VERSION ""

NS_ :

BS_:

BU_: VMCU TECU OBDScanT2 IC3 EMS ECUspare2 ECUspare1 DACU CIOM BBM

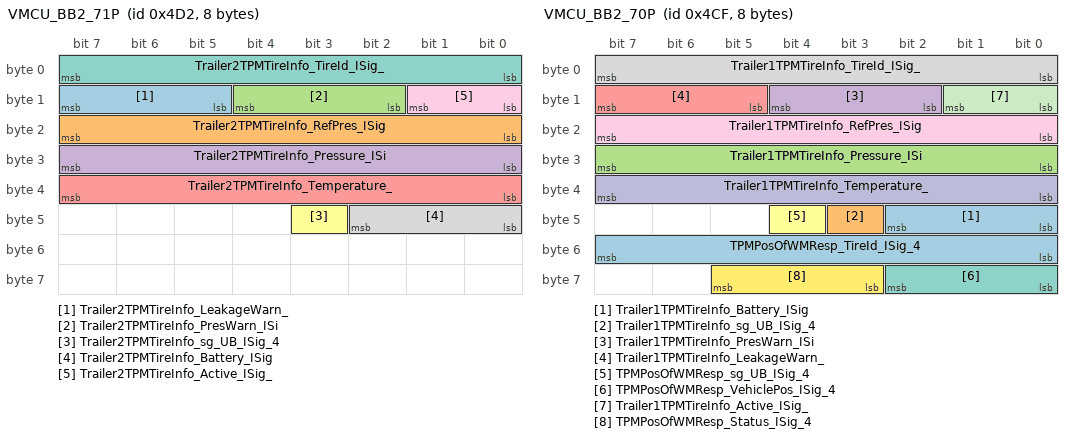
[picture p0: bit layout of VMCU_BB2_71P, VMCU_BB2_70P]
BO_ 1234 VMCU_BB2_71P: 8 VMCU
 SG_ Trailer2TPMTireInfo_LeakageWarn_ : 13|3@1+ (1,0) [0|0] ""  IC3
 SG_ Trailer2TPMTireInfo_RefPres_ISig : 16|8@1+ (10,0) [0|2550] "kPa"  IC3
 SG_ Trailer2TPMTireInfo_PresWarn_ISi : 10|3@1+ (1,0) [0|0] ""  IC3
 SG_ Trailer2TPMTireInfo_Pressure_ISi : 24|8@1+ (10,0) [0|2550] "kPa"  IC3
 SG_ Trailer2TPMTireInfo_Temperature_ : 32|8@1+ (1,-50) [-50|205] "DegreeC"  IC3
 SG_ Trailer2TPMTireInfo_sg_UB_ISig_4 : 43|1@1+ (1,0) [0|0] ""  IC3
 SG_ Trailer2TPMTireInfo_TireId_ISig_ : 0|8@1+ (1,0) [0|255] "NotApplicable"  IC3
 SG_ Trailer2TPMTireInfo_Battery_ISig : 40|3@1+ (1,0) [0|0] ""  IC3
 SG_ Trailer2TPMTireInfo_Active_ISig_ : 8|2@1+ (1,0) [0|0] ""  IC3

BO_ 1231 VMCU_BB2_70P: 8 VMCU
 SG_ Trailer1TPMTireInfo_Battery_ISig : 40|3@1+ (1,0) [0|0] ""  IC3
 SG_ Trailer1TPMTireInfo_sg_UB_ISig_4 : 43|1@1+ (1,0) [0|0] ""  IC3
 SG_ Trailer1TPMTireInfo_Pressure_ISi : 24|8@1+ (10,0) [0|2550] "kPa"  IC3
 SG_ Trailer1TPMTireInfo_PresWarn_ISi : 10|3@1+ (1,0) [0|0] ""  IC3
 SG_ Trailer1TPMTireInfo_LeakageWarn_ : 13|3@1+ (1,0) [0|0] ""  IC3
 SG_ TPMPosOfWMResp_sg_UB_ISig_4 : 44|1@1+ (1,0) [0|0] ""  IC3
 SG_ TPMPosOfWMResp_VehiclePos_ISig_4 : 56|3@1+ (1,0) [0|0] ""  IC3
 SG_ Trailer1TPMTireInfo_TireId_ISig_ : 0|8@1+ (1,0) [0|255] "NotApplicable"  IC3
 SG_ Trailer1TPMTireInfo_RefPres_ISig : 16|8@1+ (10,0) [0|2550] "kPa"  IC3
 SG_ Trailer1TPMTireInfo_Temperature_ : 32|8@1+ (1,-50) [-50|205] "DegreeC"  IC3
 SG_ Trailer1TPMTireInfo_Active_ISig_ : 8|2@1+ (1,0) [0|0] ""  IC3
 SG_ TPMPosOfWMResp_Status_ISig_4 : 59|3@1+ (1,0) [0|0] ""  IC3
 SG_ TPMPosOfWMResp_TireId_ISig_4 : 48|8@1+ (1,0) [0|255] "NotApplicable"  IC3

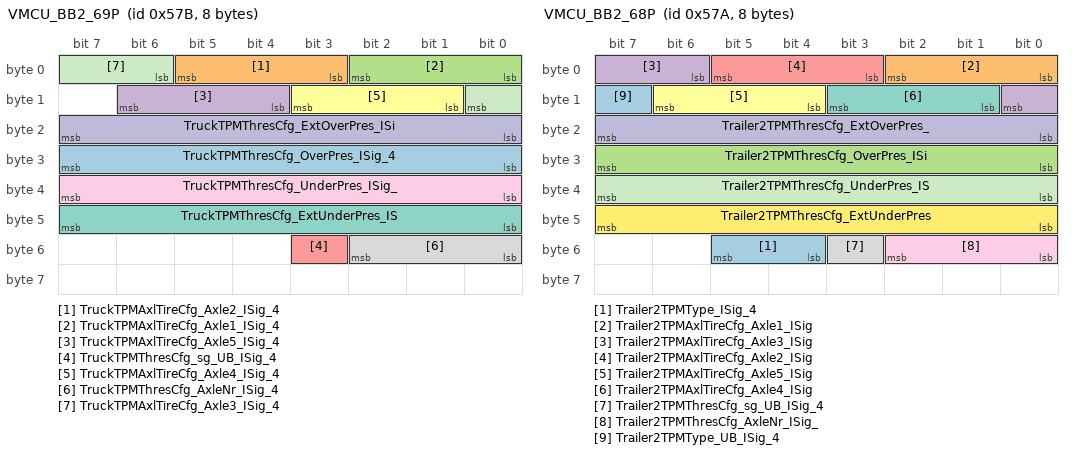
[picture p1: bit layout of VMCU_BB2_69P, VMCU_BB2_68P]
BO_ 1403 VMCU_BB2_69P: 8 VMCU
 SG_ TruckTPMThresCfg_OverPres_ISig_4 : 24|8@1+ (1,-125) [-125|130] "Percent"  IC3
 SG_ TruckTPMAxlTireCfg_Axle2_ISig_4 : 3|3@1+ (1,0) [0|0] ""  IC3
 SG_ TruckTPMAxlTireCfg_Axle1_ISig_4 : 0|3@1+ (1,0) [0|0] ""  IC3
 SG_ TruckTPMAxlTireCfg_Axle5_ISig_4 : 12|3@1+ (1,0) [0|0] ""  IC3
 SG_ TruckTPMThresCfg_sg_UB_ISig_4 : 51|1@1+ (1,0) [0|0] ""  IC3
 SG_ TruckTPMAxlTireCfg_Axle4_ISig_4 : 9|3@1+ (1,0) [0|0] ""  IC3
 SG_ TruckTPMThresCfg_ExtUnderPres_IS : 40|8@1+ (1,-125) [-125|130] "Percent"  IC3
 SG_ TruckTPMThresCfg_AxleNr_ISig_4 : 48|3@1+ (1,0) [0|0] ""  IC3
 SG_ TruckTPMThresCfg_UnderPres_ISig_ : 32|8@1+ (1,-125) [-125|130] "Percent"  IC3
 SG_ TruckTPMThresCfg_ExtOverPres_ISi : 16|8@1+ (1,-125) [-125|130] "Percent"  IC3
 SG_ TruckTPMAxlTireCfg_Axle3_ISig_4 : 6|3@1+ (1,0) [0|0] ""  IC3

BO_ 1402 VMCU_BB2_68P: 8 VMCU
 SG_ Trailer2TPMType_ISig_4 : 52|2@1+ (1,0) [0|0] ""  IC3
 SG_ Trailer2TPMAxlTireCfg_Axle1_ISig : 0|3@1+ (1,0) [0|0] ""  IC3
 SG_ Trailer2TPMThresCfg_OverPres_ISi : 24|8@1+ (1,-125) [-125|130] "Percent"  IC3
 SG_ Trailer2TPMAxlTireCfg_Axle3_ISig : 6|3@1+ (1,0) [0|0] ""  IC3
 SG_ Trailer2TPMAxlTireCfg_Axle2_ISig : 3|3@1+ (1,0) [0|0] ""  IC3
 SG_ Trailer2TPMAxlTireCfg_Axle5_ISig : 12|3@1+ (1,0) [0|0] ""  IC3
 SG_ Trailer2TPMAxlTireCfg_Axle4_ISig : 9|3@1+ (1,0) [0|0] ""  IC3
 SG_ Trailer2TPMThresCfg_sg_UB_ISig_4 : 51|1@1+ (1,0) [0|0] ""  IC3
 SG_ Trailer2TPMThresCfg_AxleNr_ISig_ : 48|3@1+ (1,0) [0|0] ""  IC3
 SG_ Trailer2TPMThresCfg_ExtOverPres_ : 16|8@1+ (1,-125) [-125|130] "Percent"  IC3
 SG_ Trailer2TPMThresCfg_UnderPres_IS : 32|8@1+ (1,-125) [-125|130] "Percent"  IC3
 SG_ Trailer2TPMThresCfg_ExtUnderPres : 40|8@1+ (1,-125) [-125|130] "Percent"  IC3
 SG_ Trailer2TPMType_UB_ISig_4 : 15|1@1+ (1,0) [0|0] ""  IC3

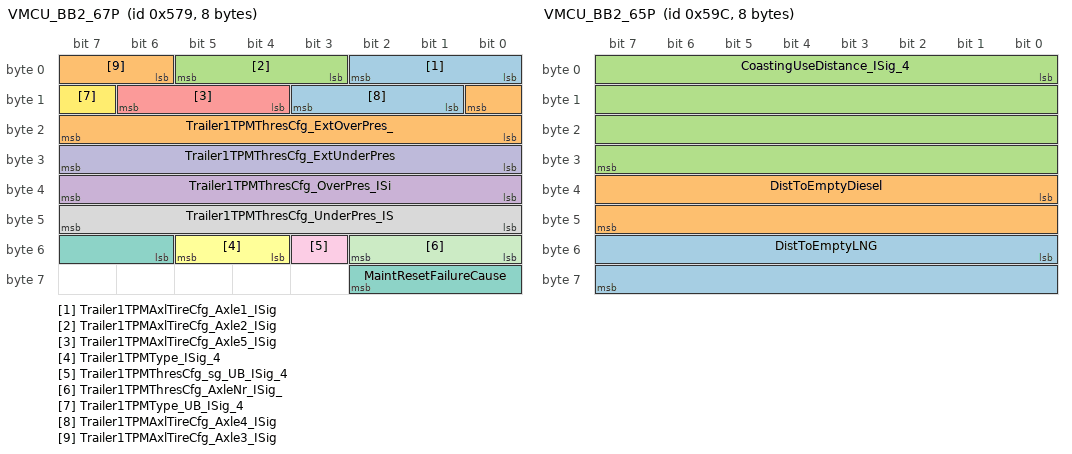
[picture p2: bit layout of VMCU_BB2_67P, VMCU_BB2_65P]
BO_ 1401 VMCU_BB2_67P: 8 VMCU
 SG_ Trailer1TPMAxlTireCfg_Axle1_ISig : 0|3@1+ (1,0) [0|0] ""  IC3
 SG_ Trailer1TPMThresCfg_ExtOverPres_ : 16|8@1+ (1,-125) [-125|130] "Percent"  IC3
 SG_ Trailer1TPMAxlTireCfg_Axle2_ISig : 3|3@1+ (1,0) [0|0] ""  IC3
 SG_ Trailer1TPMThresCfg_OverPres_ISi : 32|8@1+ (1,-125) [-125|130] "Percent"  IC3
 SG_ Trailer1TPMAxlTireCfg_Axle5_ISig : 12|3@1+ (1,0) [0|0] ""  IC3
 SG_ Trailer1TPMType_ISig_4 : 52|2@1+ (1,0) [0|0] ""  IC3
 SG_ MaintResetFailureCause : 54|5@1+ (1,0) [0|0] ""  IC3
 SG_ Trailer1TPMThresCfg_UnderPres_IS : 40|8@1+ (1,-125) [-125|130] "Percent"  IC3
 SG_ Trailer1TPMThresCfg_sg_UB_ISig_4 : 51|1@1+ (1,0) [0|0] ""  IC3
 SG_ Trailer1TPMThresCfg_ExtUnderPres : 24|8@1+ (1,-125) [-125|130] "Percent"  IC3
 SG_ Trailer1TPMThresCfg_AxleNr_ISig_ : 48|3@1+ (1,0) [0|0] ""  IC3
 SG_ Trailer1TPMType_UB_ISig_4 : 15|1@1+ (1,0) [0|0] ""  IC3
 SG_ Trailer1TPMAxlTireCfg_Axle4_ISig : 9|3@1+ (1,0) [0|0] ""  IC3
 SG_ Trailer1TPMAxlTireCfg_Axle3_ISig : 6|3@1+ (1,0) [0|0] ""  IC3

BO_ 1436 VMCU_BB2_65P: 8 VMCU
 SG_ DistToEmptyLNG : 48|16@1+ (1,0) [0|65535] "km"  IC3
 SG_ DistToEmptyDiesel : 32|16@1+ (1,0) [0|65535] "km"  IC3
 SG_ CoastingUseDistance_ISig_4 : 0|32@1+ (10,0) [0|42949672950] "m"  IC3

BO_ 1435 VMCU_BB2_64P: 8 VMCU
 SG_ EngSpeedOverThresholdTime_ISig_4 : 32|32@1+ (1,0) [0|4294967295] "s"  IC3
 SG_ EngLoadOverThresholdDistance_ISi : 0|32@1+ (10,0) [0|42949672950] "m"  IC3

BO_ 1434 VMCU_BB2_63P: 8 VMCU
 SG_ EngineGreenAreaFuel_ISig_4 : 32|32@1+ (0.01,0) [0|42949672.95] "l"  IC3
 SG_ LCCDistance_ISig_4 : 0|32@1+ (10,0) [0|42949672950] "m"  IC3

BO_ 1433 VMCU_BB2_62P: 8 VMCU
 SG_ StopCounter_ISig_4 : 0|32@1+ (1,0) [0|4294967295] ""  IC3
 SG_ OverspeedDistance_ISig_4 : 32|32@1+ (10,0) [0|42949672950] "m"  IC3

BO_ 1432 VMCU_BB2_61P: 8 VMCU
 SG_ RobotizedGboxPowerModeTime_ISig_ : 0|32@1+ (1,0) [0|4294967295] "s"  IC3
 SG_ TotalServiceBrakeCounter_ISig_4 : 32|32@1+ (1,0) [0|4294967295] ""  IC3

BO_ 1431 VMCU_BB2_60P: 8 VMCU
 SG_ RobotizedGboxManualModeTime_ISig : 32|32@1+ (1,0) [0|4294967295] "s"  IC3
 SG_ RobotizedGboxAutoModeTime_ISig_4 : 0|32@1+ (1,0) [0|4294967295] "s"  IC3

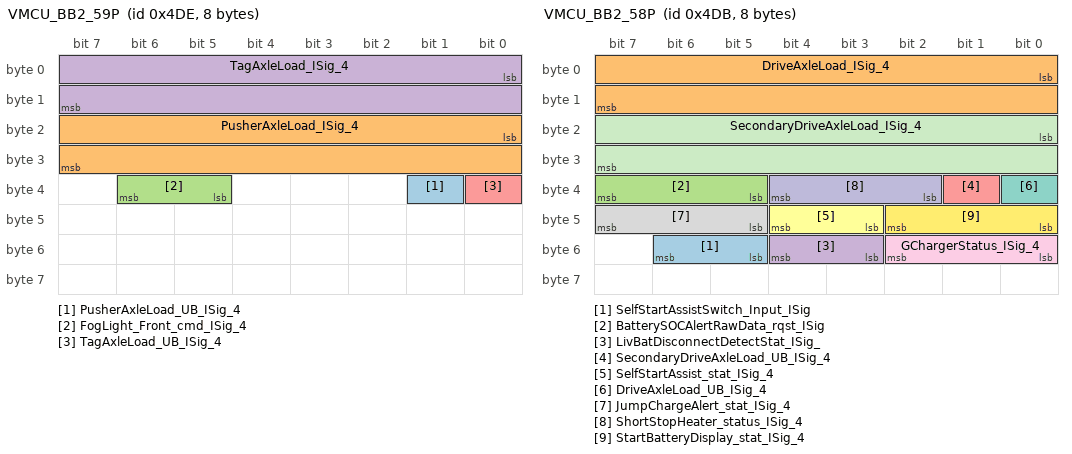
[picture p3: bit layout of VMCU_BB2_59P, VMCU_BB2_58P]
BO_ 1246 VMCU_BB2_59P: 8 VMCU
 SG_ PusherAxleLoad_UB_ISig_4 : 33|1@1+ (1,0) [0|0] ""  TECU,BBM,DACU,IC3
 SG_ PusherAxleLoad_ISig_4 : 16|16@1+ (0.5,0) [0|32767.5] "kg"  TECU,BBM,DACU
 SG_ FogLight_Front_cmd_ISig_4 : 37|2@1+ (1,0) [0|0] ""  BBM
 SG_ TagAxleLoad_ISig_4 : 0|16@1+ (0.5,0) [0|32767.5] "kg"  TECU,DACU,BBM
 SG_ TagAxleLoad_UB_ISig_4 : 32|1@1+ (1,0) [0|0] ""  BBM,IC3,DACU,TECU

BO_ 1243 VMCU_BB2_58P: 8 VMCU
 SG_ SelfStartAssistSwitch_Input_ISig : 53|2@1+ (1,0) [0|0] ""  IC3
 SG_ DriveAxleLoad_ISig_4 : 0|16@1+ (0.5,0) [0|32767.5] "kg"  BBM,DACU,TECU
 SG_ BatterySOCAlertRawData_rqst_ISig : 37|3@1+ (1,0) [0|0] ""  BBM,CIOM
 SG_ LivBatDisconnectDetectStat_ISig_ : 51|2@1+ (1,0) [0|0] ""  IC3
 SG_ SecondaryDriveAxleLoad_UB_ISig_4 : 33|1@1+ (1,0) [0|0] ""  IC3,TECU,BBM,DACU
 SG_ SelfStartAssist_stat_ISig_4 : 43|2@1+ (1,0) [0|0] ""  EMS,IC3
 SG_ DriveAxleLoad_UB_ISig_4 : 32|1@1+ (1,0) [0|0] ""  BBM,IC3,TECU,DACU
 SG_ JumpChargeAlert_stat_ISig_4 : 45|3@1+ (1,0) [0|0] ""  IC3
 SG_ GChargerStatus_ISig_4 : 48|3@1+ (1,0) [0|0] ""  IC3
 SG_ ShortStopHeater_status_ISig_4 : 34|3@1+ (1,0) [0|0] ""  CIOM
 SG_ SecondaryDriveAxleLoad_ISig_4 : 16|16@1+ (0.5,0) [0|32767.5] "kg"  DACU,BBM,TECU
 SG_ StartBatteryDisplay_stat_ISig_4 : 40|3@1+ (1,0) [0|0] ""  IC3

BO_ 1409 VMCU_BB2_57P_HMIIOM_FCM: 8 IC3
 SG_ VMCU_BB2_57P_FCS_581 : 0|64@1+ (1,0) [0|0] ""  VMCU

BO_ 1408 VMCU_BB2_57P_HMIIOM: 15 VMCU
 SG_ MaintService_ServiceCalendarTime : 32|32@1+ (1,-2147483600) [-2147483600|2147483695] "s"  IC3
 SG_ MaintService_EngTimeID_ISig_4_58 : 112|8@1+ (1,0) [0|255] "ID"  IC3
 SG_ MaintService_DistID_ISig_4_580 : 96|8@1+ (1,0) [0|255] "ID"  IC3
 SG_ MaintService_ServiceDistance_ISi : 0|32@1+ (10,-21474836000) [-21474836000|21474836950] "m"  IC3
 SG_ MaintService_ServiceEngineTime_I : 64|32@1+ (1,-2147483600) [-2147483600|2147483695] "s"  IC3
 SG_ MaintService_CalDateID_ISig_4_58 : 104|8@1+ (1,0) [0|255] "ID"  IC3

BO_ 1399 VMCU_BB2_57P_FCM: 8 CIOM
 SG_ VMCU_BB2_57P_FCS_577 : 0|64@1+ (1,0) [0|0] ""  VMCU

BO_ 1398 VMCU_BB2_57P: 15 VMCU
 SG_ MaintService_ServiceEngineT_0000 : 64|32@1+ (1,-2147483600) [-2147483600|2147483695] "s"  CIOM
 SG_ MaintService_EngTimeID_ISig_4_57 : 112|8@1+ (1,0) [0|255] "ID"  CIOM
 SG_ MaintService_DistID_ISig_4_576 : 96|8@1+ (1,0) [0|255] "ID"  CIOM
 SG_ MaintService_ServiceDistanc_0000 : 0|32@1+ (10,-21474836000) [-21474836000|21474836950] "m"  CIOM
 SG_ MaintService_CalDateID_ISig_4_57 : 104|8@1+ (1,0) [0|255] "ID"  CIOM
 SG_ MaintService_ServiceCalenda_0000 : 32|32@1+ (1,-2147483600) [-2147483600|2147483695] "s"  CIOM

BO_ 1428 VMCU_BB2_56P: 8 VMCU
 SG_ EngTrueIdleSpeedTime_ISig_4 : 0|32@1+ (1,0) [0|4294967295] "s"  IC3
 SG_ EngineGreenAreaOutTime_ISig_4 : 32|32@1+ (1,0) [0|4294967295] "s"  IC3

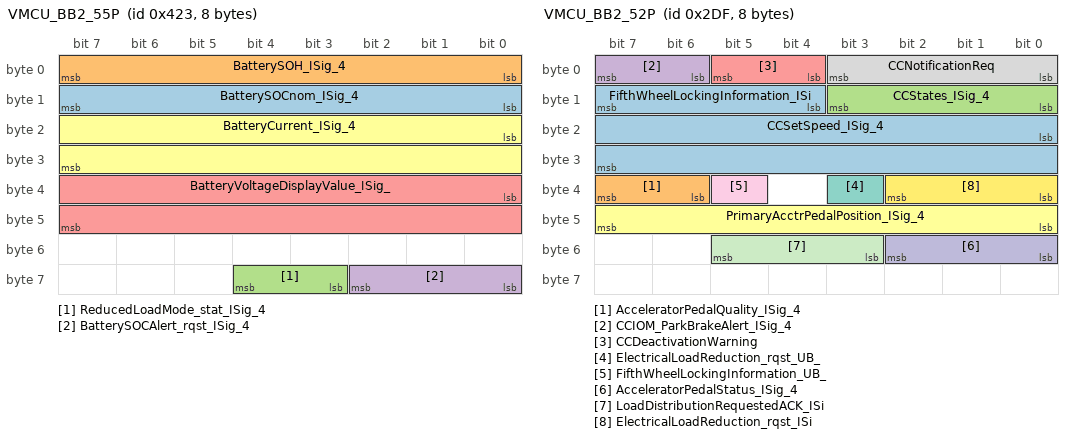
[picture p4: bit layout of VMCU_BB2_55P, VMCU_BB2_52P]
BO_ 1059 VMCU_BB2_55P: 8 VMCU
 SG_ BatterySOCnom_ISig_4 : 8|8@1+ (0.5,0) [0|127.5] "Percent"  IC3
 SG_ BatterySOH_ISig_4 : 0|8@1+ (0.5,0) [0|127.5] "Percent"  IC3
 SG_ ReducedLoadMode_stat_ISig_4 : 59|2@1+ (1,0) [0|0] ""  CIOM
 SG_ BatterySOCAlert_rqst_ISig_4 : 56|3@1+ (1,0) [0|0] ""  IC3,BBM,CIOM
 SG_ BatteryVoltageDisplayValue_ISig_ : 32|16@1+ (0.05,0) [0|3276.75] "V"  IC3,BBM
 SG_ BatteryCurrent_ISig_4 : 16|16@1+ (0.05,-1600) [-1600|1676.75] "A"  EMS,IC3

BO_ 925 VMCU_BB2_54P: 8 VMCU
 SG_ MaintOilQuality : 35|3@1+ (1,0) [0|0] ""  EMS
 SG_ ECSLimpHomeNotification_ISig_4 : 16|3@1+ (1,0) [0|0] ""  IC3
 SG_ MaintenanceResetStatus : 19|3@1+ (1,0) [0|0] ""  IC3
 SG_ FirstAxleLowerPrioSelected_ISig_ : 24|3@1+ (1,0) [0|0] ""  IC3
 SG_ MaintOilReset : 38|2@1+ (1,0) [0|0] ""  EMS
 SG_ RssInhibStartEngine_rqst : 6|2@1+ (1,0) [0|0] ""  IC3
 SG_ PositionLightRequest_status : 2|2@1+ (1,0) [0|0] ""  BBM,IC3
 SG_ ExtraBBTailLiftStatus_ISig_4 : 4|2@1+ (1,0) [0|0] ""  CIOM
 SG_ MaintenanceNotification_ISig_4 : 32|3@1+ (1,0) [0|0] ""  IC3
 SG_ ExtraBBSlidable5thWheelStatus : 0|2@1+ (1,0) [0|0] ""  BBM,CIOM
 SG_ ParkBrakeReleasePossible_stat : 10|2@1+ (1,0) [0|0] ""  TECU,IC3
 SG_ LoadDistributionALDChangeACK_ISi : 48|3@1+ (1,0) [0|0] ""  CIOM,IC3
 SG_ PoorAirPressureInfo_UB : 55|1@1+ (1,0) [0|0] ""  BBM,IC3
 SG_ ParkBrakeWorkshopMode_ISig_4 : 14|2@1+ (1,0) [0|0] ""  IC3
 SG_ ExtraBBContainerUnlockStatus : 46|2@1+ (1,0) [0|0] ""  BBM,CIOM
 SG_ MainBeamRequest_status_ISig_4 : 56|2@1+ (1,0) [0|0] ""  BBM,DACU
 SG_ ExtraBBCraneStatus_ISig_4 : 27|3@1+ (1,0) [0|0] ""  CIOM,BBM
 SG_ AirCompressorStatus : 58|2@1+ (1,0) [0|0] ""  EMS,BBM
 SG_ TrailerABSStatus_ISig_4 : 12|2@1+ (1,0) [0|0] ""  TECU,IC3,EMS,DACU
 SG_ RegenInhibitVehicleHeight_ISig_4 : 22|2@1+ (1,0) [0|0] ""  EMS
 SG_ PoorAirPressureInfo : 51|2@1+ (1,0) [0|0] ""  BBM,IC3
 SG_ FogLightRearRequest_stat : 8|2@1+ (1,0) [0|0] ""  BBM
 SG_ MainBeam_cmd_ISig_4 : 60|3@1+ (1,0) [0|0] ""  BBM
 SG_ FrontParkBrakeOverrideInd_ISig_4 : 53|2@1+ (1,0) [0|0] ""  IC3

BO_ 849 VMCU_BB2_53P: 8 VMCU
 SG_ AuxSwitchBbLoad4_cmd : 14|2@1+ (1,0) [0|0] ""  BBM
 SG_ AuxSwitchBbLoad1_Status_ISig_4 : 0|2@1+ (1,0) [0|0] ""  CIOM,BBM
 SG_ BrakeLightConvoy_rqst_UB_ISig_4 : 45|1@1+ (1,0) [0|0] ""  BBM
 SG_ AuxSwitchBbLoad3_cmd : 12|2@1+ (1,0) [0|0] ""  BBM
 SG_ MainBeam_rqst : 40|3@1+ (1,0) [0|0] ""  IC3
 SG_ BatterySOCTrustLevel_ISig_4 : 56|8@1+ (0.5,0) [0|127.5] "Percent"  IC3
 SG_ AuxSwitchBbLoad4_Status_ISig_4 : 6|2@1+ (1,0) [0|0] ""  CIOM,BBM
 SG_ BrakeLightConvoy_rqst_ISig_4 : 30|2@1+ (1,0) [0|0] ""  BBM
 SG_ DoorWarningLight_cmd_ISig_4 : 38|2@1+ (1,0) [0|0] ""  CIOM
 SG_ BlackOutandConvoyMode_rqst_ISig_ : 35|3@1+ (1,0) [0|0] ""  IC3,DACU,BBM
 SG_ DirIndicatorRqstLights_stat : 32|3@1+ (1,0) [0|0] ""  BBM
 SG_ DippedBeamRequest_status : 24|2@1+ (1,0) [0|0] ""  BBM
 SG_ AuxSwitchBbLoad3_Status_ISig_4 : 4|2@1+ (1,0) [0|0] ""  CIOM,BBM
 SG_ DoorInstepLight_cmd_ISig_4 : 43|2@1+ (1,0) [0|0] ""  CIOM
 SG_ DRLRequest_status : 26|2@1+ (1,0) [0|0] ""  BBM
 SG_ AuxSwitchBbLoad6_Status_ISig_4 : 10|2@1+ (1,0) [0|0] ""  BBM,CIOM
 SG_ AuxSwitchBbLoad2_Status_ISig_4 : 2|2@1+ (1,0) [0|0] ""  CIOM,BBM
 SG_ AuxSwitchBbLoad5_cmd : 16|2@1+ (1,0) [0|0] ""  BBM
 SG_ PBReleaseInhibit_EPBState_ISig_4 : 48|3@1+ (1,0) [0|0] ""  BBM
 SG_ ExtStaticTrailerBrake_Stat_ISig_ : 46|2@1+ (1,0) [0|0] ""  IC3,BBM
 SG_ AuxSwitchBbLoad5_Status_ISig_4 : 8|2@1+ (1,0) [0|0] ""  CIOM,BBM
 SG_ DoubleFrontAxleSteeringWarning_I : 20|2@1+ (1,0) [0|0] ""  IC3
 SG_ AuxSwitchBbLoad6_cmd : 18|2@1+ (1,0) [0|0] ""  BBM
 SG_ AcceleratorPedalTestStatus : 51|3@1+ (1,0) [0|0] ""  IC3

BO_ 735 VMCU_BB2_52P: 8 VMCU
 SG_ CCSetSpeed_ISig_4 : 16|16@1+ (0.00390625,0) [0|255.99609375] "Km_per_h"  TECU,BBM,DACU,IC3
 SG_ AcceleratorPedalQuality_ISig_4 : 38|2@1+ (1,0) [0|0] ""  BBM,IC3
 SG_ CCStates_ISig_4 : 8|4@1+ (1,0) [0|0] ""  CIOM,DACU,IC3,BBM
 SG_ CCIOM_ParkBrakeAlert_ISig_4 : 6|2@1+ (1,0) [0|0] ""  IC3
 SG_ CCDeactivationWarning : 4|2@1+ (1,0) [0|0] ""  DACU
 SG_ PrimaryAcctrPedalPosition_ISig_4 : 40|8@1+ (0.4,0) [0|102] "Percent"  BBM
 SG_ ElectricalLoadReduction_rqst_UB_ : 35|1@1+ (1,0) [0|0] ""  CIOM
 SG_ CCNotificationReq : 0|4@1+ (1,0) [0|0] ""  IC3
 SG_ FifthWheelLockingInformation_UB_ : 37|1@1+ (1,0) [0|0] ""  BBM,IC3
 SG_ AcceleratorPedalStatus_ISig_4 : 48|3@1+ (1,0) [0|0] ""  CIOM,BBM
 SG_ LoadDistributionRequestedACK_ISi : 51|3@1+ (1,0) [0|0] ""  CIOM
 SG_ ElectricalLoadReduction_rqst_ISi : 32|3@1+ (1,0) [0|0] ""  CIOM
 SG_ FifthWheelLockingInformation_ISi : 12|4@1+ (1,0) [0|0] ""  BBM,IC3

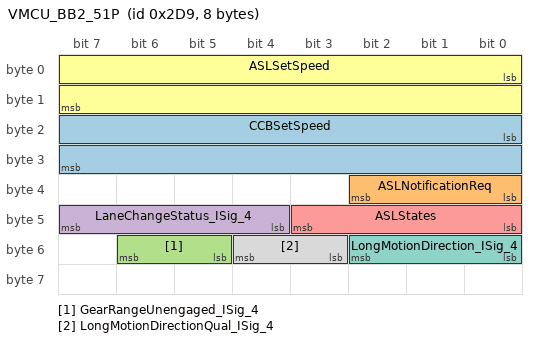
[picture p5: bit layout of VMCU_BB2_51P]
BO_ 729 VMCU_BB2_51P: 8 VMCU
 SG_ CCBSetSpeed : 16|16@1+ (0.00390625,0) [0|255.99609375] "Km_per_h"  DACU,TECU
 SG_ ASLNotificationReq : 32|3@1+ (1,0) [0|0] ""  IC3
 SG_ GearRangeUnengaged_ISig_4 : 53|2@1+ (1,0) [0|0] ""  IC3
 SG_ LaneChangeStatus_ISig_4 : 44|4@1+ (1,0) [0|0] ""  DACU,IC3
 SG_ ASLStates : 40|4@1+ (1,0) [0|0] ""  CIOM,IC3
 SG_ ASLSetSpeed : 0|16@1+ (0.00390625,0) [0|255.99609375] "Km_per_h"  IC3
 SG_ LongMotionDirection_ISig_4 : 48|3@1+ (1,0) [0|0] ""  BBM,CIOM
 SG_ LongMotionDirectionQual_ISig_4 : 51|2@1+ (1,0) [0|0] ""  CIOM

BO_ 976 VMCU_BB2_34S_FCM: 8 CIOM
 SG_ VMCU_BB2_34S_FCS : 0|64@1+ (1,0) [0|0] ""  VMCU

BO_ 973 VMCU_BB2_34S: 16 VMCU
 SG_ KeyID_KeyAuthEncrypted : 0|128@1+ (1,0) [0|0] ""  CIOM

BO_ 1418 VMCU_BB2_33S_FCM: 8 IC3
 SG_ VMCU_BB2_33S_FCS : 0|64@1+ (1,0) [0|0] ""  VMCU

CM_ SG_ 1246 PusherAxleLoad_ISig_4 "65024 - 65279 Error ; 65280 - 65535 Not available";
CM_ SG_ 1246 TagAxleLoad_ISig_4 "65024 - 65279 Error ; 65280 - 65535 Not available";
CM_ SG_ 1243 DriveAxleLoad_ISig_4 "65024 - 65279 Error ; 65280 - 65535 Not available";
CM_ SG_ 1243 SecondaryDriveAxleLoad_ISig_4 "65024 - 65279 Error ; 65280 - 65535 Not available";
CM_ SG_ 1428 EngTrueIdleSpeedTime_ISig_4 "4294967295 Not available";
CM_ SG_ 1428 EngineGreenAreaOutTime_ISig_4 "4294967295 Not available";
CM_ SG_ 1059 BatterySOCnom_ISig_4 "254 Error ; 255 Not available";
CM_ SG_ 1059 BatterySOH_ISig_4 "254 Error ; 255 Not available";
CM_ SG_ 1059 BatteryVoltageDisplayValue_ISig_ "65024 - 65279 Error ; 65280 - 65535 Not available";
CM_ SG_ 1059 BatteryCurrent_ISig_4 "65024 - 65279 Error ; 65280 - 65535 Not available";
CM_ SG_ 735 CCSetSpeed_ISig_4 "65024 - 65279 Error ; 65280 - 65535 Not available";
CM_ SG_ 729 CCBSetSpeed "65024 - 65279 Error ; 65280 - 65535 Not available";
CM_ SG_ 729 ASLSetSpeed "65024 - 65279 Error ; 65280 - 65535 Not available";
BA_DEF_ BO_  "GenMsgStartDelayTime" INT 0 0;
BA_DEF_ BO_  "GenMsgDelayTime" INT 0 0;
BA_DEF_ BO_  "GenMsgCycleTime" INT 0 0;
BA_DEF_ BO_  "GenMsgSendType" ENUM  "Cyclic","NotUsed","NotUsed","NotUsed","NotUsed","NotUsed","NotUsed","IfActive","NoMsgSendType","NotUsed";
BA_DEF_ SG_  "GenSigStartValue" INT 0 0;
BA_DEF_ SG_  "GenSigCycleTimeActive" INT 0 0;
BA_DEF_ SG_  "GenSigCycleTime" INT 0 0;
BA_DEF_ SG_  "GenSigSendType" ENUM  "Cyclic","OnWrite","OnWriteWithRepetition","OnChange","OnChangeWithRepetition","IfActive","IfActiveWithRepetition","NoSigSendType","NotUsed","NotUsed","NotUsed","NotUsed","NotUsed";
BA_DEF_ BO_  "VFrameFormat" ENUM  "StandardCAN","ExtendedCAN","reserved","J1939PG";
BA_DEF_ SG_  "SigType" ENUM  "Default","Range","RangeSigned","ASCII","Discrete","Control","ReferencePGN","DTC","StringDelimiter","StringLength","StringLengthControl";
BA_DEF_ SG_  "SeToolVersion_SIGNAL" STRING ;
BA_DEF_ SG_  "SeToolUniqueID_SIGNAL" STRING ;
BA_DEF_ SG_  "SeToolOwnerSigGroup_SIGNAL" STRING ;
BA_DEF_ SG_  "SeToolOwnerSigGroupID_SIGNAL" STRING ;
BA_DEF_ SG_  "SeToolName_SIGNAL" STRING ;
BA_DEF_ SG_  "SeToolItemID_SIGNAL" STRING ;
BA_DEF_ SG_  "SeToolAncestorID_SIGNAL" STRING ;
BA_DEF_ SG_  "Platform_VMCU1_Sig" ENUM  "No","Yes";
BA_DEF_ BO_  "NmAsrMessage" ENUM  "No","Yes";
BA_DEF_ SG_  "NeedsUpdateBit" ENUM  "No","Yes";
BA_DEF_ SG_  "MmAnSignal" ENUM  "No","Yes";
BA_DEF_ SG_  "GenSigMaxLatency" INT 0 65535;
BA_DEF_ SG_  "GenSigILSupport" ENUM  "Yes","No";
BA_DEF_ BO_  "GenMsgRequestable" INT 0 1;
BA_DEF_ BO_  "GenMsgILSupport" ENUM  "No","Yes";
BA_DEF_ BO_  "DiagUUDTResponse" ENUM  "No","Yes";
BA_DEF_ BO_  "DiagState" ENUM  "No","Yes";
BA_DEF_ BO_  "DiagResponse" ENUM  "No","Yes";
BA_DEF_ BO_  "DiagRequest" ENUM  "No","Yes";
BA_DEF_ BO_  "DiagConnection" HEX 0 65535;
BA_DEF_ BO_  "CanTpSTmin" INT 0 255;
BA_DEF_ BO_  "CanTpFcFrameId" HEX 0 2147483647;
BA_DEF_ BO_  "CanTpBs" INT 0 255;
BA_DEF_ SG_  "SystemSignalLongSymbol" STRING ;
BA_DEF_REL_ BU_SG_REL_  "GenSigTimeoutTime" INT 0 65535;
BA_DEF_REL_ BU_SG_REL_  "GenSigFirstTimeoutTime" INT 0 65535;
BA_DEF_DEF_  "GenMsgStartDelayTime" 0;
BA_DEF_DEF_  "GenMsgDelayTime" 0;
BA_DEF_DEF_  "GenMsgCycleTime" 0;
BA_DEF_DEF_  "GenMsgSendType" "Cyclic";
BA_DEF_DEF_  "GenSigStartValue" 0;
BA_DEF_DEF_  "GenSigCycleTimeActive" 0;
BA_DEF_DEF_  "GenSigCycleTime" 0;
BA_DEF_DEF_  "GenSigSendType" "Cyclic";
BA_DEF_DEF_  "VFrameFormat" "ExtendedCAN";
BA_DEF_DEF_  "SigType" "Default";
BA_DEF_DEF_  "SeToolVersion_SIGNAL" "";
BA_DEF_DEF_  "SeToolUniqueID_SIGNAL" "";
BA_DEF_DEF_  "SeToolOwnerSigGroup_SIGNAL" "";
BA_DEF_DEF_  "SeToolOwnerSigGroupID_SIGNAL" "";
BA_DEF_DEF_  "SeToolName_SIGNAL" "";
BA_DEF_DEF_  "SeToolItemID_SIGNAL" "";
BA_DEF_DEF_  "SeToolAncestorID_SIGNAL" "";
BA_DEF_DEF_  "Platform_VMCU1_Sig" "No";
BA_DEF_DEF_  "NmAsrMessage" "No";
BA_DEF_DEF_  "NeedsUpdateBit" "No";
BA_DEF_DEF_  "MmAnSignal" "No";
BA_DEF_DEF_  "GenSigMaxLatency" 0;
BA_DEF_DEF_  "GenSigILSupport" "Yes";
BA_DEF_DEF_  "GenMsgRequestable" 1;
BA_DEF_DEF_  "GenMsgILSupport" "Yes";
BA_DEF_DEF_  "DiagUUDTResponse" "No";
BA_DEF_DEF_  "DiagState" "No";
BA_DEF_DEF_  "DiagResponse" "No";
BA_DEF_DEF_  "DiagRequest" "No";
BA_DEF_DEF_  "DiagConnection" 0;
BA_DEF_DEF_  "CanTpSTmin" 0;
BA_DEF_DEF_  "CanTpFcFrameId" 2147483647;
BA_DEF_DEF_  "CanTpBs" 255;
BA_DEF_DEF_REL_ "GenSigTimeoutTime" 0;
BA_DEF_DEF_REL_ "GenSigFirstTimeoutTime" 0;
BA_DEF_DEF_  "SystemSignalLongSymbol" "";
BA_ "VFrameFormat" BO_ 1234 0;
BA_ "GenMsgCycleTime" BO_ 1234 200;
BA_ "GenMsgStartDelayTime" BO_ 1234 120;
BA_ "VFrameFormat" BO_ 1231 0;
BA_ "GenMsgCycleTime" BO_ 1231 200;
BA_ "GenMsgStartDelayTime" BO_ 1231 140;
BA_ "VFrameFormat" BO_ 1403 0;
BA_ "GenMsgCycleTime" BO_ 1403 1000;
BA_ "GenMsgStartDelayTime" BO_ 1403 280;
BA_ "VFrameFormat" BO_ 1402 0;
BA_ "GenMsgCycleTime" BO_ 1402 1000;
BA_ "GenMsgStartDelayTime" BO_ 1402 320;
BA_ "VFrameFormat" BO_ 1401 0;
BA_ "GenMsgCycleTime" BO_ 1401 1000;
BA_ "GenMsgStartDelayTime" BO_ 1401 350;
BA_ "VFrameFormat" BO_ 1436 0;
BA_ "GenMsgCycleTime" BO_ 1436 1000;
BA_ "GenMsgStartDelayTime" BO_ 1436 345;
BA_ "VFrameFormat" BO_ 1435 0;
BA_ "GenMsgCycleTime" BO_ 1435 1000;
BA_ "GenMsgStartDelayTime" BO_ 1435 230;
BA_ "VFrameFormat" BO_ 1434 0;
BA_ "GenMsgCycleTime" BO_ 1434 1000;
BA_ "GenMsgStartDelayTime" BO_ 1434 155;
BA_ "VFrameFormat" BO_ 1433 0;
BA_ "GenMsgCycleTime" BO_ 1433 1000;
BA_ "GenMsgStartDelayTime" BO_ 1433 110;
BA_ "VFrameFormat" BO_ 1432 0;
BA_ "GenMsgCycleTime" BO_ 1432 1000;
BA_ "GenMsgStartDelayTime" BO_ 1432 720;
BA_ "VFrameFormat" BO_ 1431 0;
BA_ "GenMsgCycleTime" BO_ 1431 1000;
BA_ "GenMsgStartDelayTime" BO_ 1431 680;
BA_ "VFrameFormat" BO_ 1246 0;
BA_ "GenMsgCycleTime" BO_ 1246 250;
BA_ "GenMsgStartDelayTime" BO_ 1246 105;
BA_ "VFrameFormat" BO_ 1243 0;
BA_ "GenMsgCycleTime" BO_ 1243 250;
BA_ "GenMsgStartDelayTime" BO_ 1243 75;
BA_ "GenMsgILSupport" BO_ 1409 0;
BA_ "VFrameFormat" BO_ 1409 0;
BA_ "GenMsgSendType" BO_ 1409 8;
BA_ "CanTpFcFrameId" BO_ 1408 1409;
BA_ "VFrameFormat" BO_ 1408 0;
BA_ "GenMsgCycleTime" BO_ 1408 1000;
BA_ "GenMsgStartDelayTime" BO_ 1408 200;
BA_ "GenMsgILSupport" BO_ 1399 0;
BA_ "VFrameFormat" BO_ 1399 0;
BA_ "GenMsgSendType" BO_ 1399 8;
BA_ "CanTpFcFrameId" BO_ 1398 1399;
BA_ "VFrameFormat" BO_ 1398 0;
BA_ "GenMsgCycleTime" BO_ 1398 1000;
BA_ "GenMsgStartDelayTime" BO_ 1398 175;
BA_ "VFrameFormat" BO_ 1428 0;
BA_ "GenMsgCycleTime" BO_ 1428 1000;
BA_ "GenMsgStartDelayTime" BO_ 1428 170;
BA_ "VFrameFormat" BO_ 1059 0;
BA_ "GenMsgCycleTime" BO_ 1059 150;
BA_ "GenMsgStartDelayTime" BO_ 1059 65;
BA_ "VFrameFormat" BO_ 925 0;
BA_ "GenMsgCycleTime" BO_ 925 75;
BA_ "GenMsgStartDelayTime" BO_ 925 20;
BA_ "VFrameFormat" BO_ 849 0;
BA_ "GenMsgCycleTime" BO_ 849 50;
BA_ "GenMsgStartDelayTime" BO_ 849 15;
BA_ "VFrameFormat" BO_ 735 0;
BA_ "GenMsgCycleTime" BO_ 735 35;
BA_ "VFrameFormat" BO_ 729 0;
BA_ "GenMsgCycleTime" BO_ 729 30;
BA_ "GenMsgStartDelayTime" BO_ 729 15;
BA_ "GenMsgILSupport" BO_ 976 0;
BA_ "VFrameFormat" BO_ 976 0;
BA_ "GenMsgSendType" BO_ 976 8;
BA_ "CanTpFcFrameId" BO_ 973 976;
BA_ "VFrameFormat" BO_ 973 0;
BA_ "GenMsgSendType" BO_ 973 8;
BA_ "GenMsgDelayTime" BO_ 973 80;
BA_ "CanTpSTmin" BO_ 1418 5;
BA_ "GenMsgILSupport" BO_ 1418 0;
BA_ "VFrameFormat" BO_ 1418 0;
BA_ "GenMsgSendType" BO_ 1418 8;
BA_ "GenSigCycleTime" SG_ 1234 Trailer2TPMTireInfo_LeakageWarn_ 100;
BA_ "GenSigCycleTimeActive" SG_ 1234 Trailer2TPMTireInfo_LeakageWarn_ 100;
BA_ "GenSigStartValue" SG_ 1234 Trailer2TPMTireInfo_LeakageWarn_ 7;
BA_ "NeedsUpdateBit" SG_ 1234 Trailer2TPMTireInfo_LeakageWarn_ 1;
BA_ "Platform_VMCU1_Sig" SG_ 1234 Trailer2TPMTireInfo_LeakageWarn_ 1;
BA_ "SystemSignalLongSymbol" SG_ 1234 Trailer2TPMTireInfo_LeakageWarn_ "Trailer2TPMTireInfo_LeakageWarn_ISig_4";
BA_ "GenSigCycleTime" SG_ 1234 Trailer2TPMTireInfo_RefPres_ISig 100;
BA_ "GenSigCycleTimeActive" SG_ 1234 Trailer2TPMTireInfo_RefPres_ISig 100;
BA_ "GenSigStartValue" SG_ 1234 Trailer2TPMTireInfo_RefPres_ISig 255;
BA_ "NeedsUpdateBit" SG_ 1234 Trailer2TPMTireInfo_RefPres_ISig 1;
BA_ "Platform_VMCU1_Sig" SG_ 1234 Trailer2TPMTireInfo_RefPres_ISig 1;
BA_ "SystemSignalLongSymbol" SG_ 1234 Trailer2TPMTireInfo_RefPres_ISig "Trailer2TPMTireInfo_RefPres_ISig_4";
BA_ "GenSigCycleTime" SG_ 1234 Trailer2TPMTireInfo_PresWarn_ISi 100;
BA_ "GenSigCycleTimeActive" SG_ 1234 Trailer2TPMTireInfo_PresWarn_ISi 100;
BA_ "GenSigStartValue" SG_ 1234 Trailer2TPMTireInfo_PresWarn_ISi 7;
BA_ "NeedsUpdateBit" SG_ 1234 Trailer2TPMTireInfo_PresWarn_ISi 1;
BA_ "Platform_VMCU1_Sig" SG_ 1234 Trailer2TPMTireInfo_PresWarn_ISi 1;
BA_ "SystemSignalLongSymbol" SG_ 1234 Trailer2TPMTireInfo_PresWarn_ISi "Trailer2TPMTireInfo_PresWarn_ISig_4";
BA_ "GenSigCycleTime" SG_ 1234 Trailer2TPMTireInfo_Pressure_ISi 100;
BA_ "GenSigCycleTimeActive" SG_ 1234 Trailer2TPMTireInfo_Pressure_ISi 100;
BA_ "GenSigStartValue" SG_ 1234 Trailer2TPMTireInfo_Pressure_ISi 255;
BA_ "NeedsUpdateBit" SG_ 1234 Trailer2TPMTireInfo_Pressure_ISi 1;
BA_ "Platform_VMCU1_Sig" SG_ 1234 Trailer2TPMTireInfo_Pressure_ISi 1;
BA_ "SystemSignalLongSymbol" SG_ 1234 Trailer2TPMTireInfo_Pressure_ISi "Trailer2TPMTireInfo_Pressure_ISig_4";
BA_ "GenSigCycleTime" SG_ 1234 Trailer2TPMTireInfo_Temperature_ 100;
BA_ "GenSigCycleTimeActive" SG_ 1234 Trailer2TPMTireInfo_Temperature_ 100;
BA_ "GenSigStartValue" SG_ 1234 Trailer2TPMTireInfo_Temperature_ 255;
BA_ "NeedsUpdateBit" SG_ 1234 Trailer2TPMTireInfo_Temperature_ 1;
BA_ "Platform_VMCU1_Sig" SG_ 1234 Trailer2TPMTireInfo_Temperature_ 1;
BA_ "SystemSignalLongSymbol" SG_ 1234 Trailer2TPMTireInfo_Temperature_ "Trailer2TPMTireInfo_Temperature_ISig_4";
BA_ "GenSigSendType" SG_ 1234 Trailer2TPMTireInfo_sg_UB_ISig_4 7;
BA_ "GenSigCycleTime" SG_ 1234 Trailer2TPMTireInfo_sg_UB_ISig_4 100;
BA_ "GenSigCycleTimeActive" SG_ 1234 Trailer2TPMTireInfo_sg_UB_ISig_4 100;
BA_ "Platform_VMCU1_Sig" SG_ 1234 Trailer2TPMTireInfo_sg_UB_ISig_4 1;
BA_ "GenSigCycleTime" SG_ 1234 Trailer2TPMTireInfo_TireId_ISig_ 100;
BA_ "GenSigCycleTimeActive" SG_ 1234 Trailer2TPMTireInfo_TireId_ISig_ 100;
BA_ "NeedsUpdateBit" SG_ 1234 Trailer2TPMTireInfo_TireId_ISig_ 1;
BA_ "Platform_VMCU1_Sig" SG_ 1234 Trailer2TPMTireInfo_TireId_ISig_ 1;
BA_ "SystemSignalLongSymbol" SG_ 1234 Trailer2TPMTireInfo_TireId_ISig_ "Trailer2TPMTireInfo_TireId_ISig_4";
BA_ "GenSigCycleTime" SG_ 1234 Trailer2TPMTireInfo_Battery_ISig 100;
BA_ "GenSigCycleTimeActive" SG_ 1234 Trailer2TPMTireInfo_Battery_ISig 100;
BA_ "GenSigStartValue" SG_ 1234 Trailer2TPMTireInfo_Battery_ISig 7;
BA_ "NeedsUpdateBit" SG_ 1234 Trailer2TPMTireInfo_Battery_ISig 1;
BA_ "Platform_VMCU1_Sig" SG_ 1234 Trailer2TPMTireInfo_Battery_ISig 1;
BA_ "SystemSignalLongSymbol" SG_ 1234 Trailer2TPMTireInfo_Battery_ISig "Trailer2TPMTireInfo_Battery_ISig_4";
BA_ "GenSigCycleTime" SG_ 1234 Trailer2TPMTireInfo_Active_ISig_ 100;
BA_ "GenSigCycleTimeActive" SG_ 1234 Trailer2TPMTireInfo_Active_ISig_ 100;
BA_ "GenSigStartValue" SG_ 1234 Trailer2TPMTireInfo_Active_ISig_ 3;
BA_ "NeedsUpdateBit" SG_ 1234 Trailer2TPMTireInfo_Active_ISig_ 1;
BA_ "Platform_VMCU1_Sig" SG_ 1234 Trailer2TPMTireInfo_Active_ISig_ 1;
BA_ "SystemSignalLongSymbol" SG_ 1234 Trailer2TPMTireInfo_Active_ISig_ "Trailer2TPMTireInfo_Active_ISig_4";
BA_ "GenSigCycleTime" SG_ 1231 Trailer1TPMTireInfo_Battery_ISig 100;
BA_ "GenSigCycleTimeActive" SG_ 1231 Trailer1TPMTireInfo_Battery_ISig 100;
BA_ "GenSigStartValue" SG_ 1231 Trailer1TPMTireInfo_Battery_ISig 7;
BA_ "NeedsUpdateBit" SG_ 1231 Trailer1TPMTireInfo_Battery_ISig 1;
BA_ "Platform_VMCU1_Sig" SG_ 1231 Trailer1TPMTireInfo_Battery_ISig 1;
BA_ "SystemSignalLongSymbol" SG_ 1231 Trailer1TPMTireInfo_Battery_ISig "Trailer1TPMTireInfo_Battery_ISig_4";
BA_ "GenSigSendType" SG_ 1231 Trailer1TPMTireInfo_sg_UB_ISig_4 7;
BA_ "GenSigCycleTime" SG_ 1231 Trailer1TPMTireInfo_sg_UB_ISig_4 100;
BA_ "GenSigCycleTimeActive" SG_ 1231 Trailer1TPMTireInfo_sg_UB_ISig_4 100;
BA_ "Platform_VMCU1_Sig" SG_ 1231 Trailer1TPMTireInfo_sg_UB_ISig_4 1;
BA_ "GenSigCycleTime" SG_ 1231 Trailer1TPMTireInfo_Pressure_ISi 100;
BA_ "GenSigCycleTimeActive" SG_ 1231 Trailer1TPMTireInfo_Pressure_ISi 100;
BA_ "GenSigStartValue" SG_ 1231 Trailer1TPMTireInfo_Pressure_ISi 255;
BA_ "NeedsUpdateBit" SG_ 1231 Trailer1TPMTireInfo_Pressure_ISi 1;
BA_ "Platform_VMCU1_Sig" SG_ 1231 Trailer1TPMTireInfo_Pressure_ISi 1;
BA_ "SystemSignalLongSymbol" SG_ 1231 Trailer1TPMTireInfo_Pressure_ISi "Trailer1TPMTireInfo_Pressure_ISig_4";
BA_ "GenSigCycleTime" SG_ 1231 Trailer1TPMTireInfo_PresWarn_ISi 100;
BA_ "GenSigCycleTimeActive" SG_ 1231 Trailer1TPMTireInfo_PresWarn_ISi 100;
BA_ "GenSigStartValue" SG_ 1231 Trailer1TPMTireInfo_PresWarn_ISi 7;
BA_ "NeedsUpdateBit" SG_ 1231 Trailer1TPMTireInfo_PresWarn_ISi 1;
BA_ "Platform_VMCU1_Sig" SG_ 1231 Trailer1TPMTireInfo_PresWarn_ISi 1;
BA_ "SystemSignalLongSymbol" SG_ 1231 Trailer1TPMTireInfo_PresWarn_ISi "Trailer1TPMTireInfo_PresWarn_ISig_4";
BA_ "GenSigCycleTime" SG_ 1231 Trailer1TPMTireInfo_LeakageWarn_ 100;
BA_ "GenSigCycleTimeActive" SG_ 1231 Trailer1TPMTireInfo_LeakageWarn_ 100;
BA_ "GenSigStartValue" SG_ 1231 Trailer1TPMTireInfo_LeakageWarn_ 7;
BA_ "NeedsUpdateBit" SG_ 1231 Trailer1TPMTireInfo_LeakageWarn_ 1;
BA_ "Platform_VMCU1_Sig" SG_ 1231 Trailer1TPMTireInfo_LeakageWarn_ 1;
BA_ "SystemSignalLongSymbol" SG_ 1231 Trailer1TPMTireInfo_LeakageWarn_ "Trailer1TPMTireInfo_LeakageWarn_ISig_4";
BA_ "GenSigSendType" SG_ 1231 TPMPosOfWMResp_sg_UB_ISig_4 7;
BA_ "GenSigCycleTime" SG_ 1231 TPMPosOfWMResp_sg_UB_ISig_4 100;
BA_ "GenSigCycleTimeActive" SG_ 1231 TPMPosOfWMResp_sg_UB_ISig_4 100;
BA_ "Platform_VMCU1_Sig" SG_ 1231 TPMPosOfWMResp_sg_UB_ISig_4 1;
BA_ "GenSigCycleTime" SG_ 1231 TPMPosOfWMResp_VehiclePos_ISig_4 100;
BA_ "GenSigCycleTimeActive" SG_ 1231 TPMPosOfWMResp_VehiclePos_ISig_4 100;
BA_ "GenSigStartValue" SG_ 1231 TPMPosOfWMResp_VehiclePos_ISig_4 7;
BA_ "NeedsUpdateBit" SG_ 1231 TPMPosOfWMResp_VehiclePos_ISig_4 1;
BA_ "Platform_VMCU1_Sig" SG_ 1231 TPMPosOfWMResp_VehiclePos_ISig_4 1;
BA_ "GenSigCycleTime" SG_ 1231 Trailer1TPMTireInfo_TireId_ISig_ 100;
BA_ "GenSigCycleTimeActive" SG_ 1231 Trailer1TPMTireInfo_TireId_ISig_ 100;
BA_ "NeedsUpdateBit" SG_ 1231 Trailer1TPMTireInfo_TireId_ISig_ 1;
BA_ "Platform_VMCU1_Sig" SG_ 1231 Trailer1TPMTireInfo_TireId_ISig_ 1;
BA_ "SystemSignalLongSymbol" SG_ 1231 Trailer1TPMTireInfo_TireId_ISig_ "Trailer1TPMTireInfo_TireId_ISig_4";
BA_ "GenSigCycleTime" SG_ 1231 Trailer1TPMTireInfo_RefPres_ISig 100;
BA_ "GenSigCycleTimeActive" SG_ 1231 Trailer1TPMTireInfo_RefPres_ISig 100;
BA_ "GenSigStartValue" SG_ 1231 Trailer1TPMTireInfo_RefPres_ISig 255;
BA_ "NeedsUpdateBit" SG_ 1231 Trailer1TPMTireInfo_RefPres_ISig 1;
BA_ "Platform_VMCU1_Sig" SG_ 1231 Trailer1TPMTireInfo_RefPres_ISig 1;
BA_ "SystemSignalLongSymbol" SG_ 1231 Trailer1TPMTireInfo_RefPres_ISig "Trailer1TPMTireInfo_RefPres_ISig_4";
BA_ "GenSigCycleTime" SG_ 1231 Trailer1TPMTireInfo_Temperature_ 100;
BA_ "GenSigCycleTimeActive" SG_ 1231 Trailer1TPMTireInfo_Temperature_ 100;
BA_ "GenSigStartValue" SG_ 1231 Trailer1TPMTireInfo_Temperature_ 255;
BA_ "NeedsUpdateBit" SG_ 1231 Trailer1TPMTireInfo_Temperature_ 1;
BA_ "Platform_VMCU1_Sig" SG_ 1231 Trailer1TPMTireInfo_Temperature_ 1;
BA_ "SystemSignalLongSymbol" SG_ 1231 Trailer1TPMTireInfo_Temperature_ "Trailer1TPMTireInfo_Temperature_ISig_4";
BA_ "GenSigCycleTime" SG_ 1231 Trailer1TPMTireInfo_Active_ISig_ 100;
BA_ "GenSigCycleTimeActive" SG_ 1231 Trailer1TPMTireInfo_Active_ISig_ 100;
BA_ "GenSigStartValue" SG_ 1231 Trailer1TPMTireInfo_Active_ISig_ 3;
BA_ "NeedsUpdateBit" SG_ 1231 Trailer1TPMTireInfo_Active_ISig_ 1;
BA_ "Platform_VMCU1_Sig" SG_ 1231 Trailer1TPMTireInfo_Active_ISig_ 1;
BA_ "SystemSignalLongSymbol" SG_ 1231 Trailer1TPMTireInfo_Active_ISig_ "Trailer1TPMTireInfo_Active_ISig_4";
BA_ "GenSigCycleTime" SG_ 1231 TPMPosOfWMResp_Status_ISig_4 100;
BA_ "GenSigCycleTimeActive" SG_ 1231 TPMPosOfWMResp_Status_ISig_4 100;
BA_ "GenSigStartValue" SG_ 1231 TPMPosOfWMResp_Status_ISig_4 7;
BA_ "NeedsUpdateBit" SG_ 1231 TPMPosOfWMResp_Status_ISig_4 1;
BA_ "Platform_VMCU1_Sig" SG_ 1231 TPMPosOfWMResp_Status_ISig_4 1;
BA_ "GenSigCycleTime" SG_ 1231 TPMPosOfWMResp_TireId_ISig_4 100;
BA_ "GenSigCycleTimeActive" SG_ 1231 TPMPosOfWMResp_TireId_ISig_4 100;
BA_ "NeedsUpdateBit" SG_ 1231 TPMPosOfWMResp_TireId_ISig_4 1;
BA_ "Platform_VMCU1_Sig" SG_ 1231 TPMPosOfWMResp_TireId_ISig_4 1;
BA_ "GenSigCycleTime" SG_ 1403 TruckTPMThresCfg_OverPres_ISig_4 100;
BA_ "GenSigCycleTimeActive" SG_ 1403 TruckTPMThresCfg_OverPres_ISig_4 100;
BA_ "GenSigStartValue" SG_ 1403 TruckTPMThresCfg_OverPres_ISig_4 255;
BA_ "NeedsUpdateBit" SG_ 1403 TruckTPMThresCfg_OverPres_ISig_4 1;
BA_ "Platform_VMCU1_Sig" SG_ 1403 TruckTPMThresCfg_OverPres_ISig_4 1;
BA_ "GenSigCycleTime" SG_ 1403 TruckTPMAxlTireCfg_Axle2_ISig_4 100;
BA_ "GenSigCycleTimeActive" SG_ 1403 TruckTPMAxlTireCfg_Axle2_ISig_4 100;
BA_ "GenSigStartValue" SG_ 1403 TruckTPMAxlTireCfg_Axle2_ISig_4 7;
BA_ "Platform_VMCU1_Sig" SG_ 1403 TruckTPMAxlTireCfg_Axle2_ISig_4 1;
BA_ "GenSigCycleTime" SG_ 1403 TruckTPMAxlTireCfg_Axle1_ISig_4 100;
BA_ "GenSigCycleTimeActive" SG_ 1403 TruckTPMAxlTireCfg_Axle1_ISig_4 100;
BA_ "GenSigStartValue" SG_ 1403 TruckTPMAxlTireCfg_Axle1_ISig_4 7;
BA_ "Platform_VMCU1_Sig" SG_ 1403 TruckTPMAxlTireCfg_Axle1_ISig_4 1;
BA_ "GenSigCycleTime" SG_ 1403 TruckTPMAxlTireCfg_Axle5_ISig_4 100;
BA_ "GenSigCycleTimeActive" SG_ 1403 TruckTPMAxlTireCfg_Axle5_ISig_4 100;
BA_ "GenSigStartValue" SG_ 1403 TruckTPMAxlTireCfg_Axle5_ISig_4 7;
BA_ "Platform_VMCU1_Sig" SG_ 1403 TruckTPMAxlTireCfg_Axle5_ISig_4 1;
BA_ "GenSigSendType" SG_ 1403 TruckTPMThresCfg_sg_UB_ISig_4 7;
BA_ "GenSigCycleTime" SG_ 1403 TruckTPMThresCfg_sg_UB_ISig_4 100;
BA_ "GenSigCycleTimeActive" SG_ 1403 TruckTPMThresCfg_sg_UB_ISig_4 100;
BA_ "Platform_VMCU1_Sig" SG_ 1403 TruckTPMThresCfg_sg_UB_ISig_4 1;
BA_ "GenSigCycleTime" SG_ 1403 TruckTPMAxlTireCfg_Axle4_ISig_4 100;
BA_ "GenSigCycleTimeActive" SG_ 1403 TruckTPMAxlTireCfg_Axle4_ISig_4 100;
BA_ "GenSigStartValue" SG_ 1403 TruckTPMAxlTireCfg_Axle4_ISig_4 7;
BA_ "Platform_VMCU1_Sig" SG_ 1403 TruckTPMAxlTireCfg_Axle4_ISig_4 1;
BA_ "GenSigCycleTime" SG_ 1403 TruckTPMThresCfg_ExtUnderPres_IS 100;
BA_ "GenSigCycleTimeActive" SG_ 1403 TruckTPMThresCfg_ExtUnderPres_IS 100;
BA_ "GenSigStartValue" SG_ 1403 TruckTPMThresCfg_ExtUnderPres_IS 255;
BA_ "NeedsUpdateBit" SG_ 1403 TruckTPMThresCfg_ExtUnderPres_IS 1;
BA_ "Platform_VMCU1_Sig" SG_ 1403 TruckTPMThresCfg_ExtUnderPres_IS 1;
BA_ "SystemSignalLongSymbol" SG_ 1403 TruckTPMThresCfg_ExtUnderPres_IS "TruckTPMThresCfg_ExtUnderPres_ISig_4";
BA_ "GenSigCycleTime" SG_ 1403 TruckTPMThresCfg_AxleNr_ISig_4 100;
BA_ "GenSigCycleTimeActive" SG_ 1403 TruckTPMThresCfg_AxleNr_ISig_4 100;
BA_ "GenSigStartValue" SG_ 1403 TruckTPMThresCfg_AxleNr_ISig_4 7;
BA_ "NeedsUpdateBit" SG_ 1403 TruckTPMThresCfg_AxleNr_ISig_4 1;
BA_ "Platform_VMCU1_Sig" SG_ 1403 TruckTPMThresCfg_AxleNr_ISig_4 1;
BA_ "GenSigCycleTime" SG_ 1403 TruckTPMThresCfg_UnderPres_ISig_ 100;
BA_ "GenSigCycleTimeActive" SG_ 1403 TruckTPMThresCfg_UnderPres_ISig_ 100;
BA_ "GenSigStartValue" SG_ 1403 TruckTPMThresCfg_UnderPres_ISig_ 255;
BA_ "NeedsUpdateBit" SG_ 1403 TruckTPMThresCfg_UnderPres_ISig_ 1;
BA_ "Platform_VMCU1_Sig" SG_ 1403 TruckTPMThresCfg_UnderPres_ISig_ 1;
BA_ "SystemSignalLongSymbol" SG_ 1403 TruckTPMThresCfg_UnderPres_ISig_ "TruckTPMThresCfg_UnderPres_ISig_4";
BA_ "GenSigCycleTime" SG_ 1403 TruckTPMThresCfg_ExtOverPres_ISi 100;
BA_ "GenSigCycleTimeActive" SG_ 1403 TruckTPMThresCfg_ExtOverPres_ISi 100;
BA_ "GenSigStartValue" SG_ 1403 TruckTPMThresCfg_ExtOverPres_ISi 255;
BA_ "NeedsUpdateBit" SG_ 1403 TruckTPMThresCfg_ExtOverPres_ISi 1;
BA_ "Platform_VMCU1_Sig" SG_ 1403 TruckTPMThresCfg_ExtOverPres_ISi 1;
BA_ "SystemSignalLongSymbol" SG_ 1403 TruckTPMThresCfg_ExtOverPres_ISi "TruckTPMThresCfg_ExtOverPres_ISig_4";
BA_ "GenSigCycleTime" SG_ 1403 TruckTPMAxlTireCfg_Axle3_ISig_4 100;
BA_ "GenSigCycleTimeActive" SG_ 1403 TruckTPMAxlTireCfg_Axle3_ISig_4 100;
BA_ "GenSigStartValue" SG_ 1403 TruckTPMAxlTireCfg_Axle3_ISig_4 7;
BA_ "Platform_VMCU1_Sig" SG_ 1403 TruckTPMAxlTireCfg_Axle3_ISig_4 1;
BA_ "GenSigCycleTime" SG_ 1402 Trailer2TPMType_ISig_4 100;
BA_ "GenSigCycleTimeActive" SG_ 1402 Trailer2TPMType_ISig_4 100;
BA_ "GenSigStartValue" SG_ 1402 Trailer2TPMType_ISig_4 3;
BA_ "NeedsUpdateBit" SG_ 1402 Trailer2TPMType_ISig_4 1;
BA_ "Platform_VMCU1_Sig" SG_ 1402 Trailer2TPMType_ISig_4 1;
BA_ "GenSigCycleTime" SG_ 1402 Trailer2TPMAxlTireCfg_Axle1_ISig 100;
BA_ "GenSigCycleTimeActive" SG_ 1402 Trailer2TPMAxlTireCfg_Axle1_ISig 100;
BA_ "GenSigStartValue" SG_ 1402 Trailer2TPMAxlTireCfg_Axle1_ISig 7;
BA_ "Platform_VMCU1_Sig" SG_ 1402 Trailer2TPMAxlTireCfg_Axle1_ISig 1;
BA_ "SystemSignalLongSymbol" SG_ 1402 Trailer2TPMAxlTireCfg_Axle1_ISig "Trailer2TPMAxlTireCfg_Axle1_ISig_4";
BA_ "GenSigCycleTime" SG_ 1402 Trailer2TPMThresCfg_OverPres_ISi 100;
BA_ "GenSigCycleTimeActive" SG_ 1402 Trailer2TPMThresCfg_OverPres_ISi 100;
BA_ "GenSigStartValue" SG_ 1402 Trailer2TPMThresCfg_OverPres_ISi 255;
BA_ "NeedsUpdateBit" SG_ 1402 Trailer2TPMThresCfg_OverPres_ISi 1;
BA_ "Platform_VMCU1_Sig" SG_ 1402 Trailer2TPMThresCfg_OverPres_ISi 1;
BA_ "SystemSignalLongSymbol" SG_ 1402 Trailer2TPMThresCfg_OverPres_ISi "Trailer2TPMThresCfg_OverPres_ISig_4";
BA_ "GenSigCycleTime" SG_ 1402 Trailer2TPMAxlTireCfg_Axle3_ISig 100;
BA_ "GenSigCycleTimeActive" SG_ 1402 Trailer2TPMAxlTireCfg_Axle3_ISig 100;
BA_ "GenSigStartValue" SG_ 1402 Trailer2TPMAxlTireCfg_Axle3_ISig 7;
BA_ "Platform_VMCU1_Sig" SG_ 1402 Trailer2TPMAxlTireCfg_Axle3_ISig 1;
BA_ "SystemSignalLongSymbol" SG_ 1402 Trailer2TPMAxlTireCfg_Axle3_ISig "Trailer2TPMAxlTireCfg_Axle3_ISig_4";
BA_ "GenSigCycleTime" SG_ 1402 Trailer2TPMAxlTireCfg_Axle2_ISig 100;
BA_ "GenSigCycleTimeActive" SG_ 1402 Trailer2TPMAxlTireCfg_Axle2_ISig 100;
BA_ "GenSigStartValue" SG_ 1402 Trailer2TPMAxlTireCfg_Axle2_ISig 7;
BA_ "Platform_VMCU1_Sig" SG_ 1402 Trailer2TPMAxlTireCfg_Axle2_ISig 1;
BA_ "SystemSignalLongSymbol" SG_ 1402 Trailer2TPMAxlTireCfg_Axle2_ISig "Trailer2TPMAxlTireCfg_Axle2_ISig_4";
BA_ "GenSigCycleTime" SG_ 1402 Trailer2TPMAxlTireCfg_Axle5_ISig 100;
BA_ "GenSigCycleTimeActive" SG_ 1402 Trailer2TPMAxlTireCfg_Axle5_ISig 100;
BA_ "GenSigStartValue" SG_ 1402 Trailer2TPMAxlTireCfg_Axle5_ISig 7;
BA_ "Platform_VMCU1_Sig" SG_ 1402 Trailer2TPMAxlTireCfg_Axle5_ISig 1;
BA_ "SystemSignalLongSymbol" SG_ 1402 Trailer2TPMAxlTireCfg_Axle5_ISig "Trailer2TPMAxlTireCfg_Axle5_ISig_4";
BA_ "GenSigCycleTime" SG_ 1402 Trailer2TPMAxlTireCfg_Axle4_ISig 100;
BA_ "GenSigCycleTimeActive" SG_ 1402 Trailer2TPMAxlTireCfg_Axle4_ISig 100;
BA_ "GenSigStartValue" SG_ 1402 Trailer2TPMAxlTireCfg_Axle4_ISig 7;
BA_ "Platform_VMCU1_Sig" SG_ 1402 Trailer2TPMAxlTireCfg_Axle4_ISig 1;
BA_ "SystemSignalLongSymbol" SG_ 1402 Trailer2TPMAxlTireCfg_Axle4_ISig "Trailer2TPMAxlTireCfg_Axle4_ISig_4";
BA_ "GenSigSendType" SG_ 1402 Trailer2TPMThresCfg_sg_UB_ISig_4 7;
BA_ "GenSigCycleTime" SG_ 1402 Trailer2TPMThresCfg_sg_UB_ISig_4 100;
BA_ "GenSigCycleTimeActive" SG_ 1402 Trailer2TPMThresCfg_sg_UB_ISig_4 100;
BA_ "Platform_VMCU1_Sig" SG_ 1402 Trailer2TPMThresCfg_sg_UB_ISig_4 1;
BA_ "GenSigCycleTime" SG_ 1402 Trailer2TPMThresCfg_AxleNr_ISig_ 100;
BA_ "GenSigCycleTimeActive" SG_ 1402 Trailer2TPMThresCfg_AxleNr_ISig_ 100;
BA_ "GenSigStartValue" SG_ 1402 Trailer2TPMThresCfg_AxleNr_ISig_ 7;
BA_ "NeedsUpdateBit" SG_ 1402 Trailer2TPMThresCfg_AxleNr_ISig_ 1;
BA_ "Platform_VMCU1_Sig" SG_ 1402 Trailer2TPMThresCfg_AxleNr_ISig_ 1;
BA_ "SystemSignalLongSymbol" SG_ 1402 Trailer2TPMThresCfg_AxleNr_ISig_ "Trailer2TPMThresCfg_AxleNr_ISig_4";
BA_ "GenSigCycleTime" SG_ 1402 Trailer2TPMThresCfg_ExtOverPres_ 100;
BA_ "GenSigCycleTimeActive" SG_ 1402 Trailer2TPMThresCfg_ExtOverPres_ 100;
BA_ "GenSigStartValue" SG_ 1402 Trailer2TPMThresCfg_ExtOverPres_ 255;
BA_ "NeedsUpdateBit" SG_ 1402 Trailer2TPMThresCfg_ExtOverPres_ 1;
BA_ "Platform_VMCU1_Sig" SG_ 1402 Trailer2TPMThresCfg_ExtOverPres_ 1;
BA_ "SystemSignalLongSymbol" SG_ 1402 Trailer2TPMThresCfg_ExtOverPres_ "Trailer2TPMThresCfg_ExtOverPres_ISig_4";
BA_ "GenSigCycleTime" SG_ 1402 Trailer2TPMThresCfg_UnderPres_IS 100;
BA_ "GenSigCycleTimeActive" SG_ 1402 Trailer2TPMThresCfg_UnderPres_IS 100;
BA_ "GenSigStartValue" SG_ 1402 Trailer2TPMThresCfg_UnderPres_IS 255;
BA_ "NeedsUpdateBit" SG_ 1402 Trailer2TPMThresCfg_UnderPres_IS 1;
BA_ "Platform_VMCU1_Sig" SG_ 1402 Trailer2TPMThresCfg_UnderPres_IS 1;
BA_ "SystemSignalLongSymbol" SG_ 1402 Trailer2TPMThresCfg_UnderPres_IS "Trailer2TPMThresCfg_UnderPres_ISig_4";
BA_ "GenSigCycleTime" SG_ 1402 Trailer2TPMThresCfg_ExtUnderPres 100;
BA_ "GenSigCycleTimeActive" SG_ 1402 Trailer2TPMThresCfg_ExtUnderPres 100;
BA_ "GenSigStartValue" SG_ 1402 Trailer2TPMThresCfg_ExtUnderPres 255;
BA_ "NeedsUpdateBit" SG_ 1402 Trailer2TPMThresCfg_ExtUnderPres 1;
BA_ "Platform_VMCU1_Sig" SG_ 1402 Trailer2TPMThresCfg_ExtUnderPres 1;
BA_ "SystemSignalLongSymbol" SG_ 1402 Trailer2TPMThresCfg_ExtUnderPres "Trailer2TPMThresCfg_ExtUnderPres_ISig_4";
BA_ "GenSigSendType" SG_ 1402 Trailer2TPMType_UB_ISig_4 7;
BA_ "Platform_VMCU1_Sig" SG_ 1402 Trailer2TPMType_UB_ISig_4 1;
BA_ "GenSigCycleTime" SG_ 1401 Trailer1TPMAxlTireCfg_Axle1_ISig 100;
BA_ "GenSigCycleTimeActive" SG_ 1401 Trailer1TPMAxlTireCfg_Axle1_ISig 100;
BA_ "GenSigStartValue" SG_ 1401 Trailer1TPMAxlTireCfg_Axle1_ISig 7;
BA_ "Platform_VMCU1_Sig" SG_ 1401 Trailer1TPMAxlTireCfg_Axle1_ISig 1;
BA_ "SystemSignalLongSymbol" SG_ 1401 Trailer1TPMAxlTireCfg_Axle1_ISig "Trailer1TPMAxlTireCfg_Axle1_ISig_4";
BA_ "GenSigCycleTime" SG_ 1401 Trailer1TPMThresCfg_ExtOverPres_ 100;
BA_ "GenSigCycleTimeActive" SG_ 1401 Trailer1TPMThresCfg_ExtOverPres_ 100;
BA_ "GenSigStartValue" SG_ 1401 Trailer1TPMThresCfg_ExtOverPres_ 255;
BA_ "NeedsUpdateBit" SG_ 1401 Trailer1TPMThresCfg_ExtOverPres_ 1;
BA_ "Platform_VMCU1_Sig" SG_ 1401 Trailer1TPMThresCfg_ExtOverPres_ 1;
BA_ "SystemSignalLongSymbol" SG_ 1401 Trailer1TPMThresCfg_ExtOverPres_ "Trailer1TPMThresCfg_ExtOverPres_ISig_4";
BA_ "GenSigCycleTime" SG_ 1401 Trailer1TPMAxlTireCfg_Axle2_ISig 100;
BA_ "GenSigCycleTimeActive" SG_ 1401 Trailer1TPMAxlTireCfg_Axle2_ISig 100;
BA_ "GenSigStartValue" SG_ 1401 Trailer1TPMAxlTireCfg_Axle2_ISig 7;
BA_ "Platform_VMCU1_Sig" SG_ 1401 Trailer1TPMAxlTireCfg_Axle2_ISig 1;
BA_ "SystemSignalLongSymbol" SG_ 1401 Trailer1TPMAxlTireCfg_Axle2_ISig "Trailer1TPMAxlTireCfg_Axle2_ISig_4";
BA_ "GenSigCycleTime" SG_ 1401 Trailer1TPMThresCfg_OverPres_ISi 100;
BA_ "GenSigCycleTimeActive" SG_ 1401 Trailer1TPMThresCfg_OverPres_ISi 100;
BA_ "GenSigStartValue" SG_ 1401 Trailer1TPMThresCfg_OverPres_ISi 255;
BA_ "NeedsUpdateBit" SG_ 1401 Trailer1TPMThresCfg_OverPres_ISi 1;
BA_ "Platform_VMCU1_Sig" SG_ 1401 Trailer1TPMThresCfg_OverPres_ISi 1;
BA_ "SystemSignalLongSymbol" SG_ 1401 Trailer1TPMThresCfg_OverPres_ISi "Trailer1TPMThresCfg_OverPres_ISig_4";
BA_ "GenSigCycleTime" SG_ 1401 Trailer1TPMAxlTireCfg_Axle5_ISig 100;
BA_ "GenSigCycleTimeActive" SG_ 1401 Trailer1TPMAxlTireCfg_Axle5_ISig 100;
BA_ "GenSigStartValue" SG_ 1401 Trailer1TPMAxlTireCfg_Axle5_ISig 7;
BA_ "Platform_VMCU1_Sig" SG_ 1401 Trailer1TPMAxlTireCfg_Axle5_ISig 1;
BA_ "SystemSignalLongSymbol" SG_ 1401 Trailer1TPMAxlTireCfg_Axle5_ISig "Trailer1TPMAxlTireCfg_Axle5_ISig_4";
BA_ "GenSigCycleTime" SG_ 1401 Trailer1TPMType_ISig_4 100;
BA_ "GenSigCycleTimeActive" SG_ 1401 Trailer1TPMType_ISig_4 100;
BA_ "GenSigStartValue" SG_ 1401 Trailer1TPMType_ISig_4 3;
BA_ "NeedsUpdateBit" SG_ 1401 Trailer1TPMType_ISig_4 1;
BA_ "Platform_VMCU1_Sig" SG_ 1401 Trailer1TPMType_ISig_4 1;
BA_ "GenSigCycleTime" SG_ 1401 MaintResetFailureCause 100;
BA_ "GenSigCycleTimeActive" SG_ 1401 MaintResetFailureCause 100;
BA_ "GenSigStartValue" SG_ 1401 MaintResetFailureCause 31;
BA_ "GenSigCycleTime" SG_ 1401 Trailer1TPMThresCfg_UnderPres_IS 100;
BA_ "GenSigCycleTimeActive" SG_ 1401 Trailer1TPMThresCfg_UnderPres_IS 100;
BA_ "GenSigStartValue" SG_ 1401 Trailer1TPMThresCfg_UnderPres_IS 255;
BA_ "NeedsUpdateBit" SG_ 1401 Trailer1TPMThresCfg_UnderPres_IS 1;
BA_ "Platform_VMCU1_Sig" SG_ 1401 Trailer1TPMThresCfg_UnderPres_IS 1;
BA_ "SystemSignalLongSymbol" SG_ 1401 Trailer1TPMThresCfg_UnderPres_IS "Trailer1TPMThresCfg_UnderPres_ISig_4";
BA_ "GenSigSendType" SG_ 1401 Trailer1TPMThresCfg_sg_UB_ISig_4 7;
BA_ "GenSigCycleTime" SG_ 1401 Trailer1TPMThresCfg_sg_UB_ISig_4 100;
BA_ "GenSigCycleTimeActive" SG_ 1401 Trailer1TPMThresCfg_sg_UB_ISig_4 100;
BA_ "Platform_VMCU1_Sig" SG_ 1401 Trailer1TPMThresCfg_sg_UB_ISig_4 1;
BA_ "GenSigCycleTime" SG_ 1401 Trailer1TPMThresCfg_ExtUnderPres 100;
BA_ "GenSigCycleTimeActive" SG_ 1401 Trailer1TPMThresCfg_ExtUnderPres 100;
BA_ "GenSigStartValue" SG_ 1401 Trailer1TPMThresCfg_ExtUnderPres 255;
BA_ "NeedsUpdateBit" SG_ 1401 Trailer1TPMThresCfg_ExtUnderPres 1;
BA_ "Platform_VMCU1_Sig" SG_ 1401 Trailer1TPMThresCfg_ExtUnderPres 1;
BA_ "SystemSignalLongSymbol" SG_ 1401 Trailer1TPMThresCfg_ExtUnderPres "Trailer1TPMThresCfg_ExtUnderPres_ISig_4";
BA_ "GenSigCycleTime" SG_ 1401 Trailer1TPMThresCfg_AxleNr_ISig_ 100;
BA_ "GenSigCycleTimeActive" SG_ 1401 Trailer1TPMThresCfg_AxleNr_ISig_ 100;
BA_ "GenSigStartValue" SG_ 1401 Trailer1TPMThresCfg_AxleNr_ISig_ 7;
BA_ "NeedsUpdateBit" SG_ 1401 Trailer1TPMThresCfg_AxleNr_ISig_ 1;
BA_ "Platform_VMCU1_Sig" SG_ 1401 Trailer1TPMThresCfg_AxleNr_ISig_ 1;
BA_ "SystemSignalLongSymbol" SG_ 1401 Trailer1TPMThresCfg_AxleNr_ISig_ "Trailer1TPMThresCfg_AxleNr_ISig_4";
BA_ "GenSigSendType" SG_ 1401 Trailer1TPMType_UB_ISig_4 7;
BA_ "Platform_VMCU1_Sig" SG_ 1401 Trailer1TPMType_UB_ISig_4 1;
BA_ "GenSigCycleTime" SG_ 1401 Trailer1TPMAxlTireCfg_Axle4_ISig 100;
BA_ "GenSigCycleTimeActive" SG_ 1401 Trailer1TPMAxlTireCfg_Axle4_ISig 100;
BA_ "GenSigStartValue" SG_ 1401 Trailer1TPMAxlTireCfg_Axle4_ISig 7;
BA_ "Platform_VMCU1_Sig" SG_ 1401 Trailer1TPMAxlTireCfg_Axle4_ISig 1;
BA_ "SystemSignalLongSymbol" SG_ 1401 Trailer1TPMAxlTireCfg_Axle4_ISig "Trailer1TPMAxlTireCfg_Axle4_ISig_4";
BA_ "GenSigCycleTime" SG_ 1401 Trailer1TPMAxlTireCfg_Axle3_ISig 100;
BA_ "GenSigCycleTimeActive" SG_ 1401 Trailer1TPMAxlTireCfg_Axle3_ISig 100;
BA_ "GenSigStartValue" SG_ 1401 Trailer1TPMAxlTireCfg_Axle3_ISig 7;
BA_ "Platform_VMCU1_Sig" SG_ 1401 Trailer1TPMAxlTireCfg_Axle3_ISig 1;
BA_ "SystemSignalLongSymbol" SG_ 1401 Trailer1TPMAxlTireCfg_Axle3_ISig "Trailer1TPMAxlTireCfg_Axle3_ISig_4";
BA_ "GenSigCycleTime" SG_ 1436 DistToEmptyLNG 100;
BA_ "GenSigCycleTimeActive" SG_ 1436 DistToEmptyLNG 100;
BA_ "GenSigStartValue" SG_ 1436 DistToEmptyLNG 65535;
BA_ "Platform_VMCU1_Sig" SG_ 1436 DistToEmptyLNG 1;
BA_ "GenSigCycleTime" SG_ 1436 DistToEmptyDiesel 100;
BA_ "GenSigCycleTimeActive" SG_ 1436 DistToEmptyDiesel 100;
BA_ "GenSigStartValue" SG_ 1436 DistToEmptyDiesel 65535;
BA_ "Platform_VMCU1_Sig" SG_ 1436 DistToEmptyDiesel 1;
BA_ "GenSigCycleTime" SG_ 1436 CoastingUseDistance_ISig_4 100;
BA_ "GenSigCycleTimeActive" SG_ 1436 CoastingUseDistance_ISig_4 100;
BA_ "GenSigStartValue" SG_ 1436 CoastingUseDistance_ISig_4 4294967295;
BA_ "Platform_VMCU1_Sig" SG_ 1436 CoastingUseDistance_ISig_4 1;
BA_ "GenSigCycleTime" SG_ 1435 EngSpeedOverThresholdTime_ISig_4 100;
BA_ "GenSigCycleTimeActive" SG_ 1435 EngSpeedOverThresholdTime_ISig_4 100;
BA_ "GenSigStartValue" SG_ 1435 EngSpeedOverThresholdTime_ISig_4 4294967295;
BA_ "Platform_VMCU1_Sig" SG_ 1435 EngSpeedOverThresholdTime_ISig_4 1;
BA_ "GenSigCycleTime" SG_ 1435 EngLoadOverThresholdDistance_ISi 100;
BA_ "GenSigCycleTimeActive" SG_ 1435 EngLoadOverThresholdDistance_ISi 100;
BA_ "GenSigStartValue" SG_ 1435 EngLoadOverThresholdDistance_ISi 4294967295;
BA_ "Platform_VMCU1_Sig" SG_ 1435 EngLoadOverThresholdDistance_ISi 1;
BA_ "SystemSignalLongSymbol" SG_ 1435 EngLoadOverThresholdDistance_ISi "EngLoadOverThresholdDistance_ISig_4";
BA_ "GenSigCycleTime" SG_ 1434 EngineGreenAreaFuel_ISig_4 100;
BA_ "GenSigCycleTimeActive" SG_ 1434 EngineGreenAreaFuel_ISig_4 100;
BA_ "GenSigStartValue" SG_ 1434 EngineGreenAreaFuel_ISig_4 4294967295;
BA_ "Platform_VMCU1_Sig" SG_ 1434 EngineGreenAreaFuel_ISig_4 1;
BA_ "GenSigCycleTime" SG_ 1434 LCCDistance_ISig_4 100;
BA_ "GenSigCycleTimeActive" SG_ 1434 LCCDistance_ISig_4 100;
BA_ "GenSigStartValue" SG_ 1434 LCCDistance_ISig_4 4294967295;
BA_ "Platform_VMCU1_Sig" SG_ 1434 LCCDistance_ISig_4 1;
BA_ "GenSigCycleTime" SG_ 1433 StopCounter_ISig_4 100;
BA_ "GenSigCycleTimeActive" SG_ 1433 StopCounter_ISig_4 100;
BA_ "GenSigStartValue" SG_ 1433 StopCounter_ISig_4 4294967295;
BA_ "Platform_VMCU1_Sig" SG_ 1433 StopCounter_ISig_4 1;
BA_ "GenSigCycleTime" SG_ 1433 OverspeedDistance_ISig_4 100;
BA_ "GenSigCycleTimeActive" SG_ 1433 OverspeedDistance_ISig_4 100;
BA_ "GenSigStartValue" SG_ 1433 OverspeedDistance_ISig_4 4294967295;
BA_ "Platform_VMCU1_Sig" SG_ 1433 OverspeedDistance_ISig_4 1;
BA_ "GenSigCycleTime" SG_ 1432 RobotizedGboxPowerModeTime_ISig_ 100;
BA_ "GenSigCycleTimeActive" SG_ 1432 RobotizedGboxPowerModeTime_ISig_ 100;
BA_ "GenSigStartValue" SG_ 1432 RobotizedGboxPowerModeTime_ISig_ 4294967295;
BA_ "Platform_VMCU1_Sig" SG_ 1432 RobotizedGboxPowerModeTime_ISig_ 1;
BA_ "SystemSignalLongSymbol" SG_ 1432 RobotizedGboxPowerModeTime_ISig_ "RobotizedGboxPowerModeTime_ISig_4";
BA_ "GenSigCycleTime" SG_ 1432 TotalServiceBrakeCounter_ISig_4 100;
BA_ "GenSigCycleTimeActive" SG_ 1432 TotalServiceBrakeCounter_ISig_4 100;
BA_ "GenSigStartValue" SG_ 1432 TotalServiceBrakeCounter_ISig_4 4294967295;
BA_ "Platform_VMCU1_Sig" SG_ 1432 TotalServiceBrakeCounter_ISig_4 1;
BA_ "GenSigCycleTime" SG_ 1431 RobotizedGboxManualModeTime_ISig 100;
BA_ "GenSigCycleTimeActive" SG_ 1431 RobotizedGboxManualModeTime_ISig 100;
BA_ "GenSigStartValue" SG_ 1431 RobotizedGboxManualModeTime_ISig 4294967295;
BA_ "Platform_VMCU1_Sig" SG_ 1431 RobotizedGboxManualModeTime_ISig 1;
BA_ "SystemSignalLongSymbol" SG_ 1431 RobotizedGboxManualModeTime_ISig "RobotizedGboxManualModeTime_ISig_4";
BA_ "GenSigCycleTime" SG_ 1431 RobotizedGboxAutoModeTime_ISig_4 100;
BA_ "GenSigCycleTimeActive" SG_ 1431 RobotizedGboxAutoModeTime_ISig_4 100;
BA_ "GenSigStartValue" SG_ 1431 RobotizedGboxAutoModeTime_ISig_4 4294967295;
BA_ "Platform_VMCU1_Sig" SG_ 1431 RobotizedGboxAutoModeTime_ISig_4 1;
BA_ "GenSigSendType" SG_ 1246 PusherAxleLoad_UB_ISig_4 7;
BA_ "Platform_VMCU1_Sig" SG_ 1246 PusherAxleLoad_UB_ISig_4 1;
BA_ "GenSigCycleTime" SG_ 1246 PusherAxleLoad_ISig_4 100;
BA_ "GenSigCycleTimeActive" SG_ 1246 PusherAxleLoad_ISig_4 100;
BA_ "GenSigStartValue" SG_ 1246 PusherAxleLoad_ISig_4 65535;
BA_ "NeedsUpdateBit" SG_ 1246 PusherAxleLoad_ISig_4 1;
BA_ "Platform_VMCU1_Sig" SG_ 1246 PusherAxleLoad_ISig_4 1;
BA_ "SeToolAncestorID_SIGNAL" SG_ 1246 PusherAxleLoad_ISig_4 "x0000001D0412EB1E";
BA_ "SeToolItemID_SIGNAL" SG_ 1246 PusherAxleLoad_ISig_4 "x0000001D04274C69";
BA_ "SeToolName_SIGNAL" SG_ 1246 PusherAxleLoad_ISig_4 "PusherAxleLoad";
BA_ "SeToolVersion_SIGNAL" SG_ 1246 PusherAxleLoad_ISig_4 "3";
BA_ "GenSigCycleTime" SG_ 1246 FogLight_Front_cmd_ISig_4 100;
BA_ "GenSigCycleTimeActive" SG_ 1246 FogLight_Front_cmd_ISig_4 100;
BA_ "GenSigStartValue" SG_ 1246 FogLight_Front_cmd_ISig_4 3;
BA_ "Platform_VMCU1_Sig" SG_ 1246 FogLight_Front_cmd_ISig_4 1;
BA_ "SeToolAncestorID_SIGNAL" SG_ 1246 FogLight_Front_cmd_ISig_4 "x0000001D04135140";
BA_ "SeToolItemID_SIGNAL" SG_ 1246 FogLight_Front_cmd_ISig_4 "x0000001D04384FD1";
BA_ "SeToolName_SIGNAL" SG_ 1246 FogLight_Front_cmd_ISig_4 "FogLight_Front_cmd";
BA_ "SeToolVersion_SIGNAL" SG_ 1246 FogLight_Front_cmd_ISig_4 "2";
BA_ "GenSigCycleTime" SG_ 1246 TagAxleLoad_ISig_4 100;
BA_ "GenSigCycleTimeActive" SG_ 1246 TagAxleLoad_ISig_4 100;
BA_ "GenSigStartValue" SG_ 1246 TagAxleLoad_ISig_4 65535;
BA_ "NeedsUpdateBit" SG_ 1246 TagAxleLoad_ISig_4 1;
BA_ "Platform_VMCU1_Sig" SG_ 1246 TagAxleLoad_ISig_4 1;
BA_ "SeToolAncestorID_SIGNAL" SG_ 1246 TagAxleLoad_ISig_4 "x0000001D0412EB1E";
BA_ "SeToolItemID_SIGNAL" SG_ 1246 TagAxleLoad_ISig_4 "x0000001D04274C69";
BA_ "SeToolName_SIGNAL" SG_ 1246 TagAxleLoad_ISig_4 "TagAxleLoad";
BA_ "SeToolVersion_SIGNAL" SG_ 1246 TagAxleLoad_ISig_4 "3";
BA_ "GenSigSendType" SG_ 1246 TagAxleLoad_UB_ISig_4 7;
BA_ "Platform_VMCU1_Sig" SG_ 1246 TagAxleLoad_UB_ISig_4 1;
BA_ "GenSigCycleTime" SG_ 1243 SelfStartAssistSwitch_Input_ISig 100;
BA_ "GenSigCycleTimeActive" SG_ 1243 SelfStartAssistSwitch_Input_ISig 100;
BA_ "GenSigStartValue" SG_ 1243 SelfStartAssistSwitch_Input_ISig 3;
BA_ "SystemSignalLongSymbol" SG_ 1243 SelfStartAssistSwitch_Input_ISig "SelfStartAssistSwitch_Input_ISig_4";
BA_ "GenSigCycleTime" SG_ 1243 DriveAxleLoad_ISig_4 100;
BA_ "GenSigCycleTimeActive" SG_ 1243 DriveAxleLoad_ISig_4 100;
BA_ "GenSigStartValue" SG_ 1243 DriveAxleLoad_ISig_4 65535;
BA_ "NeedsUpdateBit" SG_ 1243 DriveAxleLoad_ISig_4 1;
BA_ "Platform_VMCU1_Sig" SG_ 1243 DriveAxleLoad_ISig_4 1;
BA_ "SeToolAncestorID_SIGNAL" SG_ 1243 DriveAxleLoad_ISig_4 "x0000001D0412EB1E";
BA_ "SeToolItemID_SIGNAL" SG_ 1243 DriveAxleLoad_ISig_4 "x0000001D04274C69";
BA_ "SeToolName_SIGNAL" SG_ 1243 DriveAxleLoad_ISig_4 "DriveAxleLoad";
BA_ "SeToolVersion_SIGNAL" SG_ 1243 DriveAxleLoad_ISig_4 "3";
BA_ "GenSigCycleTime" SG_ 1243 BatterySOCAlertRawData_rqst_ISig 100;
BA_ "GenSigCycleTimeActive" SG_ 1243 BatterySOCAlertRawData_rqst_ISig 100;
BA_ "GenSigStartValue" SG_ 1243 BatterySOCAlertRawData_rqst_ISig 7;
BA_ "Platform_VMCU1_Sig" SG_ 1243 BatterySOCAlertRawData_rqst_ISig 1;
BA_ "SystemSignalLongSymbol" SG_ 1243 BatterySOCAlertRawData_rqst_ISig "BatterySOCAlertRawData_rqst_ISig_4";
BA_ "GenSigCycleTime" SG_ 1243 LivBatDisconnectDetectStat_ISig_ 100;
BA_ "GenSigCycleTimeActive" SG_ 1243 LivBatDisconnectDetectStat_ISig_ 100;
BA_ "GenSigStartValue" SG_ 1243 LivBatDisconnectDetectStat_ISig_ 3;
BA_ "SystemSignalLongSymbol" SG_ 1243 LivBatDisconnectDetectStat_ISig_ "LivBatDisconnectDetectStat_ISig_4";
BA_ "GenSigSendType" SG_ 1243 SecondaryDriveAxleLoad_UB_ISig_4 7;
BA_ "Platform_VMCU1_Sig" SG_ 1243 SecondaryDriveAxleLoad_UB_ISig_4 1;
BA_ "GenSigCycleTime" SG_ 1243 SelfStartAssist_stat_ISig_4 100;
BA_ "GenSigCycleTimeActive" SG_ 1243 SelfStartAssist_stat_ISig_4 100;
BA_ "GenSigStartValue" SG_ 1243 SelfStartAssist_stat_ISig_4 3;
BA_ "Platform_VMCU1_Sig" SG_ 1243 SelfStartAssist_stat_ISig_4 1;
BA_ "GenSigSendType" SG_ 1243 DriveAxleLoad_UB_ISig_4 7;
BA_ "Platform_VMCU1_Sig" SG_ 1243 DriveAxleLoad_UB_ISig_4 1;
BA_ "GenSigCycleTime" SG_ 1243 JumpChargeAlert_stat_ISig_4 100;
BA_ "GenSigCycleTimeActive" SG_ 1243 JumpChargeAlert_stat_ISig_4 100;
BA_ "GenSigStartValue" SG_ 1243 JumpChargeAlert_stat_ISig_4 7;
BA_ "Platform_VMCU1_Sig" SG_ 1243 JumpChargeAlert_stat_ISig_4 1;
BA_ "GenSigCycleTime" SG_ 1243 GChargerStatus_ISig_4 100;
BA_ "GenSigCycleTimeActive" SG_ 1243 GChargerStatus_ISig_4 100;
BA_ "GenSigStartValue" SG_ 1243 GChargerStatus_ISig_4 7;
BA_ "GenSigCycleTime" SG_ 1243 ShortStopHeater_status_ISig_4 100;
BA_ "GenSigCycleTimeActive" SG_ 1243 ShortStopHeater_status_ISig_4 100;
BA_ "GenSigStartValue" SG_ 1243 ShortStopHeater_status_ISig_4 7;
BA_ "Platform_VMCU1_Sig" SG_ 1243 ShortStopHeater_status_ISig_4 1;
BA_ "GenSigCycleTime" SG_ 1243 SecondaryDriveAxleLoad_ISig_4 100;
BA_ "GenSigCycleTimeActive" SG_ 1243 SecondaryDriveAxleLoad_ISig_4 100;
BA_ "GenSigStartValue" SG_ 1243 SecondaryDriveAxleLoad_ISig_4 65535;
BA_ "NeedsUpdateBit" SG_ 1243 SecondaryDriveAxleLoad_ISig_4 1;
BA_ "Platform_VMCU1_Sig" SG_ 1243 SecondaryDriveAxleLoad_ISig_4 1;
BA_ "SeToolAncestorID_SIGNAL" SG_ 1243 SecondaryDriveAxleLoad_ISig_4 "x0000001D0412EB1E";
BA_ "SeToolItemID_SIGNAL" SG_ 1243 SecondaryDriveAxleLoad_ISig_4 "x0000001D04274C69";
BA_ "SeToolName_SIGNAL" SG_ 1243 SecondaryDriveAxleLoad_ISig_4 "SecondaryDriveAxleLoad";
BA_ "SeToolVersion_SIGNAL" SG_ 1243 SecondaryDriveAxleLoad_ISig_4 "3";
BA_ "GenSigCycleTime" SG_ 1243 StartBatteryDisplay_stat_ISig_4 100;
BA_ "GenSigCycleTimeActive" SG_ 1243 StartBatteryDisplay_stat_ISig_4 100;
BA_ "GenSigStartValue" SG_ 1243 StartBatteryDisplay_stat_ISig_4 7;
BA_ "Platform_VMCU1_Sig" SG_ 1243 StartBatteryDisplay_stat_ISig_4 1;
BA_ "GenSigSendType" SG_ 1409 VMCU_BB2_57P_FCS_581 7;
BA_ "Platform_VMCU1_Sig" SG_ 1409 VMCU_BB2_57P_FCS_581 1;
BA_ "GenSigCycleTime" SG_ 1408 MaintService_ServiceCalendarTime 100;
BA_ "GenSigCycleTimeActive" SG_ 1408 MaintService_ServiceCalendarTime 100;
BA_ "GenSigStartValue" SG_ 1408 MaintService_ServiceCalendarTime 4294967295;
BA_ "Platform_VMCU1_Sig" SG_ 1408 MaintService_ServiceCalendarTime 1;
BA_ "SystemSignalLongSymbol" SG_ 1408 MaintService_ServiceCalendarTime "MaintService_ServiceCalendarTime_ISig_4_580";
BA_ "GenSigCycleTime" SG_ 1408 MaintService_EngTimeID_ISig_4_58 100;
BA_ "GenSigCycleTimeActive" SG_ 1408 MaintService_EngTimeID_ISig_4_58 100;
BA_ "GenSigStartValue" SG_ 1408 MaintService_EngTimeID_ISig_4_58 255;
BA_ "Platform_VMCU1_Sig" SG_ 1408 MaintService_EngTimeID_ISig_4_58 1;
BA_ "SystemSignalLongSymbol" SG_ 1408 MaintService_EngTimeID_ISig_4_58 "MaintService_EngTimeID_ISig_4_580";
BA_ "GenSigCycleTime" SG_ 1408 MaintService_DistID_ISig_4_580 100;
BA_ "GenSigCycleTimeActive" SG_ 1408 MaintService_DistID_ISig_4_580 100;
BA_ "GenSigStartValue" SG_ 1408 MaintService_DistID_ISig_4_580 255;
BA_ "Platform_VMCU1_Sig" SG_ 1408 MaintService_DistID_ISig_4_580 1;
BA_ "GenSigCycleTime" SG_ 1408 MaintService_ServiceDistance_ISi 100;
BA_ "GenSigCycleTimeActive" SG_ 1408 MaintService_ServiceDistance_ISi 100;
BA_ "GenSigStartValue" SG_ 1408 MaintService_ServiceDistance_ISi 4294967295;
BA_ "Platform_VMCU1_Sig" SG_ 1408 MaintService_ServiceDistance_ISi 1;
BA_ "SystemSignalLongSymbol" SG_ 1408 MaintService_ServiceDistance_ISi "MaintService_ServiceDistance_ISig_4_580";
BA_ "GenSigCycleTime" SG_ 1408 MaintService_ServiceEngineTime_I 100;
BA_ "GenSigCycleTimeActive" SG_ 1408 MaintService_ServiceEngineTime_I 100;
BA_ "GenSigStartValue" SG_ 1408 MaintService_ServiceEngineTime_I 4294967295;
BA_ "Platform_VMCU1_Sig" SG_ 1408 MaintService_ServiceEngineTime_I 1;
BA_ "SystemSignalLongSymbol" SG_ 1408 MaintService_ServiceEngineTime_I "MaintService_ServiceEngineTime_ISig_4_580";
BA_ "GenSigCycleTime" SG_ 1408 MaintService_CalDateID_ISig_4_58 100;
BA_ "GenSigCycleTimeActive" SG_ 1408 MaintService_CalDateID_ISig_4_58 100;
BA_ "GenSigStartValue" SG_ 1408 MaintService_CalDateID_ISig_4_58 255;
BA_ "Platform_VMCU1_Sig" SG_ 1408 MaintService_CalDateID_ISig_4_58 1;
BA_ "SystemSignalLongSymbol" SG_ 1408 MaintService_CalDateID_ISig_4_58 "MaintService_CalDateID_ISig_4_580";
BA_ "GenSigSendType" SG_ 1399 VMCU_BB2_57P_FCS_577 7;
BA_ "Platform_VMCU1_Sig" SG_ 1399 VMCU_BB2_57P_FCS_577 1;
BA_ "GenSigCycleTime" SG_ 1398 MaintService_ServiceEngineT_0000 100;
BA_ "GenSigCycleTimeActive" SG_ 1398 MaintService_ServiceEngineT_0000 100;
BA_ "GenSigStartValue" SG_ 1398 MaintService_ServiceEngineT_0000 4294967295;
BA_ "Platform_VMCU1_Sig" SG_ 1398 MaintService_ServiceEngineT_0000 1;
BA_ "SystemSignalLongSymbol" SG_ 1398 MaintService_ServiceEngineT_0000 "MaintService_ServiceEngineTime_ISig_4_576";
BA_ "GenSigCycleTime" SG_ 1398 MaintService_EngTimeID_ISig_4_57 100;
BA_ "GenSigCycleTimeActive" SG_ 1398 MaintService_EngTimeID_ISig_4_57 100;
BA_ "GenSigStartValue" SG_ 1398 MaintService_EngTimeID_ISig_4_57 255;
BA_ "Platform_VMCU1_Sig" SG_ 1398 MaintService_EngTimeID_ISig_4_57 1;
BA_ "SystemSignalLongSymbol" SG_ 1398 MaintService_EngTimeID_ISig_4_57 "MaintService_EngTimeID_ISig_4_576";
BA_ "GenSigCycleTime" SG_ 1398 MaintService_DistID_ISig_4_576 100;
BA_ "GenSigCycleTimeActive" SG_ 1398 MaintService_DistID_ISig_4_576 100;
BA_ "GenSigStartValue" SG_ 1398 MaintService_DistID_ISig_4_576 255;
BA_ "Platform_VMCU1_Sig" SG_ 1398 MaintService_DistID_ISig_4_576 1;
BA_ "GenSigCycleTime" SG_ 1398 MaintService_ServiceDistanc_0000 100;
BA_ "GenSigCycleTimeActive" SG_ 1398 MaintService_ServiceDistanc_0000 100;
BA_ "GenSigStartValue" SG_ 1398 MaintService_ServiceDistanc_0000 4294967295;
BA_ "Platform_VMCU1_Sig" SG_ 1398 MaintService_ServiceDistanc_0000 1;
BA_ "SystemSignalLongSymbol" SG_ 1398 MaintService_ServiceDistanc_0000 "MaintService_ServiceDistance_ISig_4_576";
BA_ "GenSigCycleTime" SG_ 1398 MaintService_CalDateID_ISig_4_57 100;
BA_ "GenSigCycleTimeActive" SG_ 1398 MaintService_CalDateID_ISig_4_57 100;
BA_ "GenSigStartValue" SG_ 1398 MaintService_CalDateID_ISig_4_57 255;
BA_ "Platform_VMCU1_Sig" SG_ 1398 MaintService_CalDateID_ISig_4_57 1;
BA_ "SystemSignalLongSymbol" SG_ 1398 MaintService_CalDateID_ISig_4_57 "MaintService_CalDateID_ISig_4_576";
BA_ "GenSigCycleTime" SG_ 1398 MaintService_ServiceCalenda_0000 100;
BA_ "GenSigCycleTimeActive" SG_ 1398 MaintService_ServiceCalenda_0000 100;
BA_ "GenSigStartValue" SG_ 1398 MaintService_ServiceCalenda_0000 4294967295;
BA_ "Platform_VMCU1_Sig" SG_ 1398 MaintService_ServiceCalenda_0000 1;
BA_ "SystemSignalLongSymbol" SG_ 1398 MaintService_ServiceCalenda_0000 "MaintService_ServiceCalendarTime_ISig_4_576";
BA_ "GenSigCycleTime" SG_ 1428 EngTrueIdleSpeedTime_ISig_4 100;
BA_ "GenSigCycleTimeActive" SG_ 1428 EngTrueIdleSpeedTime_ISig_4 100;
BA_ "GenSigStartValue" SG_ 1428 EngTrueIdleSpeedTime_ISig_4 4294967295;
BA_ "GenSigMaxLatency" SG_ 1428 EngTrueIdleSpeedTime_ISig_4 1345;
BA_ "Platform_VMCU1_Sig" SG_ 1428 EngTrueIdleSpeedTime_ISig_4 1;
BA_ "GenSigCycleTime" SG_ 1428 EngineGreenAreaOutTime_ISig_4 100;
BA_ "GenSigCycleTimeActive" SG_ 1428 EngineGreenAreaOutTime_ISig_4 100;
BA_ "GenSigStartValue" SG_ 1428 EngineGreenAreaOutTime_ISig_4 4294967295;
BA_ "GenSigMaxLatency" SG_ 1428 EngineGreenAreaOutTime_ISig_4 1345;
BA_ "Platform_VMCU1_Sig" SG_ 1428 EngineGreenAreaOutTime_ISig_4 1;
BA_ "GenSigCycleTime" SG_ 1059 BatterySOCnom_ISig_4 100;
BA_ "GenSigCycleTimeActive" SG_ 1059 BatterySOCnom_ISig_4 100;
BA_ "GenSigStartValue" SG_ 1059 BatterySOCnom_ISig_4 255;
BA_ "GenSigMaxLatency" SG_ 1059 BatterySOCnom_ISig_4 187;
BA_ "Platform_VMCU1_Sig" SG_ 1059 BatterySOCnom_ISig_4 1;
BA_ "SeToolAncestorID_SIGNAL" SG_ 1059 BatterySOCnom_ISig_4 "x0000001D0431FB91";
BA_ "SeToolItemID_SIGNAL" SG_ 1059 BatterySOCnom_ISig_4 "x0000001D0431FB91";
BA_ "SeToolName_SIGNAL" SG_ 1059 BatterySOCnom_ISig_4 "BatterySOCnom";
BA_ "SeToolVersion_SIGNAL" SG_ 1059 BatterySOCnom_ISig_4 "1";
BA_ "GenSigCycleTime" SG_ 1059 BatterySOH_ISig_4 100;
BA_ "GenSigCycleTimeActive" SG_ 1059 BatterySOH_ISig_4 100;
BA_ "GenSigStartValue" SG_ 1059 BatterySOH_ISig_4 255;
BA_ "GenSigMaxLatency" SG_ 1059 BatterySOH_ISig_4 187;
BA_ "Platform_VMCU1_Sig" SG_ 1059 BatterySOH_ISig_4 1;
BA_ "SeToolAncestorID_SIGNAL" SG_ 1059 BatterySOH_ISig_4 "x0000001D041491DF";
BA_ "SeToolItemID_SIGNAL" SG_ 1059 BatterySOH_ISig_4 "x0000001D041491DF";
BA_ "SeToolName_SIGNAL" SG_ 1059 BatterySOH_ISig_4 "BatterySOH";
BA_ "SeToolVersion_SIGNAL" SG_ 1059 BatterySOH_ISig_4 "1";
BA_ "GenSigCycleTime" SG_ 1059 ReducedLoadMode_stat_ISig_4 100;
BA_ "GenSigCycleTimeActive" SG_ 1059 ReducedLoadMode_stat_ISig_4 100;
BA_ "GenSigStartValue" SG_ 1059 ReducedLoadMode_stat_ISig_4 3;
BA_ "Platform_VMCU1_Sig" SG_ 1059 ReducedLoadMode_stat_ISig_4 1;
BA_ "GenSigCycleTime" SG_ 1059 BatterySOCAlert_rqst_ISig_4 100;
BA_ "GenSigCycleTimeActive" SG_ 1059 BatterySOCAlert_rqst_ISig_4 100;
BA_ "GenSigStartValue" SG_ 1059 BatterySOCAlert_rqst_ISig_4 7;
BA_ "GenSigMaxLatency" SG_ 1059 BatterySOCAlert_rqst_ISig_4 187;
BA_ "Platform_VMCU1_Sig" SG_ 1059 BatterySOCAlert_rqst_ISig_4 1;
BA_ "GenSigCycleTime" SG_ 1059 BatteryVoltageDisplayValue_ISig_ 100;
BA_ "GenSigCycleTimeActive" SG_ 1059 BatteryVoltageDisplayValue_ISig_ 100;
BA_ "GenSigStartValue" SG_ 1059 BatteryVoltageDisplayValue_ISig_ 65535;
BA_ "GenSigMaxLatency" SG_ 1059 BatteryVoltageDisplayValue_ISig_ 187;
BA_ "Platform_VMCU1_Sig" SG_ 1059 BatteryVoltageDisplayValue_ISig_ 1;
BA_ "SystemSignalLongSymbol" SG_ 1059 BatteryVoltageDisplayValue_ISig_ "BatteryVoltageDisplayValue_ISig_4";
BA_ "GenSigCycleTime" SG_ 1059 BatteryCurrent_ISig_4 100;
BA_ "GenSigCycleTimeActive" SG_ 1059 BatteryCurrent_ISig_4 100;
BA_ "GenSigStartValue" SG_ 1059 BatteryCurrent_ISig_4 65535;
BA_ "GenSigMaxLatency" SG_ 1059 BatteryCurrent_ISig_4 187;
BA_ "Platform_VMCU1_Sig" SG_ 1059 BatteryCurrent_ISig_4 1;
BA_ "SeToolAncestorID_SIGNAL" SG_ 1059 BatteryCurrent_ISig_4 "x0000001D041491E4";
BA_ "SeToolItemID_SIGNAL" SG_ 1059 BatteryCurrent_ISig_4 "x0000001D042E2456";
BA_ "SeToolName_SIGNAL" SG_ 1059 BatteryCurrent_ISig_4 "BatteryCurrent";
BA_ "SeToolVersion_SIGNAL" SG_ 1059 BatteryCurrent_ISig_4 "2";
BA_ "GenSigCycleTime" SG_ 925 MaintOilQuality 100;
BA_ "GenSigCycleTimeActive" SG_ 925 MaintOilQuality 100;
BA_ "GenSigStartValue" SG_ 925 MaintOilQuality 7;
BA_ "GenSigMaxLatency" SG_ 925 MaintOilQuality 112;
BA_ "Platform_VMCU1_Sig" SG_ 925 MaintOilQuality 1;
BA_ "GenSigCycleTime" SG_ 925 ECSLimpHomeNotification_ISig_4 100;
BA_ "GenSigCycleTimeActive" SG_ 925 ECSLimpHomeNotification_ISig_4 100;
BA_ "GenSigStartValue" SG_ 925 ECSLimpHomeNotification_ISig_4 7;
BA_ "GenSigMaxLatency" SG_ 925 ECSLimpHomeNotification_ISig_4 63;
BA_ "Platform_VMCU1_Sig" SG_ 925 ECSLimpHomeNotification_ISig_4 1;
BA_ "GenSigCycleTime" SG_ 925 MaintenanceResetStatus 100;
BA_ "GenSigCycleTimeActive" SG_ 925 MaintenanceResetStatus 100;
BA_ "GenSigStartValue" SG_ 925 MaintenanceResetStatus 7;
BA_ "Platform_VMCU1_Sig" SG_ 925 MaintenanceResetStatus 1;
BA_ "GenSigCycleTime" SG_ 925 FirstAxleLowerPrioSelected_ISig_ 100;
BA_ "GenSigCycleTimeActive" SG_ 925 FirstAxleLowerPrioSelected_ISig_ 100;
BA_ "GenSigStartValue" SG_ 925 FirstAxleLowerPrioSelected_ISig_ 7;
BA_ "SystemSignalLongSymbol" SG_ 925 FirstAxleLowerPrioSelected_ISig_ "FirstAxleLowerPrioSelected_ISig_4";
BA_ "GenSigCycleTime" SG_ 925 MaintOilReset 100;
BA_ "GenSigCycleTimeActive" SG_ 925 MaintOilReset 100;
BA_ "GenSigStartValue" SG_ 925 MaintOilReset 3;
BA_ "GenSigMaxLatency" SG_ 925 MaintOilReset 112;
BA_ "Platform_VMCU1_Sig" SG_ 925 MaintOilReset 1;
BA_ "GenSigCycleTime" SG_ 925 RssInhibStartEngine_rqst 100;
BA_ "GenSigCycleTimeActive" SG_ 925 RssInhibStartEngine_rqst 100;
BA_ "GenSigStartValue" SG_ 925 RssInhibStartEngine_rqst 3;
BA_ "GenSigMaxLatency" SG_ 925 RssInhibStartEngine_rqst 112;
BA_ "Platform_VMCU1_Sig" SG_ 925 RssInhibStartEngine_rqst 1;
BA_ "GenSigCycleTime" SG_ 925 PositionLightRequest_status 100;
BA_ "GenSigCycleTimeActive" SG_ 925 PositionLightRequest_status 100;
BA_ "GenSigStartValue" SG_ 925 PositionLightRequest_status 3;
BA_ "GenSigMaxLatency" SG_ 925 PositionLightRequest_status 112;
BA_ "Platform_VMCU1_Sig" SG_ 925 PositionLightRequest_status 1;
BA_ "GenSigCycleTime" SG_ 925 ExtraBBTailLiftStatus_ISig_4 100;
BA_ "GenSigCycleTimeActive" SG_ 925 ExtraBBTailLiftStatus_ISig_4 100;
BA_ "GenSigStartValue" SG_ 925 ExtraBBTailLiftStatus_ISig_4 3;
BA_ "GenSigMaxLatency" SG_ 925 ExtraBBTailLiftStatus_ISig_4 112;
BA_ "Platform_VMCU1_Sig" SG_ 925 ExtraBBTailLiftStatus_ISig_4 1;
BA_ "GenSigCycleTime" SG_ 925 MaintenanceNotification_ISig_4 100;
BA_ "GenSigCycleTimeActive" SG_ 925 MaintenanceNotification_ISig_4 100;
BA_ "GenSigStartValue" SG_ 925 MaintenanceNotification_ISig_4 7;
BA_ "GenSigMaxLatency" SG_ 925 MaintenanceNotification_ISig_4 112;
BA_ "Platform_VMCU1_Sig" SG_ 925 MaintenanceNotification_ISig_4 1;
BA_ "GenSigCycleTime" SG_ 925 ExtraBBSlidable5thWheelStatus 100;
BA_ "GenSigCycleTimeActive" SG_ 925 ExtraBBSlidable5thWheelStatus 100;
BA_ "GenSigStartValue" SG_ 925 ExtraBBSlidable5thWheelStatus 3;
BA_ "GenSigMaxLatency" SG_ 925 ExtraBBSlidable5thWheelStatus 112;
BA_ "Platform_VMCU1_Sig" SG_ 925 ExtraBBSlidable5thWheelStatus 1;
BA_ "GenSigCycleTime" SG_ 925 ParkBrakeReleasePossible_stat 100;
BA_ "GenSigCycleTimeActive" SG_ 925 ParkBrakeReleasePossible_stat 100;
BA_ "GenSigStartValue" SG_ 925 ParkBrakeReleasePossible_stat 3;
BA_ "GenSigMaxLatency" SG_ 925 ParkBrakeReleasePossible_stat 112;
BA_ "Platform_VMCU1_Sig" SG_ 925 ParkBrakeReleasePossible_stat 1;
BA_ "GenSigCycleTime" SG_ 925 LoadDistributionALDChangeACK_ISi 100;
BA_ "GenSigCycleTimeActive" SG_ 925 LoadDistributionALDChangeACK_ISi 100;
BA_ "GenSigStartValue" SG_ 925 LoadDistributionALDChangeACK_ISi 7;
BA_ "GenSigMaxLatency" SG_ 925 LoadDistributionALDChangeACK_ISi 112;
BA_ "Platform_VMCU1_Sig" SG_ 925 LoadDistributionALDChangeACK_ISi 1;
BA_ "SystemSignalLongSymbol" SG_ 925 LoadDistributionALDChangeACK_ISi "LoadDistributionALDChangeACK_ISig_4";
BA_ "GenSigSendType" SG_ 925 PoorAirPressureInfo_UB 7;
BA_ "Platform_VMCU1_Sig" SG_ 925 PoorAirPressureInfo_UB 1;
BA_ "GenSigCycleTime" SG_ 925 ParkBrakeWorkshopMode_ISig_4 100;
BA_ "GenSigCycleTimeActive" SG_ 925 ParkBrakeWorkshopMode_ISig_4 100;
BA_ "GenSigStartValue" SG_ 925 ParkBrakeWorkshopMode_ISig_4 3;
BA_ "GenSigMaxLatency" SG_ 925 ParkBrakeWorkshopMode_ISig_4 112;
BA_ "Platform_VMCU1_Sig" SG_ 925 ParkBrakeWorkshopMode_ISig_4 1;
BA_ "GenSigCycleTime" SG_ 925 ExtraBBContainerUnlockStatus 100;
BA_ "GenSigCycleTimeActive" SG_ 925 ExtraBBContainerUnlockStatus 100;
BA_ "GenSigStartValue" SG_ 925 ExtraBBContainerUnlockStatus 3;
BA_ "GenSigMaxLatency" SG_ 925 ExtraBBContainerUnlockStatus 112;
BA_ "Platform_VMCU1_Sig" SG_ 925 ExtraBBContainerUnlockStatus 1;
BA_ "GenSigCycleTime" SG_ 925 MainBeamRequest_status_ISig_4 100;
BA_ "GenSigCycleTimeActive" SG_ 925 MainBeamRequest_status_ISig_4 100;
BA_ "GenSigStartValue" SG_ 925 MainBeamRequest_status_ISig_4 3;
BA_ "GenSigMaxLatency" SG_ 925 MainBeamRequest_status_ISig_4 112;
BA_ "Platform_VMCU1_Sig" SG_ 925 MainBeamRequest_status_ISig_4 1;
BA_ "GenSigCycleTime" SG_ 925 ExtraBBCraneStatus_ISig_4 100;
BA_ "GenSigCycleTimeActive" SG_ 925 ExtraBBCraneStatus_ISig_4 100;
BA_ "GenSigStartValue" SG_ 925 ExtraBBCraneStatus_ISig_4 7;
BA_ "GenSigMaxLatency" SG_ 925 ExtraBBCraneStatus_ISig_4 112;
BA_ "Platform_VMCU1_Sig" SG_ 925 ExtraBBCraneStatus_ISig_4 1;
BA_ "GenSigCycleTime" SG_ 925 AirCompressorStatus 100;
BA_ "GenSigCycleTimeActive" SG_ 925 AirCompressorStatus 100;
BA_ "GenSigStartValue" SG_ 925 AirCompressorStatus 3;
BA_ "Platform_VMCU1_Sig" SG_ 925 AirCompressorStatus 1;
BA_ "GenSigCycleTime" SG_ 925 TrailerABSStatus_ISig_4 100;
BA_ "GenSigCycleTimeActive" SG_ 925 TrailerABSStatus_ISig_4 100;
BA_ "GenSigStartValue" SG_ 925 TrailerABSStatus_ISig_4 3;
BA_ "GenSigMaxLatency" SG_ 925 TrailerABSStatus_ISig_4 112;
BA_ "Platform_VMCU1_Sig" SG_ 925 TrailerABSStatus_ISig_4 1;
BA_ "GenSigCycleTime" SG_ 925 RegenInhibitVehicleHeight_ISig_4 100;
BA_ "GenSigCycleTimeActive" SG_ 925 RegenInhibitVehicleHeight_ISig_4 100;
BA_ "GenSigStartValue" SG_ 925 RegenInhibitVehicleHeight_ISig_4 3;
BA_ "Platform_VMCU1_Sig" SG_ 925 RegenInhibitVehicleHeight_ISig_4 1;
BA_ "GenSigCycleTime" SG_ 925 PoorAirPressureInfo 100;
BA_ "GenSigCycleTimeActive" SG_ 925 PoorAirPressureInfo 100;
BA_ "GenSigStartValue" SG_ 925 PoorAirPressureInfo 3;
BA_ "GenSigMaxLatency" SG_ 925 PoorAirPressureInfo 112;
BA_ "NeedsUpdateBit" SG_ 925 PoorAirPressureInfo 1;
BA_ "Platform_VMCU1_Sig" SG_ 925 PoorAirPressureInfo 1;
BA_ "GenSigCycleTime" SG_ 925 FogLightRearRequest_stat 100;
BA_ "GenSigCycleTimeActive" SG_ 925 FogLightRearRequest_stat 100;
BA_ "GenSigStartValue" SG_ 925 FogLightRearRequest_stat 3;
BA_ "GenSigMaxLatency" SG_ 925 FogLightRearRequest_stat 112;
BA_ "Platform_VMCU1_Sig" SG_ 925 FogLightRearRequest_stat 1;
BA_ "GenSigCycleTime" SG_ 925 MainBeam_cmd_ISig_4 100;
BA_ "GenSigCycleTimeActive" SG_ 925 MainBeam_cmd_ISig_4 100;
BA_ "GenSigStartValue" SG_ 925 MainBeam_cmd_ISig_4 7;
BA_ "Platform_VMCU1_Sig" SG_ 925 MainBeam_cmd_ISig_4 1;
BA_ "SeToolAncestorID_SIGNAL" SG_ 925 MainBeam_cmd_ISig_4 "x0000001D04134EB4";
BA_ "SeToolItemID_SIGNAL" SG_ 925 MainBeam_cmd_ISig_4 "x0000001D04383E5C";
BA_ "SeToolName_SIGNAL" SG_ 925 MainBeam_cmd_ISig_4 "MainBeam_cmd";
BA_ "SeToolVersion_SIGNAL" SG_ 925 MainBeam_cmd_ISig_4 "4";
BA_ "GenSigCycleTime" SG_ 925 FrontParkBrakeOverrideInd_ISig_4 100;
BA_ "GenSigCycleTimeActive" SG_ 925 FrontParkBrakeOverrideInd_ISig_4 100;
BA_ "GenSigStartValue" SG_ 925 FrontParkBrakeOverrideInd_ISig_4 3;
BA_ "GenSigCycleTime" SG_ 849 AuxSwitchBbLoad4_cmd 100;
BA_ "GenSigCycleTimeActive" SG_ 849 AuxSwitchBbLoad4_cmd 100;
BA_ "GenSigStartValue" SG_ 849 AuxSwitchBbLoad4_cmd 3;
BA_ "GenSigMaxLatency" SG_ 849 AuxSwitchBbLoad4_cmd 63;
BA_ "Platform_VMCU1_Sig" SG_ 849 AuxSwitchBbLoad4_cmd 1;
BA_ "GenSigCycleTime" SG_ 849 AuxSwitchBbLoad1_Status_ISig_4 100;
BA_ "GenSigCycleTimeActive" SG_ 849 AuxSwitchBbLoad1_Status_ISig_4 100;
BA_ "GenSigStartValue" SG_ 849 AuxSwitchBbLoad1_Status_ISig_4 3;
BA_ "GenSigMaxLatency" SG_ 849 AuxSwitchBbLoad1_Status_ISig_4 63;
BA_ "Platform_VMCU1_Sig" SG_ 849 AuxSwitchBbLoad1_Status_ISig_4 1;
BA_ "GenSigSendType" SG_ 849 BrakeLightConvoy_rqst_UB_ISig_4 7;
BA_ "Platform_VMCU1_Sig" SG_ 849 BrakeLightConvoy_rqst_UB_ISig_4 1;
BA_ "GenSigCycleTime" SG_ 849 AuxSwitchBbLoad3_cmd 100;
BA_ "GenSigCycleTimeActive" SG_ 849 AuxSwitchBbLoad3_cmd 100;
BA_ "GenSigStartValue" SG_ 849 AuxSwitchBbLoad3_cmd 3;
BA_ "GenSigMaxLatency" SG_ 849 AuxSwitchBbLoad3_cmd 63;
BA_ "Platform_VMCU1_Sig" SG_ 849 AuxSwitchBbLoad3_cmd 1;
BA_ "GenSigCycleTime" SG_ 849 MainBeam_rqst 100;
BA_ "GenSigCycleTimeActive" SG_ 849 MainBeam_rqst 100;
BA_ "GenSigStartValue" SG_ 849 MainBeam_rqst 7;
BA_ "Platform_VMCU1_Sig" SG_ 849 MainBeam_rqst 1;
BA_ "GenSigCycleTime" SG_ 849 BatterySOCTrustLevel_ISig_4 100;
BA_ "GenSigCycleTimeActive" SG_ 849 BatterySOCTrustLevel_ISig_4 100;
BA_ "GenSigStartValue" SG_ 849 BatterySOCTrustLevel_ISig_4 255;
BA_ "Platform_VMCU1_Sig" SG_ 849 BatterySOCTrustLevel_ISig_4 1;
BA_ "GenSigCycleTime" SG_ 849 AuxSwitchBbLoad4_Status_ISig_4 100;
BA_ "GenSigCycleTimeActive" SG_ 849 AuxSwitchBbLoad4_Status_ISig_4 100;
BA_ "GenSigStartValue" SG_ 849 AuxSwitchBbLoad4_Status_ISig_4 3;
BA_ "GenSigMaxLatency" SG_ 849 AuxSwitchBbLoad4_Status_ISig_4 63;
BA_ "Platform_VMCU1_Sig" SG_ 849 AuxSwitchBbLoad4_Status_ISig_4 1;
BA_ "GenSigCycleTime" SG_ 849 BrakeLightConvoy_rqst_ISig_4 100;
BA_ "GenSigCycleTimeActive" SG_ 849 BrakeLightConvoy_rqst_ISig_4 100;
BA_ "GenSigStartValue" SG_ 849 BrakeLightConvoy_rqst_ISig_4 3;
BA_ "NeedsUpdateBit" SG_ 849 BrakeLightConvoy_rqst_ISig_4 1;
BA_ "Platform_VMCU1_Sig" SG_ 849 BrakeLightConvoy_rqst_ISig_4 1;
BA_ "GenSigCycleTime" SG_ 849 DoorWarningLight_cmd_ISig_4 100;
BA_ "GenSigCycleTimeActive" SG_ 849 DoorWarningLight_cmd_ISig_4 100;
BA_ "GenSigStartValue" SG_ 849 DoorWarningLight_cmd_ISig_4 3;
BA_ "Platform_VMCU1_Sig" SG_ 849 DoorWarningLight_cmd_ISig_4 1;
BA_ "GenSigCycleTime" SG_ 849 BlackOutandConvoyMode_rqst_ISig_ 100;
BA_ "GenSigCycleTimeActive" SG_ 849 BlackOutandConvoyMode_rqst_ISig_ 100;
BA_ "GenSigStartValue" SG_ 849 BlackOutandConvoyMode_rqst_ISig_ 7;
BA_ "Platform_VMCU1_Sig" SG_ 849 BlackOutandConvoyMode_rqst_ISig_ 1;
BA_ "SystemSignalLongSymbol" SG_ 849 BlackOutandConvoyMode_rqst_ISig_ "BlackOutandConvoyMode_rqst_ISig_4";
BA_ "GenSigCycleTime" SG_ 849 DirIndicatorRqstLights_stat 100;
BA_ "GenSigCycleTimeActive" SG_ 849 DirIndicatorRqstLights_stat 100;
BA_ "GenSigStartValue" SG_ 849 DirIndicatorRqstLights_stat 7;
BA_ "GenSigMaxLatency" SG_ 849 DirIndicatorRqstLights_stat 63;
BA_ "Platform_VMCU1_Sig" SG_ 849 DirIndicatorRqstLights_stat 1;
BA_ "GenSigCycleTime" SG_ 849 DippedBeamRequest_status 100;
BA_ "GenSigCycleTimeActive" SG_ 849 DippedBeamRequest_status 100;
BA_ "GenSigStartValue" SG_ 849 DippedBeamRequest_status 3;
BA_ "GenSigMaxLatency" SG_ 849 DippedBeamRequest_status 63;
BA_ "Platform_VMCU1_Sig" SG_ 849 DippedBeamRequest_status 1;
BA_ "GenSigCycleTime" SG_ 849 AuxSwitchBbLoad3_Status_ISig_4 100;
BA_ "GenSigCycleTimeActive" SG_ 849 AuxSwitchBbLoad3_Status_ISig_4 100;
BA_ "GenSigStartValue" SG_ 849 AuxSwitchBbLoad3_Status_ISig_4 3;
BA_ "GenSigMaxLatency" SG_ 849 AuxSwitchBbLoad3_Status_ISig_4 63;
BA_ "Platform_VMCU1_Sig" SG_ 849 AuxSwitchBbLoad3_Status_ISig_4 1;
BA_ "GenSigCycleTime" SG_ 849 DoorInstepLight_cmd_ISig_4 100;
BA_ "GenSigCycleTimeActive" SG_ 849 DoorInstepLight_cmd_ISig_4 100;
BA_ "GenSigStartValue" SG_ 849 DoorInstepLight_cmd_ISig_4 3;
BA_ "Platform_VMCU1_Sig" SG_ 849 DoorInstepLight_cmd_ISig_4 1;
BA_ "GenSigCycleTime" SG_ 849 DRLRequest_status 100;
BA_ "GenSigCycleTimeActive" SG_ 849 DRLRequest_status 100;
BA_ "GenSigStartValue" SG_ 849 DRLRequest_status 3;
BA_ "GenSigMaxLatency" SG_ 849 DRLRequest_status 63;
BA_ "Platform_VMCU1_Sig" SG_ 849 DRLRequest_status 1;
BA_ "GenSigCycleTime" SG_ 849 AuxSwitchBbLoad6_Status_ISig_4 100;
BA_ "GenSigCycleTimeActive" SG_ 849 AuxSwitchBbLoad6_Status_ISig_4 100;
BA_ "GenSigStartValue" SG_ 849 AuxSwitchBbLoad6_Status_ISig_4 3;
BA_ "GenSigMaxLatency" SG_ 849 AuxSwitchBbLoad6_Status_ISig_4 63;
BA_ "Platform_VMCU1_Sig" SG_ 849 AuxSwitchBbLoad6_Status_ISig_4 1;
BA_ "GenSigCycleTime" SG_ 849 AuxSwitchBbLoad2_Status_ISig_4 100;
BA_ "GenSigCycleTimeActive" SG_ 849 AuxSwitchBbLoad2_Status_ISig_4 100;
BA_ "GenSigStartValue" SG_ 849 AuxSwitchBbLoad2_Status_ISig_4 3;
BA_ "GenSigMaxLatency" SG_ 849 AuxSwitchBbLoad2_Status_ISig_4 63;
BA_ "Platform_VMCU1_Sig" SG_ 849 AuxSwitchBbLoad2_Status_ISig_4 1;
BA_ "GenSigCycleTime" SG_ 849 AuxSwitchBbLoad5_cmd 100;
BA_ "GenSigCycleTimeActive" SG_ 849 AuxSwitchBbLoad5_cmd 100;
BA_ "GenSigStartValue" SG_ 849 AuxSwitchBbLoad5_cmd 3;
BA_ "GenSigMaxLatency" SG_ 849 AuxSwitchBbLoad5_cmd 63;
BA_ "Platform_VMCU1_Sig" SG_ 849 AuxSwitchBbLoad5_cmd 1;
BA_ "GenSigCycleTime" SG_ 849 PBReleaseInhibit_EPBState_ISig_4 100;
BA_ "GenSigCycleTimeActive" SG_ 849 PBReleaseInhibit_EPBState_ISig_4 100;
BA_ "GenSigStartValue" SG_ 849 PBReleaseInhibit_EPBState_ISig_4 7;
BA_ "Platform_VMCU1_Sig" SG_ 849 PBReleaseInhibit_EPBState_ISig_4 1;
BA_ "GenSigCycleTime" SG_ 849 ExtStaticTrailerBrake_Stat_ISig_ 100;
BA_ "GenSigCycleTimeActive" SG_ 849 ExtStaticTrailerBrake_Stat_ISig_ 100;
BA_ "GenSigStartValue" SG_ 849 ExtStaticTrailerBrake_Stat_ISig_ 3;
BA_ "Platform_VMCU1_Sig" SG_ 849 ExtStaticTrailerBrake_Stat_ISig_ 1;
BA_ "SystemSignalLongSymbol" SG_ 849 ExtStaticTrailerBrake_Stat_ISig_ "ExtStaticTrailerBrake_Stat_ISig_4";
BA_ "GenSigCycleTime" SG_ 849 AuxSwitchBbLoad5_Status_ISig_4 100;
BA_ "GenSigCycleTimeActive" SG_ 849 AuxSwitchBbLoad5_Status_ISig_4 100;
BA_ "GenSigStartValue" SG_ 849 AuxSwitchBbLoad5_Status_ISig_4 3;
BA_ "GenSigMaxLatency" SG_ 849 AuxSwitchBbLoad5_Status_ISig_4 63;
BA_ "Platform_VMCU1_Sig" SG_ 849 AuxSwitchBbLoad5_Status_ISig_4 1;
BA_ "GenSigCycleTime" SG_ 849 DoubleFrontAxleSteeringWarning_I 100;
BA_ "GenSigCycleTimeActive" SG_ 849 DoubleFrontAxleSteeringWarning_I 100;
BA_ "GenSigStartValue" SG_ 849 DoubleFrontAxleSteeringWarning_I 3;
BA_ "SystemSignalLongSymbol" SG_ 849 DoubleFrontAxleSteeringWarning_I "DoubleFrontAxleSteeringWarning_ISig_4";
BA_ "GenSigCycleTime" SG_ 849 AuxSwitchBbLoad6_cmd 100;
BA_ "GenSigCycleTimeActive" SG_ 849 AuxSwitchBbLoad6_cmd 100;
BA_ "GenSigStartValue" SG_ 849 AuxSwitchBbLoad6_cmd 3;
BA_ "GenSigMaxLatency" SG_ 849 AuxSwitchBbLoad6_cmd 63;
BA_ "Platform_VMCU1_Sig" SG_ 849 AuxSwitchBbLoad6_cmd 1;
BA_ "GenSigCycleTime" SG_ 849 AcceleratorPedalTestStatus 100;
BA_ "GenSigCycleTimeActive" SG_ 849 AcceleratorPedalTestStatus 100;
BA_ "GenSigStartValue" SG_ 849 AcceleratorPedalTestStatus 7;
BA_ "GenSigCycleTime" SG_ 735 CCSetSpeed_ISig_4 100;
BA_ "GenSigCycleTimeActive" SG_ 735 CCSetSpeed_ISig_4 100;
BA_ "GenSigStartValue" SG_ 735 CCSetSpeed_ISig_4 65535;
BA_ "GenSigMaxLatency" SG_ 735 CCSetSpeed_ISig_4 40;
BA_ "Platform_VMCU1_Sig" SG_ 735 CCSetSpeed_ISig_4 1;
BA_ "GenSigCycleTime" SG_ 735 AcceleratorPedalQuality_ISig_4 100;
BA_ "GenSigCycleTimeActive" SG_ 735 AcceleratorPedalQuality_ISig_4 100;
BA_ "GenSigStartValue" SG_ 735 AcceleratorPedalQuality_ISig_4 3;
BA_ "Platform_VMCU1_Sig" SG_ 735 AcceleratorPedalQuality_ISig_4 1;
BA_ "GenSigCycleTime" SG_ 735 CCStates_ISig_4 100;
BA_ "GenSigCycleTimeActive" SG_ 735 CCStates_ISig_4 100;
BA_ "GenSigStartValue" SG_ 735 CCStates_ISig_4 15;
BA_ "GenSigMaxLatency" SG_ 735 CCStates_ISig_4 40;
BA_ "Platform_VMCU1_Sig" SG_ 735 CCStates_ISig_4 1;
BA_ "GenSigCycleTime" SG_ 735 CCIOM_ParkBrakeAlert_ISig_4 100;
BA_ "GenSigCycleTimeActive" SG_ 735 CCIOM_ParkBrakeAlert_ISig_4 100;
BA_ "GenSigStartValue" SG_ 735 CCIOM_ParkBrakeAlert_ISig_4 3;
BA_ "Platform_VMCU1_Sig" SG_ 735 CCIOM_ParkBrakeAlert_ISig_4 1;
BA_ "GenSigCycleTime" SG_ 735 CCDeactivationWarning 100;
BA_ "GenSigCycleTimeActive" SG_ 735 CCDeactivationWarning 100;
BA_ "GenSigStartValue" SG_ 735 CCDeactivationWarning 3;
BA_ "GenSigMaxLatency" SG_ 735 CCDeactivationWarning 40;
BA_ "Platform_VMCU1_Sig" SG_ 735 CCDeactivationWarning 1;
BA_ "SeToolAncestorID_SIGNAL" SG_ 735 CCDeactivationWarning "x0000001D04184560";
BA_ "SeToolItemID_SIGNAL" SG_ 735 CCDeactivationWarning "x0000001D043C571E";
BA_ "SeToolName_SIGNAL" SG_ 735 CCDeactivationWarning "CCDeactivationWarning";
BA_ "SeToolVersion_SIGNAL" SG_ 735 CCDeactivationWarning "2";
BA_ "GenSigCycleTime" SG_ 735 PrimaryAcctrPedalPosition_ISig_4 100;
BA_ "GenSigCycleTimeActive" SG_ 735 PrimaryAcctrPedalPosition_ISig_4 100;
BA_ "GenSigStartValue" SG_ 735 PrimaryAcctrPedalPosition_ISig_4 255;
BA_ "Platform_VMCU1_Sig" SG_ 735 PrimaryAcctrPedalPosition_ISig_4 1;
BA_ "GenSigSendType" SG_ 735 ElectricalLoadReduction_rqst_UB_ 7;
BA_ "Platform_VMCU1_Sig" SG_ 735 ElectricalLoadReduction_rqst_UB_ 1;
BA_ "SystemSignalLongSymbol" SG_ 735 ElectricalLoadReduction_rqst_UB_ "ElectricalLoadReduction_rqst_UB_ISig_4";
BA_ "GenSigCycleTime" SG_ 735 CCNotificationReq 100;
BA_ "GenSigCycleTimeActive" SG_ 735 CCNotificationReq 100;
BA_ "GenSigStartValue" SG_ 735 CCNotificationReq 15;
BA_ "GenSigMaxLatency" SG_ 735 CCNotificationReq 40;
BA_ "Platform_VMCU1_Sig" SG_ 735 CCNotificationReq 1;
BA_ "SeToolAncestorID_SIGNAL" SG_ 735 CCNotificationReq "x0000001D0418455E";
BA_ "SeToolItemID_SIGNAL" SG_ 735 CCNotificationReq "x0000001D043A835E";
BA_ "SeToolName_SIGNAL" SG_ 735 CCNotificationReq "CCInformationMessageRequest";
BA_ "SeToolVersion_SIGNAL" SG_ 735 CCNotificationReq "3";
BA_ "GenSigSendType" SG_ 735 FifthWheelLockingInformation_UB_ 7;
BA_ "Platform_VMCU1_Sig" SG_ 735 FifthWheelLockingInformation_UB_ 1;
BA_ "SystemSignalLongSymbol" SG_ 735 FifthWheelLockingInformation_UB_ "FifthWheelLockingInformation_UB_ISig_4";
BA_ "GenSigCycleTime" SG_ 735 AcceleratorPedalStatus_ISig_4 100;
BA_ "GenSigCycleTimeActive" SG_ 735 AcceleratorPedalStatus_ISig_4 100;
BA_ "GenSigStartValue" SG_ 735 AcceleratorPedalStatus_ISig_4 7;
BA_ "Platform_VMCU1_Sig" SG_ 735 AcceleratorPedalStatus_ISig_4 1;
BA_ "GenSigCycleTime" SG_ 735 LoadDistributionRequestedACK_ISi 100;
BA_ "GenSigCycleTimeActive" SG_ 735 LoadDistributionRequestedACK_ISi 100;
BA_ "GenSigStartValue" SG_ 735 LoadDistributionRequestedACK_ISi 7;
BA_ "Platform_VMCU1_Sig" SG_ 735 LoadDistributionRequestedACK_ISi 1;
BA_ "SystemSignalLongSymbol" SG_ 735 LoadDistributionRequestedACK_ISi "LoadDistributionRequestedACK_ISig_4";
BA_ "GenSigCycleTime" SG_ 735 ElectricalLoadReduction_rqst_ISi 100;
BA_ "GenSigCycleTimeActive" SG_ 735 ElectricalLoadReduction_rqst_ISi 100;
BA_ "GenSigStartValue" SG_ 735 ElectricalLoadReduction_rqst_ISi 7;
BA_ "NeedsUpdateBit" SG_ 735 ElectricalLoadReduction_rqst_ISi 1;
BA_ "Platform_VMCU1_Sig" SG_ 735 ElectricalLoadReduction_rqst_ISi 1;
BA_ "SystemSignalLongSymbol" SG_ 735 ElectricalLoadReduction_rqst_ISi "ElectricalLoadReduction_rqst_ISig_4";
BA_ "GenSigCycleTime" SG_ 735 FifthWheelLockingInformation_ISi 100;
BA_ "GenSigCycleTimeActive" SG_ 735 FifthWheelLockingInformation_ISi 100;
BA_ "GenSigStartValue" SG_ 735 FifthWheelLockingInformation_ISi 15;
BA_ "GenSigMaxLatency" SG_ 735 FifthWheelLockingInformation_ISi 112;
BA_ "NeedsUpdateBit" SG_ 735 FifthWheelLockingInformation_ISi 1;
BA_ "Platform_VMCU1_Sig" SG_ 735 FifthWheelLockingInformation_ISi 1;
BA_ "SystemSignalLongSymbol" SG_ 735 FifthWheelLockingInformation_ISi "FifthWheelLockingInformation_ISig_4";
BA_ "GenSigCycleTime" SG_ 729 CCBSetSpeed 100;
BA_ "GenSigCycleTimeActive" SG_ 729 CCBSetSpeed 100;
BA_ "GenSigStartValue" SG_ 729 CCBSetSpeed 65535;
BA_ "GenSigMaxLatency" SG_ 729 CCBSetSpeed 34;
BA_ "Platform_VMCU1_Sig" SG_ 729 CCBSetSpeed 1;
BA_ "GenSigCycleTime" SG_ 729 ASLNotificationReq 100;
BA_ "GenSigCycleTimeActive" SG_ 729 ASLNotificationReq 100;
BA_ "GenSigStartValue" SG_ 729 ASLNotificationReq 7;
BA_ "GenSigMaxLatency" SG_ 729 ASLNotificationReq 34;
BA_ "Platform_VMCU1_Sig" SG_ 729 ASLNotificationReq 1;
BA_ "GenSigCycleTime" SG_ 729 GearRangeUnengaged_ISig_4 100;
BA_ "GenSigCycleTimeActive" SG_ 729 GearRangeUnengaged_ISig_4 100;
BA_ "GenSigStartValue" SG_ 729 GearRangeUnengaged_ISig_4 3;
BA_ "Platform_VMCU1_Sig" SG_ 729 GearRangeUnengaged_ISig_4 1;
BA_ "GenSigCycleTime" SG_ 729 LaneChangeStatus_ISig_4 100;
BA_ "GenSigCycleTimeActive" SG_ 729 LaneChangeStatus_ISig_4 100;
BA_ "GenSigStartValue" SG_ 729 LaneChangeStatus_ISig_4 15;
BA_ "Platform_VMCU1_Sig" SG_ 729 LaneChangeStatus_ISig_4 1;
BA_ "GenSigCycleTime" SG_ 729 ASLStates 100;
BA_ "GenSigCycleTimeActive" SG_ 729 ASLStates 100;
BA_ "GenSigStartValue" SG_ 729 ASLStates 15;
BA_ "GenSigMaxLatency" SG_ 729 ASLStates 34;
BA_ "Platform_VMCU1_Sig" SG_ 729 ASLStates 1;
BA_ "GenSigCycleTime" SG_ 729 ASLSetSpeed 100;
BA_ "GenSigCycleTimeActive" SG_ 729 ASLSetSpeed 100;
BA_ "GenSigStartValue" SG_ 729 ASLSetSpeed 65535;
BA_ "GenSigMaxLatency" SG_ 729 ASLSetSpeed 34;
BA_ "Platform_VMCU1_Sig" SG_ 729 ASLSetSpeed 1;
BA_ "GenSigCycleTime" SG_ 729 LongMotionDirection_ISig_4 20;
BA_ "GenSigCycleTimeActive" SG_ 729 LongMotionDirection_ISig_4 100;
BA_ "GenSigStartValue" SG_ 729 LongMotionDirection_ISig_4 7;
BA_ "Platform_VMCU1_Sig" SG_ 729 LongMotionDirection_ISig_4 1;
BA_ "GenSigCycleTime" SG_ 729 LongMotionDirectionQual_ISig_4 20;
BA_ "GenSigCycleTimeActive" SG_ 729 LongMotionDirectionQual_ISig_4 100;
BA_ "GenSigStartValue" SG_ 729 LongMotionDirectionQual_ISig_4 3;
BA_ "Platform_VMCU1_Sig" SG_ 729 LongMotionDirectionQual_ISig_4 1;
BA_ "GenSigSendType" SG_ 976 VMCU_BB2_34S_FCS 7;
BA_ "Platform_VMCU1_Sig" SG_ 976 VMCU_BB2_34S_FCS 1;
BA_ "GenSigSendType" SG_ 973 KeyID_KeyAuthEncrypted 1;
BA_ "GenSigMaxLatency" SG_ 973 KeyID_KeyAuthEncrypted 100;
BA_ "Platform_VMCU1_Sig" SG_ 973 KeyID_KeyAuthEncrypted 1;
BA_ "GenSigSendType" SG_ 1418 VMCU_BB2_33S_FCS 7;
BA_ "Platform_VMCU1_Sig" SG_ 1418 VMCU_BB2_33S_FCS 1;
BA_REL_ "GenSigFirstTimeoutTime" BU_SG_REL_ IC3 SG_ 1234 Trailer2TPMTireInfo_LeakageWarn_ 4800;
BA_REL_ "GenSigTimeoutTime" BU_SG_REL_ IC3 SG_ 1234 Trailer2TPMTireInfo_LeakageWarn_ 1200;
BA_REL_ "GenSigFirstTimeoutTime" BU_SG_REL_ IC3 SG_ 1234 Trailer2TPMTireInfo_RefPres_ISig 4800;
BA_REL_ "GenSigTimeoutTime" BU_SG_REL_ IC3 SG_ 1234 Trailer2TPMTireInfo_RefPres_ISig 1200;
BA_REL_ "GenSigFirstTimeoutTime" BU_SG_REL_ IC3 SG_ 1234 Trailer2TPMTireInfo_PresWarn_ISi 4800;
BA_REL_ "GenSigTimeoutTime" BU_SG_REL_ IC3 SG_ 1234 Trailer2TPMTireInfo_PresWarn_ISi 1200;
BA_REL_ "GenSigFirstTimeoutTime" BU_SG_REL_ IC3 SG_ 1234 Trailer2TPMTireInfo_Pressure_ISi 4800;
BA_REL_ "GenSigTimeoutTime" BU_SG_REL_ IC3 SG_ 1234 Trailer2TPMTireInfo_Pressure_ISi 1200;
BA_REL_ "GenSigFirstTimeoutTime" BU_SG_REL_ IC3 SG_ 1234 Trailer2TPMTireInfo_Temperature_ 4800;
BA_REL_ "GenSigTimeoutTime" BU_SG_REL_ IC3 SG_ 1234 Trailer2TPMTireInfo_Temperature_ 1200;
BA_REL_ "GenSigFirstTimeoutTime" BU_SG_REL_ IC3 SG_ 1234 Trailer2TPMTireInfo_TireId_ISig_ 4800;
BA_REL_ "GenSigTimeoutTime" BU_SG_REL_ IC3 SG_ 1234 Trailer2TPMTireInfo_TireId_ISig_ 1200;
BA_REL_ "GenSigFirstTimeoutTime" BU_SG_REL_ IC3 SG_ 1234 Trailer2TPMTireInfo_Battery_ISig 4800;
BA_REL_ "GenSigTimeoutTime" BU_SG_REL_ IC3 SG_ 1234 Trailer2TPMTireInfo_Battery_ISig 1200;
BA_REL_ "GenSigFirstTimeoutTime" BU_SG_REL_ IC3 SG_ 1234 Trailer2TPMTireInfo_Active_ISig_ 4800;
BA_REL_ "GenSigTimeoutTime" BU_SG_REL_ IC3 SG_ 1234 Trailer2TPMTireInfo_Active_ISig_ 1200;
BA_REL_ "GenSigFirstTimeoutTime" BU_SG_REL_ IC3 SG_ 1231 Trailer1TPMTireInfo_Battery_ISig 4800;
BA_REL_ "GenSigTimeoutTime" BU_SG_REL_ IC3 SG_ 1231 Trailer1TPMTireInfo_Battery_ISig 1200;
BA_REL_ "GenSigFirstTimeoutTime" BU_SG_REL_ IC3 SG_ 1231 Trailer1TPMTireInfo_Pressure_ISi 4800;
BA_REL_ "GenSigTimeoutTime" BU_SG_REL_ IC3 SG_ 1231 Trailer1TPMTireInfo_Pressure_ISi 1200;
BA_REL_ "GenSigFirstTimeoutTime" BU_SG_REL_ IC3 SG_ 1231 Trailer1TPMTireInfo_PresWarn_ISi 4800;
BA_REL_ "GenSigTimeoutTime" BU_SG_REL_ IC3 SG_ 1231 Trailer1TPMTireInfo_PresWarn_ISi 1200;
BA_REL_ "GenSigFirstTimeoutTime" BU_SG_REL_ IC3 SG_ 1231 Trailer1TPMTireInfo_LeakageWarn_ 4800;
BA_REL_ "GenSigTimeoutTime" BU_SG_REL_ IC3 SG_ 1231 Trailer1TPMTireInfo_LeakageWarn_ 1200;
BA_REL_ "GenSigFirstTimeoutTime" BU_SG_REL_ IC3 SG_ 1231 TPMPosOfWMResp_VehiclePos_ISig_4 4800;
BA_REL_ "GenSigTimeoutTime" BU_SG_REL_ IC3 SG_ 1231 TPMPosOfWMResp_VehiclePos_ISig_4 1200;
BA_REL_ "GenSigFirstTimeoutTime" BU_SG_REL_ IC3 SG_ 1231 Trailer1TPMTireInfo_TireId_ISig_ 4800;
BA_REL_ "GenSigTimeoutTime" BU_SG_REL_ IC3 SG_ 1231 Trailer1TPMTireInfo_TireId_ISig_ 1200;
BA_REL_ "GenSigFirstTimeoutTime" BU_SG_REL_ IC3 SG_ 1231 Trailer1TPMTireInfo_RefPres_ISig 4800;
BA_REL_ "GenSigTimeoutTime" BU_SG_REL_ IC3 SG_ 1231 Trailer1TPMTireInfo_RefPres_ISig 1200;
BA_REL_ "GenSigFirstTimeoutTime" BU_SG_REL_ IC3 SG_ 1231 Trailer1TPMTireInfo_Temperature_ 4800;
BA_REL_ "GenSigTimeoutTime" BU_SG_REL_ IC3 SG_ 1231 Trailer1TPMTireInfo_Temperature_ 1200;
BA_REL_ "GenSigFirstTimeoutTime" BU_SG_REL_ IC3 SG_ 1231 Trailer1TPMTireInfo_Active_ISig_ 4800;
BA_REL_ "GenSigTimeoutTime" BU_SG_REL_ IC3 SG_ 1231 Trailer1TPMTireInfo_Active_ISig_ 1200;
BA_REL_ "GenSigFirstTimeoutTime" BU_SG_REL_ IC3 SG_ 1231 TPMPosOfWMResp_Status_ISig_4 4800;
BA_REL_ "GenSigTimeoutTime" BU_SG_REL_ IC3 SG_ 1231 TPMPosOfWMResp_Status_ISig_4 1200;
BA_REL_ "GenSigFirstTimeoutTime" BU_SG_REL_ IC3 SG_ 1231 TPMPosOfWMResp_TireId_ISig_4 4800;
BA_REL_ "GenSigTimeoutTime" BU_SG_REL_ IC3 SG_ 1231 TPMPosOfWMResp_TireId_ISig_4 1200;
BA_REL_ "GenSigFirstTimeoutTime" BU_SG_REL_ IC3 SG_ 1403 TruckTPMThresCfg_OverPres_ISig_4 24000;
BA_REL_ "GenSigTimeoutTime" BU_SG_REL_ IC3 SG_ 1403 TruckTPMThresCfg_OverPres_ISig_4 6000;
BA_REL_ "GenSigFirstTimeoutTime" BU_SG_REL_ IC3 SG_ 1403 TruckTPMAxlTireCfg_Axle2_ISig_4 24000;
BA_REL_ "GenSigTimeoutTime" BU_SG_REL_ IC3 SG_ 1403 TruckTPMAxlTireCfg_Axle2_ISig_4 6000;
BA_REL_ "GenSigFirstTimeoutTime" BU_SG_REL_ IC3 SG_ 1403 TruckTPMAxlTireCfg_Axle1_ISig_4 24000;
BA_REL_ "GenSigTimeoutTime" BU_SG_REL_ IC3 SG_ 1403 TruckTPMAxlTireCfg_Axle1_ISig_4 6000;
BA_REL_ "GenSigFirstTimeoutTime" BU_SG_REL_ IC3 SG_ 1403 TruckTPMAxlTireCfg_Axle5_ISig_4 24000;
BA_REL_ "GenSigTimeoutTime" BU_SG_REL_ IC3 SG_ 1403 TruckTPMAxlTireCfg_Axle5_ISig_4 6000;
BA_REL_ "GenSigFirstTimeoutTime" BU_SG_REL_ IC3 SG_ 1403 TruckTPMAxlTireCfg_Axle4_ISig_4 24000;
BA_REL_ "GenSigTimeoutTime" BU_SG_REL_ IC3 SG_ 1403 TruckTPMAxlTireCfg_Axle4_ISig_4 6000;
BA_REL_ "GenSigFirstTimeoutTime" BU_SG_REL_ IC3 SG_ 1403 TruckTPMThresCfg_ExtUnderPres_IS 24000;
BA_REL_ "GenSigTimeoutTime" BU_SG_REL_ IC3 SG_ 1403 TruckTPMThresCfg_ExtUnderPres_IS 6000;
BA_REL_ "GenSigFirstTimeoutTime" BU_SG_REL_ IC3 SG_ 1403 TruckTPMThresCfg_AxleNr_ISig_4 24000;
BA_REL_ "GenSigTimeoutTime" BU_SG_REL_ IC3 SG_ 1403 TruckTPMThresCfg_AxleNr_ISig_4 6000;
BA_REL_ "GenSigFirstTimeoutTime" BU_SG_REL_ IC3 SG_ 1403 TruckTPMThresCfg_UnderPres_ISig_ 24000;
BA_REL_ "GenSigTimeoutTime" BU_SG_REL_ IC3 SG_ 1403 TruckTPMThresCfg_UnderPres_ISig_ 6000;
BA_REL_ "GenSigFirstTimeoutTime" BU_SG_REL_ IC3 SG_ 1403 TruckTPMThresCfg_ExtOverPres_ISi 24000;
BA_REL_ "GenSigTimeoutTime" BU_SG_REL_ IC3 SG_ 1403 TruckTPMThresCfg_ExtOverPres_ISi 6000;
BA_REL_ "GenSigFirstTimeoutTime" BU_SG_REL_ IC3 SG_ 1403 TruckTPMAxlTireCfg_Axle3_ISig_4 24000;
BA_REL_ "GenSigTimeoutTime" BU_SG_REL_ IC3 SG_ 1403 TruckTPMAxlTireCfg_Axle3_ISig_4 6000;
BA_REL_ "GenSigFirstTimeoutTime" BU_SG_REL_ IC3 SG_ 1402 Trailer2TPMType_ISig_4 24000;
BA_REL_ "GenSigTimeoutTime" BU_SG_REL_ IC3 SG_ 1402 Trailer2TPMType_ISig_4 6000;
BA_REL_ "GenSigFirstTimeoutTime" BU_SG_REL_ IC3 SG_ 1402 Trailer2TPMAxlTireCfg_Axle1_ISig 24000;
BA_REL_ "GenSigTimeoutTime" BU_SG_REL_ IC3 SG_ 1402 Trailer2TPMAxlTireCfg_Axle1_ISig 6000;
BA_REL_ "GenSigFirstTimeoutTime" BU_SG_REL_ IC3 SG_ 1402 Trailer2TPMThresCfg_OverPres_ISi 24000;
BA_REL_ "GenSigTimeoutTime" BU_SG_REL_ IC3 SG_ 1402 Trailer2TPMThresCfg_OverPres_ISi 6000;
BA_REL_ "GenSigFirstTimeoutTime" BU_SG_REL_ IC3 SG_ 1402 Trailer2TPMAxlTireCfg_Axle3_ISig 24000;
BA_REL_ "GenSigTimeoutTime" BU_SG_REL_ IC3 SG_ 1402 Trailer2TPMAxlTireCfg_Axle3_ISig 6000;
BA_REL_ "GenSigFirstTimeoutTime" BU_SG_REL_ IC3 SG_ 1402 Trailer2TPMAxlTireCfg_Axle2_ISig 24000;
BA_REL_ "GenSigTimeoutTime" BU_SG_REL_ IC3 SG_ 1402 Trailer2TPMAxlTireCfg_Axle2_ISig 6000;
BA_REL_ "GenSigFirstTimeoutTime" BU_SG_REL_ IC3 SG_ 1402 Trailer2TPMAxlTireCfg_Axle5_ISig 24000;
BA_REL_ "GenSigTimeoutTime" BU_SG_REL_ IC3 SG_ 1402 Trailer2TPMAxlTireCfg_Axle5_ISig 6000;
BA_REL_ "GenSigFirstTimeoutTime" BU_SG_REL_ IC3 SG_ 1402 Trailer2TPMAxlTireCfg_Axle4_ISig 24000;
BA_REL_ "GenSigTimeoutTime" BU_SG_REL_ IC3 SG_ 1402 Trailer2TPMAxlTireCfg_Axle4_ISig 6000;
BA_REL_ "GenSigFirstTimeoutTime" BU_SG_REL_ IC3 SG_ 1402 Trailer2TPMThresCfg_AxleNr_ISig_ 24000;
BA_REL_ "GenSigTimeoutTime" BU_SG_REL_ IC3 SG_ 1402 Trailer2TPMThresCfg_AxleNr_ISig_ 6000;
BA_REL_ "GenSigFirstTimeoutTime" BU_SG_REL_ IC3 SG_ 1402 Trailer2TPMThresCfg_ExtOverPres_ 24000;
BA_REL_ "GenSigTimeoutTime" BU_SG_REL_ IC3 SG_ 1402 Trailer2TPMThresCfg_ExtOverPres_ 6000;
BA_REL_ "GenSigFirstTimeoutTime" BU_SG_REL_ IC3 SG_ 1402 Trailer2TPMThresCfg_UnderPres_IS 24000;
BA_REL_ "GenSigTimeoutTime" BU_SG_REL_ IC3 SG_ 1402 Trailer2TPMThresCfg_UnderPres_IS 6000;
BA_REL_ "GenSigFirstTimeoutTime" BU_SG_REL_ IC3 SG_ 1402 Trailer2TPMThresCfg_ExtUnderPres 24000;
BA_REL_ "GenSigTimeoutTime" BU_SG_REL_ IC3 SG_ 1402 Trailer2TPMThresCfg_ExtUnderPres 6000;
BA_REL_ "GenSigFirstTimeoutTime" BU_SG_REL_ IC3 SG_ 1401 Trailer1TPMAxlTireCfg_Axle1_ISig 24000;
BA_REL_ "GenSigTimeoutTime" BU_SG_REL_ IC3 SG_ 1401 Trailer1TPMAxlTireCfg_Axle1_ISig 6000;
BA_REL_ "GenSigFirstTimeoutTime" BU_SG_REL_ IC3 SG_ 1401 Trailer1TPMThresCfg_ExtOverPres_ 24000;
BA_REL_ "GenSigTimeoutTime" BU_SG_REL_ IC3 SG_ 1401 Trailer1TPMThresCfg_ExtOverPres_ 6000;
BA_REL_ "GenSigFirstTimeoutTime" BU_SG_REL_ IC3 SG_ 1401 Trailer1TPMAxlTireCfg_Axle2_ISig 24000;
BA_REL_ "GenSigTimeoutTime" BU_SG_REL_ IC3 SG_ 1401 Trailer1TPMAxlTireCfg_Axle2_ISig 6000;
BA_REL_ "GenSigFirstTimeoutTime" BU_SG_REL_ IC3 SG_ 1401 Trailer1TPMThresCfg_OverPres_ISi 24000;
BA_REL_ "GenSigTimeoutTime" BU_SG_REL_ IC3 SG_ 1401 Trailer1TPMThresCfg_OverPres_ISi 6000;
BA_REL_ "GenSigFirstTimeoutTime" BU_SG_REL_ IC3 SG_ 1401 Trailer1TPMAxlTireCfg_Axle5_ISig 24000;
BA_REL_ "GenSigTimeoutTime" BU_SG_REL_ IC3 SG_ 1401 Trailer1TPMAxlTireCfg_Axle5_ISig 6000;
BA_REL_ "GenSigFirstTimeoutTime" BU_SG_REL_ IC3 SG_ 1401 Trailer1TPMType_ISig_4 24000;
BA_REL_ "GenSigTimeoutTime" BU_SG_REL_ IC3 SG_ 1401 Trailer1TPMType_ISig_4 6000;
BA_REL_ "GenSigFirstTimeoutTime" BU_SG_REL_ IC3 SG_ 1401 MaintResetFailureCause 24000;
BA_REL_ "GenSigTimeoutTime" BU_SG_REL_ IC3 SG_ 1401 MaintResetFailureCause 6000;
BA_REL_ "GenSigFirstTimeoutTime" BU_SG_REL_ IC3 SG_ 1401 Trailer1TPMThresCfg_UnderPres_IS 24000;
BA_REL_ "GenSigTimeoutTime" BU_SG_REL_ IC3 SG_ 1401 Trailer1TPMThresCfg_UnderPres_IS 6000;
BA_REL_ "GenSigFirstTimeoutTime" BU_SG_REL_ IC3 SG_ 1401 Trailer1TPMThresCfg_ExtUnderPres 24000;
BA_REL_ "GenSigTimeoutTime" BU_SG_REL_ IC3 SG_ 1401 Trailer1TPMThresCfg_ExtUnderPres 6000;
BA_REL_ "GenSigFirstTimeoutTime" BU_SG_REL_ IC3 SG_ 1401 Trailer1TPMThresCfg_AxleNr_ISig_ 24000;
BA_REL_ "GenSigTimeoutTime" BU_SG_REL_ IC3 SG_ 1401 Trailer1TPMThresCfg_AxleNr_ISig_ 6000;
BA_REL_ "GenSigFirstTimeoutTime" BU_SG_REL_ IC3 SG_ 1401 Trailer1TPMAxlTireCfg_Axle4_ISig 24000;
BA_REL_ "GenSigTimeoutTime" BU_SG_REL_ IC3 SG_ 1401 Trailer1TPMAxlTireCfg_Axle4_ISig 6000;
BA_REL_ "GenSigFirstTimeoutTime" BU_SG_REL_ IC3 SG_ 1401 Trailer1TPMAxlTireCfg_Axle3_ISig 24000;
BA_REL_ "GenSigTimeoutTime" BU_SG_REL_ IC3 SG_ 1401 Trailer1TPMAxlTireCfg_Axle3_ISig 6000;
BA_REL_ "GenSigFirstTimeoutTime" BU_SG_REL_ IC3 SG_ 1436 DistToEmptyLNG 24000;
BA_REL_ "GenSigTimeoutTime" BU_SG_REL_ IC3 SG_ 1436 DistToEmptyLNG 6000;
BA_REL_ "GenSigFirstTimeoutTime" BU_SG_REL_ IC3 SG_ 1436 DistToEmptyDiesel 24000;
BA_REL_ "GenSigTimeoutTime" BU_SG_REL_ IC3 SG_ 1436 DistToEmptyDiesel 6000;
BA_REL_ "GenSigFirstTimeoutTime" BU_SG_REL_ IC3 SG_ 1436 CoastingUseDistance_ISig_4 24000;
BA_REL_ "GenSigTimeoutTime" BU_SG_REL_ IC3 SG_ 1436 CoastingUseDistance_ISig_4 6000;
BA_REL_ "GenSigFirstTimeoutTime" BU_SG_REL_ IC3 SG_ 1435 EngSpeedOverThresholdTime_ISig_4 24000;
BA_REL_ "GenSigTimeoutTime" BU_SG_REL_ IC3 SG_ 1435 EngSpeedOverThresholdTime_ISig_4 6000;
BA_REL_ "GenSigFirstTimeoutTime" BU_SG_REL_ IC3 SG_ 1435 EngLoadOverThresholdDistance_ISi 24000;
BA_REL_ "GenSigTimeoutTime" BU_SG_REL_ IC3 SG_ 1435 EngLoadOverThresholdDistance_ISi 6000;
BA_REL_ "GenSigFirstTimeoutTime" BU_SG_REL_ IC3 SG_ 1434 EngineGreenAreaFuel_ISig_4 24000;
BA_REL_ "GenSigTimeoutTime" BU_SG_REL_ IC3 SG_ 1434 EngineGreenAreaFuel_ISig_4 6000;
BA_REL_ "GenSigFirstTimeoutTime" BU_SG_REL_ IC3 SG_ 1434 LCCDistance_ISig_4 24000;
BA_REL_ "GenSigTimeoutTime" BU_SG_REL_ IC3 SG_ 1434 LCCDistance_ISig_4 6000;
BA_REL_ "GenSigFirstTimeoutTime" BU_SG_REL_ IC3 SG_ 1433 StopCounter_ISig_4 24000;
BA_REL_ "GenSigTimeoutTime" BU_SG_REL_ IC3 SG_ 1433 StopCounter_ISig_4 6000;
BA_REL_ "GenSigFirstTimeoutTime" BU_SG_REL_ IC3 SG_ 1433 OverspeedDistance_ISig_4 24000;
BA_REL_ "GenSigTimeoutTime" BU_SG_REL_ IC3 SG_ 1433 OverspeedDistance_ISig_4 6000;
BA_REL_ "GenSigFirstTimeoutTime" BU_SG_REL_ IC3 SG_ 1432 RobotizedGboxPowerModeTime_ISig_ 24000;
BA_REL_ "GenSigTimeoutTime" BU_SG_REL_ IC3 SG_ 1432 RobotizedGboxPowerModeTime_ISig_ 6000;
BA_REL_ "GenSigFirstTimeoutTime" BU_SG_REL_ IC3 SG_ 1432 TotalServiceBrakeCounter_ISig_4 24000;
BA_REL_ "GenSigTimeoutTime" BU_SG_REL_ IC3 SG_ 1432 TotalServiceBrakeCounter_ISig_4 6000;
BA_REL_ "GenSigFirstTimeoutTime" BU_SG_REL_ IC3 SG_ 1431 RobotizedGboxManualModeTime_ISig 24000;
BA_REL_ "GenSigTimeoutTime" BU_SG_REL_ IC3 SG_ 1431 RobotizedGboxManualModeTime_ISig 6000;
BA_REL_ "GenSigFirstTimeoutTime" BU_SG_REL_ IC3 SG_ 1431 RobotizedGboxAutoModeTime_ISig_4 24000;
BA_REL_ "GenSigTimeoutTime" BU_SG_REL_ IC3 SG_ 1431 RobotizedGboxAutoModeTime_ISig_4 6000;
BA_REL_ "GenSigFirstTimeoutTime" BU_SG_REL_ TECU SG_ 1246 PusherAxleLoad_ISig_4 6000;
BA_REL_ "GenSigTimeoutTime" BU_SG_REL_ TECU SG_ 1246 PusherAxleLoad_ISig_4 1500;
BA_REL_ "GenSigFirstTimeoutTime" BU_SG_REL_ BBM SG_ 1246 PusherAxleLoad_ISig_4 6000;
BA_REL_ "GenSigTimeoutTime" BU_SG_REL_ BBM SG_ 1246 PusherAxleLoad_ISig_4 1500;
BA_REL_ "GenSigFirstTimeoutTime" BU_SG_REL_ DACU SG_ 1246 PusherAxleLoad_ISig_4 6000;
BA_REL_ "GenSigTimeoutTime" BU_SG_REL_ DACU SG_ 1246 PusherAxleLoad_ISig_4 1500;
BA_REL_ "GenSigFirstTimeoutTime" BU_SG_REL_ BBM SG_ 1246 FogLight_Front_cmd_ISig_4 6000;
BA_REL_ "GenSigTimeoutTime" BU_SG_REL_ BBM SG_ 1246 FogLight_Front_cmd_ISig_4 1500;
BA_REL_ "GenSigFirstTimeoutTime" BU_SG_REL_ TECU SG_ 1246 TagAxleLoad_ISig_4 6000;
BA_REL_ "GenSigTimeoutTime" BU_SG_REL_ TECU SG_ 1246 TagAxleLoad_ISig_4 1500;
BA_REL_ "GenSigFirstTimeoutTime" BU_SG_REL_ DACU SG_ 1246 TagAxleLoad_ISig_4 6000;
BA_REL_ "GenSigTimeoutTime" BU_SG_REL_ DACU SG_ 1246 TagAxleLoad_ISig_4 1500;
BA_REL_ "GenSigFirstTimeoutTime" BU_SG_REL_ BBM SG_ 1246 TagAxleLoad_ISig_4 6000;
BA_REL_ "GenSigTimeoutTime" BU_SG_REL_ BBM SG_ 1246 TagAxleLoad_ISig_4 1500;
BA_REL_ "GenSigFirstTimeoutTime" BU_SG_REL_ IC3 SG_ 1243 SelfStartAssistSwitch_Input_ISig 6000;
BA_REL_ "GenSigTimeoutTime" BU_SG_REL_ IC3 SG_ 1243 SelfStartAssistSwitch_Input_ISig 1500;
BA_REL_ "GenSigFirstTimeoutTime" BU_SG_REL_ BBM SG_ 1243 DriveAxleLoad_ISig_4 6000;
BA_REL_ "GenSigTimeoutTime" BU_SG_REL_ BBM SG_ 1243 DriveAxleLoad_ISig_4 1500;
BA_REL_ "GenSigFirstTimeoutTime" BU_SG_REL_ DACU SG_ 1243 DriveAxleLoad_ISig_4 6000;
BA_REL_ "GenSigTimeoutTime" BU_SG_REL_ DACU SG_ 1243 DriveAxleLoad_ISig_4 1500;
BA_REL_ "GenSigFirstTimeoutTime" BU_SG_REL_ TECU SG_ 1243 DriveAxleLoad_ISig_4 6000;
BA_REL_ "GenSigTimeoutTime" BU_SG_REL_ TECU SG_ 1243 DriveAxleLoad_ISig_4 1500;
BA_REL_ "GenSigFirstTimeoutTime" BU_SG_REL_ BBM SG_ 1243 BatterySOCAlertRawData_rqst_ISig 6000;
BA_REL_ "GenSigTimeoutTime" BU_SG_REL_ BBM SG_ 1243 BatterySOCAlertRawData_rqst_ISig 1500;
BA_REL_ "GenSigFirstTimeoutTime" BU_SG_REL_ CIOM SG_ 1243 BatterySOCAlertRawData_rqst_ISig 6000;
BA_REL_ "GenSigTimeoutTime" BU_SG_REL_ CIOM SG_ 1243 BatterySOCAlertRawData_rqst_ISig 1500;
BA_REL_ "GenSigFirstTimeoutTime" BU_SG_REL_ IC3 SG_ 1243 LivBatDisconnectDetectStat_ISig_ 6000;
BA_REL_ "GenSigTimeoutTime" BU_SG_REL_ IC3 SG_ 1243 LivBatDisconnectDetectStat_ISig_ 1500;
BA_REL_ "GenSigFirstTimeoutTime" BU_SG_REL_ EMS SG_ 1243 SelfStartAssist_stat_ISig_4 6000;
BA_REL_ "GenSigTimeoutTime" BU_SG_REL_ EMS SG_ 1243 SelfStartAssist_stat_ISig_4 1500;
BA_REL_ "GenSigFirstTimeoutTime" BU_SG_REL_ IC3 SG_ 1243 SelfStartAssist_stat_ISig_4 6000;
BA_REL_ "GenSigTimeoutTime" BU_SG_REL_ IC3 SG_ 1243 SelfStartAssist_stat_ISig_4 1500;
BA_REL_ "GenSigFirstTimeoutTime" BU_SG_REL_ IC3 SG_ 1243 JumpChargeAlert_stat_ISig_4 6000;
BA_REL_ "GenSigTimeoutTime" BU_SG_REL_ IC3 SG_ 1243 JumpChargeAlert_stat_ISig_4 1500;
BA_REL_ "GenSigFirstTimeoutTime" BU_SG_REL_ IC3 SG_ 1243 GChargerStatus_ISig_4 6000;
BA_REL_ "GenSigTimeoutTime" BU_SG_REL_ IC3 SG_ 1243 GChargerStatus_ISig_4 1500;
BA_REL_ "GenSigFirstTimeoutTime" BU_SG_REL_ CIOM SG_ 1243 ShortStopHeater_status_ISig_4 6000;
BA_REL_ "GenSigTimeoutTime" BU_SG_REL_ CIOM SG_ 1243 ShortStopHeater_status_ISig_4 1500;
BA_REL_ "GenSigFirstTimeoutTime" BU_SG_REL_ DACU SG_ 1243 SecondaryDriveAxleLoad_ISig_4 6000;
BA_REL_ "GenSigTimeoutTime" BU_SG_REL_ DACU SG_ 1243 SecondaryDriveAxleLoad_ISig_4 1500;
BA_REL_ "GenSigFirstTimeoutTime" BU_SG_REL_ BBM SG_ 1243 SecondaryDriveAxleLoad_ISig_4 6000;
BA_REL_ "GenSigTimeoutTime" BU_SG_REL_ BBM SG_ 1243 SecondaryDriveAxleLoad_ISig_4 1500;
BA_REL_ "GenSigFirstTimeoutTime" BU_SG_REL_ TECU SG_ 1243 SecondaryDriveAxleLoad_ISig_4 6000;
BA_REL_ "GenSigTimeoutTime" BU_SG_REL_ TECU SG_ 1243 SecondaryDriveAxleLoad_ISig_4 1500;
BA_REL_ "GenSigFirstTimeoutTime" BU_SG_REL_ IC3 SG_ 1243 StartBatteryDisplay_stat_ISig_4 6000;
BA_REL_ "GenSigTimeoutTime" BU_SG_REL_ IC3 SG_ 1243 StartBatteryDisplay_stat_ISig_4 1500;
BA_REL_ "GenSigFirstTimeoutTime" BU_SG_REL_ IC3 SG_ 1408 MaintService_ServiceCalendarTime 24000;
BA_REL_ "GenSigTimeoutTime" BU_SG_REL_ IC3 SG_ 1408 MaintService_ServiceCalendarTime 6000;
BA_REL_ "GenSigFirstTimeoutTime" BU_SG_REL_ IC3 SG_ 1408 MaintService_EngTimeID_ISig_4_58 24000;
BA_REL_ "GenSigTimeoutTime" BU_SG_REL_ IC3 SG_ 1408 MaintService_EngTimeID_ISig_4_58 6000;
BA_REL_ "GenSigFirstTimeoutTime" BU_SG_REL_ IC3 SG_ 1408 MaintService_DistID_ISig_4_580 24000;
BA_REL_ "GenSigTimeoutTime" BU_SG_REL_ IC3 SG_ 1408 MaintService_DistID_ISig_4_580 6000;
BA_REL_ "GenSigFirstTimeoutTime" BU_SG_REL_ IC3 SG_ 1408 MaintService_ServiceDistance_ISi 24000;
BA_REL_ "GenSigTimeoutTime" BU_SG_REL_ IC3 SG_ 1408 MaintService_ServiceDistance_ISi 6000;
BA_REL_ "GenSigFirstTimeoutTime" BU_SG_REL_ IC3 SG_ 1408 MaintService_ServiceEngineTime_I 24000;
BA_REL_ "GenSigTimeoutTime" BU_SG_REL_ IC3 SG_ 1408 MaintService_ServiceEngineTime_I 6000;
BA_REL_ "GenSigFirstTimeoutTime" BU_SG_REL_ IC3 SG_ 1408 MaintService_CalDateID_ISig_4_58 24000;
BA_REL_ "GenSigTimeoutTime" BU_SG_REL_ IC3 SG_ 1408 MaintService_CalDateID_ISig_4_58 6000;
BA_REL_ "GenSigFirstTimeoutTime" BU_SG_REL_ CIOM SG_ 1398 MaintService_ServiceEngineT_0000 24000;
BA_REL_ "GenSigTimeoutTime" BU_SG_REL_ CIOM SG_ 1398 MaintService_ServiceEngineT_0000 6000;
BA_REL_ "GenSigFirstTimeoutTime" BU_SG_REL_ CIOM SG_ 1398 MaintService_EngTimeID_ISig_4_57 24000;
BA_REL_ "GenSigTimeoutTime" BU_SG_REL_ CIOM SG_ 1398 MaintService_EngTimeID_ISig_4_57 6000;
BA_REL_ "GenSigFirstTimeoutTime" BU_SG_REL_ CIOM SG_ 1398 MaintService_DistID_ISig_4_576 24000;
BA_REL_ "GenSigTimeoutTime" BU_SG_REL_ CIOM SG_ 1398 MaintService_DistID_ISig_4_576 6000;
BA_REL_ "GenSigFirstTimeoutTime" BU_SG_REL_ CIOM SG_ 1398 MaintService_ServiceDistanc_0000 24000;
BA_REL_ "GenSigTimeoutTime" BU_SG_REL_ CIOM SG_ 1398 MaintService_ServiceDistanc_0000 6000;
BA_REL_ "GenSigFirstTimeoutTime" BU_SG_REL_ CIOM SG_ 1398 MaintService_CalDateID_ISig_4_57 24000;
BA_REL_ "GenSigTimeoutTime" BU_SG_REL_ CIOM SG_ 1398 MaintService_CalDateID_ISig_4_57 6000;
BA_REL_ "GenSigFirstTimeoutTime" BU_SG_REL_ CIOM SG_ 1398 MaintService_ServiceCalenda_0000 24000;
BA_REL_ "GenSigTimeoutTime" BU_SG_REL_ CIOM SG_ 1398 MaintService_ServiceCalenda_0000 6000;
BA_REL_ "GenSigFirstTimeoutTime" BU_SG_REL_ IC3 SG_ 1428 EngTrueIdleSpeedTime_ISig_4 24000;
BA_REL_ "GenSigTimeoutTime" BU_SG_REL_ IC3 SG_ 1428 EngTrueIdleSpeedTime_ISig_4 6000;
BA_REL_ "GenSigFirstTimeoutTime" BU_SG_REL_ IC3 SG_ 1428 EngineGreenAreaOutTime_ISig_4 24000;
BA_REL_ "GenSigTimeoutTime" BU_SG_REL_ IC3 SG_ 1428 EngineGreenAreaOutTime_ISig_4 6000;
BA_REL_ "GenSigFirstTimeoutTime" BU_SG_REL_ IC3 SG_ 1059 BatterySOCnom_ISig_4 3600;
BA_REL_ "GenSigTimeoutTime" BU_SG_REL_ IC3 SG_ 1059 BatterySOCnom_ISig_4 900;
BA_REL_ "GenSigFirstTimeoutTime" BU_SG_REL_ IC3 SG_ 1059 BatterySOH_ISig_4 3600;
BA_REL_ "GenSigTimeoutTime" BU_SG_REL_ IC3 SG_ 1059 BatterySOH_ISig_4 900;
BA_REL_ "GenSigFirstTimeoutTime" BU_SG_REL_ CIOM SG_ 1059 ReducedLoadMode_stat_ISig_4 3600;
BA_REL_ "GenSigTimeoutTime" BU_SG_REL_ CIOM SG_ 1059 ReducedLoadMode_stat_ISig_4 900;
BA_REL_ "GenSigFirstTimeoutTime" BU_SG_REL_ IC3 SG_ 1059 BatterySOCAlert_rqst_ISig_4 3600;
BA_REL_ "GenSigTimeoutTime" BU_SG_REL_ IC3 SG_ 1059 BatterySOCAlert_rqst_ISig_4 900;
BA_REL_ "GenSigFirstTimeoutTime" BU_SG_REL_ BBM SG_ 1059 BatterySOCAlert_rqst_ISig_4 3600;
BA_REL_ "GenSigTimeoutTime" BU_SG_REL_ BBM SG_ 1059 BatterySOCAlert_rqst_ISig_4 900;
BA_REL_ "GenSigFirstTimeoutTime" BU_SG_REL_ CIOM SG_ 1059 BatterySOCAlert_rqst_ISig_4 3600;
BA_REL_ "GenSigTimeoutTime" BU_SG_REL_ CIOM SG_ 1059 BatterySOCAlert_rqst_ISig_4 900;
BA_REL_ "GenSigFirstTimeoutTime" BU_SG_REL_ IC3 SG_ 1059 BatteryVoltageDisplayValue_ISig_ 3600;
BA_REL_ "GenSigTimeoutTime" BU_SG_REL_ IC3 SG_ 1059 BatteryVoltageDisplayValue_ISig_ 900;
BA_REL_ "GenSigFirstTimeoutTime" BU_SG_REL_ BBM SG_ 1059 BatteryVoltageDisplayValue_ISig_ 3600;
BA_REL_ "GenSigTimeoutTime" BU_SG_REL_ BBM SG_ 1059 BatteryVoltageDisplayValue_ISig_ 900;
BA_REL_ "GenSigFirstTimeoutTime" BU_SG_REL_ EMS SG_ 1059 BatteryCurrent_ISig_4 3600;
BA_REL_ "GenSigTimeoutTime" BU_SG_REL_ EMS SG_ 1059 BatteryCurrent_ISig_4 900;
BA_REL_ "GenSigFirstTimeoutTime" BU_SG_REL_ IC3 SG_ 1059 BatteryCurrent_ISig_4 3600;
BA_REL_ "GenSigTimeoutTime" BU_SG_REL_ IC3 SG_ 1059 BatteryCurrent_ISig_4 900;
BA_REL_ "GenSigFirstTimeoutTime" BU_SG_REL_ EMS SG_ 925 MaintOilQuality 3000;
BA_REL_ "GenSigTimeoutTime" BU_SG_REL_ EMS SG_ 925 MaintOilQuality 450;
BA_REL_ "GenSigFirstTimeoutTime" BU_SG_REL_ IC3 SG_ 925 ECSLimpHomeNotification_ISig_4 3000;
BA_REL_ "GenSigTimeoutTime" BU_SG_REL_ IC3 SG_ 925 ECSLimpHomeNotification_ISig_4 450;
BA_REL_ "GenSigFirstTimeoutTime" BU_SG_REL_ IC3 SG_ 925 MaintenanceResetStatus 3000;
BA_REL_ "GenSigTimeoutTime" BU_SG_REL_ IC3 SG_ 925 MaintenanceResetStatus 450;
BA_REL_ "GenSigFirstTimeoutTime" BU_SG_REL_ IC3 SG_ 925 FirstAxleLowerPrioSelected_ISig_ 3000;
BA_REL_ "GenSigTimeoutTime" BU_SG_REL_ IC3 SG_ 925 FirstAxleLowerPrioSelected_ISig_ 450;
BA_REL_ "GenSigFirstTimeoutTime" BU_SG_REL_ EMS SG_ 925 MaintOilReset 3000;
BA_REL_ "GenSigTimeoutTime" BU_SG_REL_ EMS SG_ 925 MaintOilReset 450;
BA_REL_ "GenSigFirstTimeoutTime" BU_SG_REL_ IC3 SG_ 925 RssInhibStartEngine_rqst 3000;
BA_REL_ "GenSigTimeoutTime" BU_SG_REL_ IC3 SG_ 925 RssInhibStartEngine_rqst 450;
BA_REL_ "GenSigFirstTimeoutTime" BU_SG_REL_ BBM SG_ 925 PositionLightRequest_status 3000;
BA_REL_ "GenSigTimeoutTime" BU_SG_REL_ BBM SG_ 925 PositionLightRequest_status 450;
BA_REL_ "GenSigFirstTimeoutTime" BU_SG_REL_ IC3 SG_ 925 PositionLightRequest_status 3000;
BA_REL_ "GenSigTimeoutTime" BU_SG_REL_ IC3 SG_ 925 PositionLightRequest_status 450;
BA_REL_ "GenSigFirstTimeoutTime" BU_SG_REL_ CIOM SG_ 925 ExtraBBTailLiftStatus_ISig_4 3000;
BA_REL_ "GenSigTimeoutTime" BU_SG_REL_ CIOM SG_ 925 ExtraBBTailLiftStatus_ISig_4 450;
BA_REL_ "GenSigFirstTimeoutTime" BU_SG_REL_ IC3 SG_ 925 MaintenanceNotification_ISig_4 3000;
BA_REL_ "GenSigTimeoutTime" BU_SG_REL_ IC3 SG_ 925 MaintenanceNotification_ISig_4 450;
BA_REL_ "GenSigFirstTimeoutTime" BU_SG_REL_ BBM SG_ 925 ExtraBBSlidable5thWheelStatus 3000;
BA_REL_ "GenSigTimeoutTime" BU_SG_REL_ BBM SG_ 925 ExtraBBSlidable5thWheelStatus 450;
BA_REL_ "GenSigFirstTimeoutTime" BU_SG_REL_ CIOM SG_ 925 ExtraBBSlidable5thWheelStatus 3000;
BA_REL_ "GenSigTimeoutTime" BU_SG_REL_ CIOM SG_ 925 ExtraBBSlidable5thWheelStatus 450;
BA_REL_ "GenSigFirstTimeoutTime" BU_SG_REL_ TECU SG_ 925 ParkBrakeReleasePossible_stat 3000;
BA_REL_ "GenSigTimeoutTime" BU_SG_REL_ TECU SG_ 925 ParkBrakeReleasePossible_stat 450;
BA_REL_ "GenSigFirstTimeoutTime" BU_SG_REL_ IC3 SG_ 925 ParkBrakeReleasePossible_stat 3000;
BA_REL_ "GenSigTimeoutTime" BU_SG_REL_ IC3 SG_ 925 ParkBrakeReleasePossible_stat 450;
BA_REL_ "GenSigFirstTimeoutTime" BU_SG_REL_ CIOM SG_ 925 LoadDistributionALDChangeACK_ISi 3000;
BA_REL_ "GenSigTimeoutTime" BU_SG_REL_ CIOM SG_ 925 LoadDistributionALDChangeACK_ISi 450;
BA_REL_ "GenSigFirstTimeoutTime" BU_SG_REL_ IC3 SG_ 925 LoadDistributionALDChangeACK_ISi 3000;
BA_REL_ "GenSigTimeoutTime" BU_SG_REL_ IC3 SG_ 925 LoadDistributionALDChangeACK_ISi 450;
BA_REL_ "GenSigFirstTimeoutTime" BU_SG_REL_ IC3 SG_ 925 ParkBrakeWorkshopMode_ISig_4 3000;
BA_REL_ "GenSigTimeoutTime" BU_SG_REL_ IC3 SG_ 925 ParkBrakeWorkshopMode_ISig_4 450;
BA_REL_ "GenSigFirstTimeoutTime" BU_SG_REL_ BBM SG_ 925 ExtraBBContainerUnlockStatus 3000;
BA_REL_ "GenSigTimeoutTime" BU_SG_REL_ BBM SG_ 925 ExtraBBContainerUnlockStatus 450;
BA_REL_ "GenSigFirstTimeoutTime" BU_SG_REL_ CIOM SG_ 925 ExtraBBContainerUnlockStatus 3000;
BA_REL_ "GenSigTimeoutTime" BU_SG_REL_ CIOM SG_ 925 ExtraBBContainerUnlockStatus 450;
BA_REL_ "GenSigFirstTimeoutTime" BU_SG_REL_ BBM SG_ 925 MainBeamRequest_status_ISig_4 3000;
BA_REL_ "GenSigTimeoutTime" BU_SG_REL_ BBM SG_ 925 MainBeamRequest_status_ISig_4 450;
BA_REL_ "GenSigFirstTimeoutTime" BU_SG_REL_ DACU SG_ 925 MainBeamRequest_status_ISig_4 3000;
BA_REL_ "GenSigTimeoutTime" BU_SG_REL_ DACU SG_ 925 MainBeamRequest_status_ISig_4 600;
BA_REL_ "GenSigFirstTimeoutTime" BU_SG_REL_ CIOM SG_ 925 ExtraBBCraneStatus_ISig_4 3000;
BA_REL_ "GenSigTimeoutTime" BU_SG_REL_ CIOM SG_ 925 ExtraBBCraneStatus_ISig_4 450;
BA_REL_ "GenSigFirstTimeoutTime" BU_SG_REL_ BBM SG_ 925 ExtraBBCraneStatus_ISig_4 3000;
BA_REL_ "GenSigTimeoutTime" BU_SG_REL_ BBM SG_ 925 ExtraBBCraneStatus_ISig_4 450;
BA_REL_ "GenSigFirstTimeoutTime" BU_SG_REL_ EMS SG_ 925 AirCompressorStatus 3000;
BA_REL_ "GenSigTimeoutTime" BU_SG_REL_ EMS SG_ 925 AirCompressorStatus 450;
BA_REL_ "GenSigFirstTimeoutTime" BU_SG_REL_ BBM SG_ 925 AirCompressorStatus 3000;
BA_REL_ "GenSigTimeoutTime" BU_SG_REL_ BBM SG_ 925 AirCompressorStatus 450;
BA_REL_ "GenSigFirstTimeoutTime" BU_SG_REL_ TECU SG_ 925 TrailerABSStatus_ISig_4 3000;
BA_REL_ "GenSigTimeoutTime" BU_SG_REL_ TECU SG_ 925 TrailerABSStatus_ISig_4 450;
BA_REL_ "GenSigFirstTimeoutTime" BU_SG_REL_ IC3 SG_ 925 TrailerABSStatus_ISig_4 3000;
BA_REL_ "GenSigTimeoutTime" BU_SG_REL_ IC3 SG_ 925 TrailerABSStatus_ISig_4 450;
BA_REL_ "GenSigFirstTimeoutTime" BU_SG_REL_ EMS SG_ 925 TrailerABSStatus_ISig_4 3000;
BA_REL_ "GenSigTimeoutTime" BU_SG_REL_ EMS SG_ 925 TrailerABSStatus_ISig_4 450;
BA_REL_ "GenSigFirstTimeoutTime" BU_SG_REL_ DACU SG_ 925 TrailerABSStatus_ISig_4 3000;
BA_REL_ "GenSigTimeoutTime" BU_SG_REL_ DACU SG_ 925 TrailerABSStatus_ISig_4 500;
BA_REL_ "GenSigFirstTimeoutTime" BU_SG_REL_ EMS SG_ 925 RegenInhibitVehicleHeight_ISig_4 3000;
BA_REL_ "GenSigTimeoutTime" BU_SG_REL_ EMS SG_ 925 RegenInhibitVehicleHeight_ISig_4 450;
BA_REL_ "GenSigFirstTimeoutTime" BU_SG_REL_ BBM SG_ 925 PoorAirPressureInfo 3000;
BA_REL_ "GenSigTimeoutTime" BU_SG_REL_ BBM SG_ 925 PoorAirPressureInfo 450;
BA_REL_ "GenSigFirstTimeoutTime" BU_SG_REL_ IC3 SG_ 925 PoorAirPressureInfo 3000;
BA_REL_ "GenSigTimeoutTime" BU_SG_REL_ IC3 SG_ 925 PoorAirPressureInfo 500;
BA_REL_ "GenSigFirstTimeoutTime" BU_SG_REL_ BBM SG_ 925 FogLightRearRequest_stat 3000;
BA_REL_ "GenSigTimeoutTime" BU_SG_REL_ BBM SG_ 925 FogLightRearRequest_stat 450;
BA_REL_ "GenSigFirstTimeoutTime" BU_SG_REL_ BBM SG_ 925 MainBeam_cmd_ISig_4 3000;
BA_REL_ "GenSigTimeoutTime" BU_SG_REL_ BBM SG_ 925 MainBeam_cmd_ISig_4 600;
BA_REL_ "GenSigFirstTimeoutTime" BU_SG_REL_ IC3 SG_ 925 FrontParkBrakeOverrideInd_ISig_4 3000;
BA_REL_ "GenSigTimeoutTime" BU_SG_REL_ IC3 SG_ 925 FrontParkBrakeOverrideInd_ISig_4 450;
BA_REL_ "GenSigFirstTimeoutTime" BU_SG_REL_ BBM SG_ 849 AuxSwitchBbLoad4_cmd 3000;
BA_REL_ "GenSigTimeoutTime" BU_SG_REL_ BBM SG_ 849 AuxSwitchBbLoad4_cmd 300;
BA_REL_ "GenSigFirstTimeoutTime" BU_SG_REL_ CIOM SG_ 849 AuxSwitchBbLoad1_Status_ISig_4 3000;
BA_REL_ "GenSigTimeoutTime" BU_SG_REL_ CIOM SG_ 849 AuxSwitchBbLoad1_Status_ISig_4 300;
BA_REL_ "GenSigFirstTimeoutTime" BU_SG_REL_ BBM SG_ 849 AuxSwitchBbLoad1_Status_ISig_4 3000;
BA_REL_ "GenSigTimeoutTime" BU_SG_REL_ BBM SG_ 849 AuxSwitchBbLoad1_Status_ISig_4 300;
BA_REL_ "GenSigFirstTimeoutTime" BU_SG_REL_ BBM SG_ 849 AuxSwitchBbLoad3_cmd 3000;
BA_REL_ "GenSigTimeoutTime" BU_SG_REL_ BBM SG_ 849 AuxSwitchBbLoad3_cmd 300;
BA_REL_ "GenSigFirstTimeoutTime" BU_SG_REL_ IC3 SG_ 849 MainBeam_rqst 3000;
BA_REL_ "GenSigTimeoutTime" BU_SG_REL_ IC3 SG_ 849 MainBeam_rqst 300;
BA_REL_ "GenSigFirstTimeoutTime" BU_SG_REL_ IC3 SG_ 849 BatterySOCTrustLevel_ISig_4 3000;
BA_REL_ "GenSigTimeoutTime" BU_SG_REL_ IC3 SG_ 849 BatterySOCTrustLevel_ISig_4 300;
BA_REL_ "GenSigFirstTimeoutTime" BU_SG_REL_ CIOM SG_ 849 AuxSwitchBbLoad4_Status_ISig_4 3000;
BA_REL_ "GenSigTimeoutTime" BU_SG_REL_ CIOM SG_ 849 AuxSwitchBbLoad4_Status_ISig_4 300;
BA_REL_ "GenSigFirstTimeoutTime" BU_SG_REL_ BBM SG_ 849 AuxSwitchBbLoad4_Status_ISig_4 3000;
BA_REL_ "GenSigTimeoutTime" BU_SG_REL_ BBM SG_ 849 AuxSwitchBbLoad4_Status_ISig_4 300;
BA_REL_ "GenSigFirstTimeoutTime" BU_SG_REL_ BBM SG_ 849 BrakeLightConvoy_rqst_ISig_4 3000;
BA_REL_ "GenSigTimeoutTime" BU_SG_REL_ BBM SG_ 849 BrakeLightConvoy_rqst_ISig_4 500;
BA_REL_ "GenSigFirstTimeoutTime" BU_SG_REL_ CIOM SG_ 849 DoorWarningLight_cmd_ISig_4 3000;
BA_REL_ "GenSigTimeoutTime" BU_SG_REL_ CIOM SG_ 849 DoorWarningLight_cmd_ISig_4 300;
BA_REL_ "GenSigFirstTimeoutTime" BU_SG_REL_ IC3 SG_ 849 BlackOutandConvoyMode_rqst_ISig_ 3000;
BA_REL_ "GenSigTimeoutTime" BU_SG_REL_ IC3 SG_ 849 BlackOutandConvoyMode_rqst_ISig_ 300;
BA_REL_ "GenSigFirstTimeoutTime" BU_SG_REL_ DACU SG_ 849 BlackOutandConvoyMode_rqst_ISig_ 3000;
BA_REL_ "GenSigTimeoutTime" BU_SG_REL_ DACU SG_ 849 BlackOutandConvoyMode_rqst_ISig_ 300;
BA_REL_ "GenSigFirstTimeoutTime" BU_SG_REL_ BBM SG_ 849 BlackOutandConvoyMode_rqst_ISig_ 3000;
BA_REL_ "GenSigTimeoutTime" BU_SG_REL_ BBM SG_ 849 BlackOutandConvoyMode_rqst_ISig_ 300;
BA_REL_ "GenSigFirstTimeoutTime" BU_SG_REL_ BBM SG_ 849 DirIndicatorRqstLights_stat 3000;
BA_REL_ "GenSigTimeoutTime" BU_SG_REL_ BBM SG_ 849 DirIndicatorRqstLights_stat 300;
BA_REL_ "GenSigFirstTimeoutTime" BU_SG_REL_ BBM SG_ 849 DippedBeamRequest_status 3000;
BA_REL_ "GenSigTimeoutTime" BU_SG_REL_ BBM SG_ 849 DippedBeamRequest_status 300;
BA_REL_ "GenSigFirstTimeoutTime" BU_SG_REL_ CIOM SG_ 849 AuxSwitchBbLoad3_Status_ISig_4 3000;
BA_REL_ "GenSigTimeoutTime" BU_SG_REL_ CIOM SG_ 849 AuxSwitchBbLoad3_Status_ISig_4 300;
BA_REL_ "GenSigFirstTimeoutTime" BU_SG_REL_ BBM SG_ 849 AuxSwitchBbLoad3_Status_ISig_4 3000;
BA_REL_ "GenSigTimeoutTime" BU_SG_REL_ BBM SG_ 849 AuxSwitchBbLoad3_Status_ISig_4 300;
BA_REL_ "GenSigFirstTimeoutTime" BU_SG_REL_ CIOM SG_ 849 DoorInstepLight_cmd_ISig_4 3000;
BA_REL_ "GenSigTimeoutTime" BU_SG_REL_ CIOM SG_ 849 DoorInstepLight_cmd_ISig_4 300;
BA_REL_ "GenSigFirstTimeoutTime" BU_SG_REL_ BBM SG_ 849 DRLRequest_status 3000;
BA_REL_ "GenSigTimeoutTime" BU_SG_REL_ BBM SG_ 849 DRLRequest_status 300;
BA_REL_ "GenSigFirstTimeoutTime" BU_SG_REL_ BBM SG_ 849 AuxSwitchBbLoad6_Status_ISig_4 3000;
BA_REL_ "GenSigTimeoutTime" BU_SG_REL_ BBM SG_ 849 AuxSwitchBbLoad6_Status_ISig_4 300;
BA_REL_ "GenSigFirstTimeoutTime" BU_SG_REL_ CIOM SG_ 849 AuxSwitchBbLoad6_Status_ISig_4 3000;
BA_REL_ "GenSigTimeoutTime" BU_SG_REL_ CIOM SG_ 849 AuxSwitchBbLoad6_Status_ISig_4 300;
BA_REL_ "GenSigFirstTimeoutTime" BU_SG_REL_ CIOM SG_ 849 AuxSwitchBbLoad2_Status_ISig_4 3000;
BA_REL_ "GenSigTimeoutTime" BU_SG_REL_ CIOM SG_ 849 AuxSwitchBbLoad2_Status_ISig_4 300;
BA_REL_ "GenSigFirstTimeoutTime" BU_SG_REL_ BBM SG_ 849 AuxSwitchBbLoad2_Status_ISig_4 3000;
BA_REL_ "GenSigTimeoutTime" BU_SG_REL_ BBM SG_ 849 AuxSwitchBbLoad2_Status_ISig_4 300;
BA_REL_ "GenSigFirstTimeoutTime" BU_SG_REL_ BBM SG_ 849 AuxSwitchBbLoad5_cmd 3000;
BA_REL_ "GenSigTimeoutTime" BU_SG_REL_ BBM SG_ 849 AuxSwitchBbLoad5_cmd 300;
BA_REL_ "GenSigFirstTimeoutTime" BU_SG_REL_ BBM SG_ 849 PBReleaseInhibit_EPBState_ISig_4 3000;
BA_REL_ "GenSigTimeoutTime" BU_SG_REL_ BBM SG_ 849 PBReleaseInhibit_EPBState_ISig_4 300;
BA_REL_ "GenSigFirstTimeoutTime" BU_SG_REL_ IC3 SG_ 849 ExtStaticTrailerBrake_Stat_ISig_ 3000;
BA_REL_ "GenSigTimeoutTime" BU_SG_REL_ IC3 SG_ 849 ExtStaticTrailerBrake_Stat_ISig_ 300;
BA_REL_ "GenSigFirstTimeoutTime" BU_SG_REL_ BBM SG_ 849 ExtStaticTrailerBrake_Stat_ISig_ 3000;
BA_REL_ "GenSigTimeoutTime" BU_SG_REL_ BBM SG_ 849 ExtStaticTrailerBrake_Stat_ISig_ 300;
BA_REL_ "GenSigFirstTimeoutTime" BU_SG_REL_ CIOM SG_ 849 AuxSwitchBbLoad5_Status_ISig_4 3000;
BA_REL_ "GenSigTimeoutTime" BU_SG_REL_ CIOM SG_ 849 AuxSwitchBbLoad5_Status_ISig_4 300;
BA_REL_ "GenSigFirstTimeoutTime" BU_SG_REL_ BBM SG_ 849 AuxSwitchBbLoad5_Status_ISig_4 3000;
BA_REL_ "GenSigTimeoutTime" BU_SG_REL_ BBM SG_ 849 AuxSwitchBbLoad5_Status_ISig_4 300;
BA_REL_ "GenSigFirstTimeoutTime" BU_SG_REL_ IC3 SG_ 849 DoubleFrontAxleSteeringWarning_I 3000;
BA_REL_ "GenSigTimeoutTime" BU_SG_REL_ IC3 SG_ 849 DoubleFrontAxleSteeringWarning_I 300;
BA_REL_ "GenSigFirstTimeoutTime" BU_SG_REL_ BBM SG_ 849 AuxSwitchBbLoad6_cmd 3000;
BA_REL_ "GenSigTimeoutTime" BU_SG_REL_ BBM SG_ 849 AuxSwitchBbLoad6_cmd 300;
BA_REL_ "GenSigFirstTimeoutTime" BU_SG_REL_ IC3 SG_ 849 AcceleratorPedalTestStatus 3000;
BA_REL_ "GenSigTimeoutTime" BU_SG_REL_ IC3 SG_ 849 AcceleratorPedalTestStatus 300;
BA_REL_ "GenSigFirstTimeoutTime" BU_SG_REL_ TECU SG_ 735 CCSetSpeed_ISig_4 3000;
BA_REL_ "GenSigTimeoutTime" BU_SG_REL_ TECU SG_ 735 CCSetSpeed_ISig_4 210;
BA_REL_ "GenSigFirstTimeoutTime" BU_SG_REL_ BBM SG_ 735 CCSetSpeed_ISig_4 3000;
BA_REL_ "GenSigTimeoutTime" BU_SG_REL_ BBM SG_ 735 CCSetSpeed_ISig_4 210;
BA_REL_ "GenSigFirstTimeoutTime" BU_SG_REL_ DACU SG_ 735 CCSetSpeed_ISig_4 3000;
BA_REL_ "GenSigTimeoutTime" BU_SG_REL_ DACU SG_ 735 CCSetSpeed_ISig_4 600;
BA_REL_ "GenSigFirstTimeoutTime" BU_SG_REL_ IC3 SG_ 735 CCSetSpeed_ISig_4 3000;
BA_REL_ "GenSigTimeoutTime" BU_SG_REL_ IC3 SG_ 735 CCSetSpeed_ISig_4 210;
BA_REL_ "GenSigFirstTimeoutTime" BU_SG_REL_ BBM SG_ 735 AcceleratorPedalQuality_ISig_4 3000;
BA_REL_ "GenSigTimeoutTime" BU_SG_REL_ BBM SG_ 735 AcceleratorPedalQuality_ISig_4 210;
BA_REL_ "GenSigFirstTimeoutTime" BU_SG_REL_ IC3 SG_ 735 AcceleratorPedalQuality_ISig_4 3000;
BA_REL_ "GenSigTimeoutTime" BU_SG_REL_ IC3 SG_ 735 AcceleratorPedalQuality_ISig_4 210;
BA_REL_ "GenSigFirstTimeoutTime" BU_SG_REL_ CIOM SG_ 735 CCStates_ISig_4 3000;
BA_REL_ "GenSigTimeoutTime" BU_SG_REL_ CIOM SG_ 735 CCStates_ISig_4 210;
BA_REL_ "GenSigFirstTimeoutTime" BU_SG_REL_ DACU SG_ 735 CCStates_ISig_4 3000;
BA_REL_ "GenSigTimeoutTime" BU_SG_REL_ DACU SG_ 735 CCStates_ISig_4 210;
BA_REL_ "GenSigFirstTimeoutTime" BU_SG_REL_ IC3 SG_ 735 CCStates_ISig_4 3000;
BA_REL_ "GenSigTimeoutTime" BU_SG_REL_ IC3 SG_ 735 CCStates_ISig_4 210;
BA_REL_ "GenSigFirstTimeoutTime" BU_SG_REL_ BBM SG_ 735 CCStates_ISig_4 3000;
BA_REL_ "GenSigTimeoutTime" BU_SG_REL_ BBM SG_ 735 CCStates_ISig_4 210;
BA_REL_ "GenSigFirstTimeoutTime" BU_SG_REL_ IC3 SG_ 735 CCIOM_ParkBrakeAlert_ISig_4 3000;
BA_REL_ "GenSigTimeoutTime" BU_SG_REL_ IC3 SG_ 735 CCIOM_ParkBrakeAlert_ISig_4 210;
BA_REL_ "GenSigFirstTimeoutTime" BU_SG_REL_ DACU SG_ 735 CCDeactivationWarning 3000;
BA_REL_ "GenSigTimeoutTime" BU_SG_REL_ DACU SG_ 735 CCDeactivationWarning 210;
BA_REL_ "GenSigFirstTimeoutTime" BU_SG_REL_ BBM SG_ 735 PrimaryAcctrPedalPosition_ISig_4 3000;
BA_REL_ "GenSigTimeoutTime" BU_SG_REL_ BBM SG_ 735 PrimaryAcctrPedalPosition_ISig_4 210;
BA_REL_ "GenSigFirstTimeoutTime" BU_SG_REL_ IC3 SG_ 735 CCNotificationReq 3000;
BA_REL_ "GenSigTimeoutTime" BU_SG_REL_ IC3 SG_ 735 CCNotificationReq 210;
BA_REL_ "GenSigFirstTimeoutTime" BU_SG_REL_ CIOM SG_ 735 AcceleratorPedalStatus_ISig_4 3000;
BA_REL_ "GenSigTimeoutTime" BU_SG_REL_ CIOM SG_ 735 AcceleratorPedalStatus_ISig_4 210;
BA_REL_ "GenSigFirstTimeoutTime" BU_SG_REL_ BBM SG_ 735 AcceleratorPedalStatus_ISig_4 3000;
BA_REL_ "GenSigTimeoutTime" BU_SG_REL_ BBM SG_ 735 AcceleratorPedalStatus_ISig_4 210;
BA_REL_ "GenSigFirstTimeoutTime" BU_SG_REL_ CIOM SG_ 735 LoadDistributionRequestedACK_ISi 3000;
BA_REL_ "GenSigTimeoutTime" BU_SG_REL_ CIOM SG_ 735 LoadDistributionRequestedACK_ISi 210;
BA_REL_ "GenSigFirstTimeoutTime" BU_SG_REL_ CIOM SG_ 735 ElectricalLoadReduction_rqst_ISi 3000;
BA_REL_ "GenSigTimeoutTime" BU_SG_REL_ CIOM SG_ 735 ElectricalLoadReduction_rqst_ISi 500;
BA_REL_ "GenSigFirstTimeoutTime" BU_SG_REL_ BBM SG_ 735 FifthWheelLockingInformation_ISi 3000;
BA_REL_ "GenSigTimeoutTime" BU_SG_REL_ BBM SG_ 735 FifthWheelLockingInformation_ISi 500;
BA_REL_ "GenSigFirstTimeoutTime" BU_SG_REL_ IC3 SG_ 735 FifthWheelLockingInformation_ISi 3000;
BA_REL_ "GenSigTimeoutTime" BU_SG_REL_ IC3 SG_ 735 FifthWheelLockingInformation_ISi 500;
BA_REL_ "GenSigFirstTimeoutTime" BU_SG_REL_ DACU SG_ 729 CCBSetSpeed 3000;
BA_REL_ "GenSigTimeoutTime" BU_SG_REL_ DACU SG_ 729 CCBSetSpeed 180;
BA_REL_ "GenSigFirstTimeoutTime" BU_SG_REL_ TECU SG_ 729 CCBSetSpeed 3000;
BA_REL_ "GenSigTimeoutTime" BU_SG_REL_ TECU SG_ 729 CCBSetSpeed 180;
BA_REL_ "GenSigFirstTimeoutTime" BU_SG_REL_ IC3 SG_ 729 ASLNotificationReq 3000;
BA_REL_ "GenSigTimeoutTime" BU_SG_REL_ IC3 SG_ 729 ASLNotificationReq 180;
BA_REL_ "GenSigFirstTimeoutTime" BU_SG_REL_ IC3 SG_ 729 GearRangeUnengaged_ISig_4 3000;
BA_REL_ "GenSigTimeoutTime" BU_SG_REL_ IC3 SG_ 729 GearRangeUnengaged_ISig_4 180;
BA_REL_ "GenSigFirstTimeoutTime" BU_SG_REL_ DACU SG_ 729 LaneChangeStatus_ISig_4 3000;
BA_REL_ "GenSigTimeoutTime" BU_SG_REL_ DACU SG_ 729 LaneChangeStatus_ISig_4 180;
BA_REL_ "GenSigFirstTimeoutTime" BU_SG_REL_ IC3 SG_ 729 LaneChangeStatus_ISig_4 3000;
BA_REL_ "GenSigTimeoutTime" BU_SG_REL_ IC3 SG_ 729 LaneChangeStatus_ISig_4 180;
BA_REL_ "GenSigFirstTimeoutTime" BU_SG_REL_ CIOM SG_ 729 ASLStates 3000;
BA_REL_ "GenSigTimeoutTime" BU_SG_REL_ CIOM SG_ 729 ASLStates 180;
BA_REL_ "GenSigFirstTimeoutTime" BU_SG_REL_ IC3 SG_ 729 ASLStates 3000;
BA_REL_ "GenSigTimeoutTime" BU_SG_REL_ IC3 SG_ 729 ASLStates 180;
BA_REL_ "GenSigFirstTimeoutTime" BU_SG_REL_ IC3 SG_ 729 ASLSetSpeed 3000;
BA_REL_ "GenSigTimeoutTime" BU_SG_REL_ IC3 SG_ 729 ASLSetSpeed 180;
BA_REL_ "GenSigFirstTimeoutTime" BU_SG_REL_ BBM SG_ 729 LongMotionDirection_ISig_4 3000;
BA_REL_ "GenSigTimeoutTime" BU_SG_REL_ BBM SG_ 729 LongMotionDirection_ISig_4 180;
BA_REL_ "GenSigFirstTimeoutTime" BU_SG_REL_ CIOM SG_ 729 LongMotionDirection_ISig_4 3000;
BA_REL_ "GenSigTimeoutTime" BU_SG_REL_ CIOM SG_ 729 LongMotionDirection_ISig_4 120;
BA_REL_ "GenSigFirstTimeoutTime" BU_SG_REL_ CIOM SG_ 729 LongMotionDirectionQual_ISig_4 3000;
BA_REL_ "GenSigTimeoutTime" BU_SG_REL_ CIOM SG_ 729 LongMotionDirectionQual_ISig_4 120;
VAL_ 1234 Trailer2TPMTireInfo_LeakageWarn_ 7 "TPMTireLeakageWarn_NotAvailable" 6 "TPMTireLeakageWarn_Error" 5 "TPMTireLeakageWarn_Spare3" 4 "TPMTireLeakageWarn_Spare2" 3 "TPMTireLeakageWarn_Spare1" 2 "TPMTireLeakageWarn_FastLeakageDetected" 1 "TPMTireLeakageWarn_SlowLeakageDetected" 0 "TPMTireLeakageWarn_NoLeakageDetected" ;
VAL_ 1234 Trailer2TPMTireInfo_PresWarn_ISi 7 "TPMPressureWarning_NotAvailable" 6 "TPMPressureWarning_Error" 5 "TPMPressureWarning_Spare" 4 "TPMPressureWarning_ExtremeUnderPressure" 3 "TPMPressureWarning_UnderPressure" 2 "TPMPressureWarning_NoWarningPressure" 1 "TPMPressureWarning_OverPressure" 0 "TPMPressureWarning_ExtremeOverPressure" ;
VAL_ 1234 Trailer2TPMTireInfo_Battery_ISig 7 "TPMBatteryStatus_NotAvailable" 6 "TPMBatteryStatus_Error" 5 "TPMBatteryStatus_Spare3" 4 "TPMBatteryStatus_Spare2" 3 "TPMBatteryStatus_Spare1" 2 "TPMBatteryStatus_BatteryVeryLow" 1 "TPMBatteryStatus_BatteryLow" 0 "TPMBatteryStatus_BatteryOK" ;
VAL_ 1234 Trailer2TPMTireInfo_Active_ISig_ 3 "TPMTireActive_NotAvailable" 2 "TPMTireActive_Error" 1 "TPMTireActive_TireActivePositioned" 0 "TPMTireActive_TireNotActive" ;
VAL_ 1231 Trailer1TPMTireInfo_Battery_ISig 7 "TPMBatteryStatus_NotAvailable" 6 "TPMBatteryStatus_Error" 5 "TPMBatteryStatus_Spare3" 4 "TPMBatteryStatus_Spare2" 3 "TPMBatteryStatus_Spare1" 2 "TPMBatteryStatus_BatteryVeryLow" 1 "TPMBatteryStatus_BatteryLow" 0 "TPMBatteryStatus_BatteryOK" ;
VAL_ 1231 Trailer1TPMTireInfo_PresWarn_ISi 7 "TPMPressureWarning_NotAvailable" 6 "TPMPressureWarning_Error" 5 "TPMPressureWarning_Spare" 4 "TPMPressureWarning_ExtremeUnderPressure" 3 "TPMPressureWarning_UnderPressure" 2 "TPMPressureWarning_NoWarningPressure" 1 "TPMPressureWarning_OverPressure" 0 "TPMPressureWarning_ExtremeOverPressure" ;
VAL_ 1231 Trailer1TPMTireInfo_LeakageWarn_ 7 "TPMTireLeakageWarn_NotAvailable" 6 "TPMTireLeakageWarn_Error" 5 "TPMTireLeakageWarn_Spare3" 4 "TPMTireLeakageWarn_Spare2" 3 "TPMTireLeakageWarn_Spare1" 2 "TPMTireLeakageWarn_FastLeakageDetected" 1 "TPMTireLeakageWarn_SlowLeakageDetected" 0 "TPMTireLeakageWarn_NoLeakageDetected" ;
VAL_ 1231 TPMPosOfWMResp_VehiclePos_ISig_4 7 "TPMVehiclePos_NotAvailable" 6 "TPMVehiclePos_Error" 5 "TPMVehiclePos_Trailer5Vehicle" 4 "TPMVehiclePos_Trailer4Vehicle" 3 "TPMVehiclePos_Trailer3Vehicle" 2 "TPMVehiclePos_Trailer2Vehicle" 1 "TPMVehiclePos_Trailer1Vehicle" 0 "TPMVehiclePos_TruckVehicle" ;
VAL_ 1231 Trailer1TPMTireInfo_Active_ISig_ 3 "TPMTireActive_NotAvailable" 2 "TPMTireActive_Error" 1 "TPMTireActive_TireActivePositioned" 0 "TPMTireActive_TireNotActive" ;
VAL_ 1231 TPMPosOfWMResp_Status_ISig_4 7 "TPMPosStatusResp_NotAvailable" 6 "TPMPosStatusResp_Error" 5 "TPMPosStatusResp_Spare2" 4 "TPMPosStatusResp_Spare1" 3 "TPMPosStatusResp_PositionedOK" 2 "TPMPosStatusResp_Timeout" 1 "TPMPosStatusResp_Progressing" 0 "TPMPosStatusResp_NotActive" ;
VAL_ 1403 TruckTPMAxlTireCfg_Axle2_ISig_4 7 "TPMAxleConfig_NotAvailable" 6 "TPMAxleConfig_Error" 5 "TPMAxleConfig_Spare" 4 "TPMAxleConfig_RearAxleWith4Tires" 3 "TPMAxleConfig_RearAxleWith2Tires" 2 "TPMAxleConfig_FrontAxleWith4Tires" 1 "TPMAxleConfig_FrontAxleWith2Tires" 0 "TPMAxleConfig_NotPresent" ;
VAL_ 1403 TruckTPMAxlTireCfg_Axle1_ISig_4 7 "TPMAxleConfig_NotAvailable" 6 "TPMAxleConfig_Error" 5 "TPMAxleConfig_Spare" 4 "TPMAxleConfig_RearAxleWith4Tires" 3 "TPMAxleConfig_RearAxleWith2Tires" 2 "TPMAxleConfig_FrontAxleWith4Tires" 1 "TPMAxleConfig_FrontAxleWith2Tires" 0 "TPMAxleConfig_NotPresent" ;
VAL_ 1403 TruckTPMAxlTireCfg_Axle5_ISig_4 7 "TPMAxleConfig_NotAvailable" 6 "TPMAxleConfig_Error" 5 "TPMAxleConfig_Spare" 4 "TPMAxleConfig_RearAxleWith4Tires" 3 "TPMAxleConfig_RearAxleWith2Tires" 2 "TPMAxleConfig_FrontAxleWith4Tires" 1 "TPMAxleConfig_FrontAxleWith2Tires" 0 "TPMAxleConfig_NotPresent" ;
VAL_ 1403 TruckTPMAxlTireCfg_Axle4_ISig_4 7 "TPMAxleConfig_NotAvailable" 6 "TPMAxleConfig_Error" 5 "TPMAxleConfig_Spare" 4 "TPMAxleConfig_RearAxleWith4Tires" 3 "TPMAxleConfig_RearAxleWith2Tires" 2 "TPMAxleConfig_FrontAxleWith4Tires" 1 "TPMAxleConfig_FrontAxleWith2Tires" 0 "TPMAxleConfig_NotPresent" ;
VAL_ 1403 TruckTPMThresCfg_AxleNr_ISig_4 7 "TPMAxleNr_NotAvailable" 6 "TPMAxleNr_Error" 5 "TPMAxleNr_Axle5" 4 "TPMAxleNr_Axle4" 3 "TPMAxleNr_Axle3" 2 "TPMAxleNr_Axle2" 1 "TPMAxleNr_Axle1" 0 "TPMAxleNr_NoRequest" ;
VAL_ 1403 TruckTPMAxlTireCfg_Axle3_ISig_4 7 "TPMAxleConfig_NotAvailable" 6 "TPMAxleConfig_Error" 5 "TPMAxleConfig_Spare" 4 "TPMAxleConfig_RearAxleWith4Tires" 3 "TPMAxleConfig_RearAxleWith2Tires" 2 "TPMAxleConfig_FrontAxleWith4Tires" 1 "TPMAxleConfig_FrontAxleWith2Tires" 0 "TPMAxleConfig_NotPresent" ;
VAL_ 1402 Trailer2TPMType_ISig_4 3 "TPMTrailerType_NotAvailable" 2 "TPMTrailerType_Error" 1 "TPMTrailerType_ISO11992Trailer" 0 "TPMTrailerType_SKFWirelessTrailer" ;
VAL_ 1402 Trailer2TPMAxlTireCfg_Axle1_ISig 7 "TPMAxleConfig_NotAvailable" 6 "TPMAxleConfig_Error" 5 "TPMAxleConfig_Spare" 4 "TPMAxleConfig_RearAxleWith4Tires" 3 "TPMAxleConfig_RearAxleWith2Tires" 2 "TPMAxleConfig_FrontAxleWith4Tires" 1 "TPMAxleConfig_FrontAxleWith2Tires" 0 "TPMAxleConfig_NotPresent" ;
VAL_ 1402 Trailer2TPMAxlTireCfg_Axle3_ISig 7 "TPMAxleConfig_NotAvailable" 6 "TPMAxleConfig_Error" 5 "TPMAxleConfig_Spare" 4 "TPMAxleConfig_RearAxleWith4Tires" 3 "TPMAxleConfig_RearAxleWith2Tires" 2 "TPMAxleConfig_FrontAxleWith4Tires" 1 "TPMAxleConfig_FrontAxleWith2Tires" 0 "TPMAxleConfig_NotPresent" ;
VAL_ 1402 Trailer2TPMAxlTireCfg_Axle2_ISig 7 "TPMAxleConfig_NotAvailable" 6 "TPMAxleConfig_Error" 5 "TPMAxleConfig_Spare" 4 "TPMAxleConfig_RearAxleWith4Tires" 3 "TPMAxleConfig_RearAxleWith2Tires" 2 "TPMAxleConfig_FrontAxleWith4Tires" 1 "TPMAxleConfig_FrontAxleWith2Tires" 0 "TPMAxleConfig_NotPresent" ;
VAL_ 1402 Trailer2TPMAxlTireCfg_Axle5_ISig 7 "TPMAxleConfig_NotAvailable" 6 "TPMAxleConfig_Error" 5 "TPMAxleConfig_Spare" 4 "TPMAxleConfig_RearAxleWith4Tires" 3 "TPMAxleConfig_RearAxleWith2Tires" 2 "TPMAxleConfig_FrontAxleWith4Tires" 1 "TPMAxleConfig_FrontAxleWith2Tires" 0 "TPMAxleConfig_NotPresent" ;
VAL_ 1402 Trailer2TPMAxlTireCfg_Axle4_ISig 7 "TPMAxleConfig_NotAvailable" 6 "TPMAxleConfig_Error" 5 "TPMAxleConfig_Spare" 4 "TPMAxleConfig_RearAxleWith4Tires" 3 "TPMAxleConfig_RearAxleWith2Tires" 2 "TPMAxleConfig_FrontAxleWith4Tires" 1 "TPMAxleConfig_FrontAxleWith2Tires" 0 "TPMAxleConfig_NotPresent" ;
VAL_ 1402 Trailer2TPMThresCfg_AxleNr_ISig_ 7 "TPMAxleNr_NotAvailable" 6 "TPMAxleNr_Error" 5 "TPMAxleNr_Axle5" 4 "TPMAxleNr_Axle4" 3 "TPMAxleNr_Axle3" 2 "TPMAxleNr_Axle2" 1 "TPMAxleNr_Axle1" 0 "TPMAxleNr_NoRequest" ;
VAL_ 1401 Trailer1TPMAxlTireCfg_Axle1_ISig 7 "TPMAxleConfig_NotAvailable" 6 "TPMAxleConfig_Error" 5 "TPMAxleConfig_Spare" 4 "TPMAxleConfig_RearAxleWith4Tires" 3 "TPMAxleConfig_RearAxleWith2Tires" 2 "TPMAxleConfig_FrontAxleWith4Tires" 1 "TPMAxleConfig_FrontAxleWith2Tires" 0 "TPMAxleConfig_NotPresent" ;
VAL_ 1401 Trailer1TPMAxlTireCfg_Axle2_ISig 7 "TPMAxleConfig_NotAvailable" 6 "TPMAxleConfig_Error" 5 "TPMAxleConfig_Spare" 4 "TPMAxleConfig_RearAxleWith4Tires" 3 "TPMAxleConfig_RearAxleWith2Tires" 2 "TPMAxleConfig_FrontAxleWith4Tires" 1 "TPMAxleConfig_FrontAxleWith2Tires" 0 "TPMAxleConfig_NotPresent" ;
VAL_ 1401 Trailer1TPMAxlTireCfg_Axle5_ISig 7 "TPMAxleConfig_NotAvailable" 6 "TPMAxleConfig_Error" 5 "TPMAxleConfig_Spare" 4 "TPMAxleConfig_RearAxleWith4Tires" 3 "TPMAxleConfig_RearAxleWith2Tires" 2 "TPMAxleConfig_FrontAxleWith4Tires" 1 "TPMAxleConfig_FrontAxleWith2Tires" 0 "TPMAxleConfig_NotPresent" ;
VAL_ 1401 Trailer1TPMType_ISig_4 3 "TPMTrailerType_NotAvailable" 2 "TPMTrailerType_Error" 1 "TPMTrailerType_ISO11992Trailer" 0 "TPMTrailerType_SKFWirelessTrailer" ;
VAL_ 1401 MaintResetFailureCause 31 "MaintResetFailCause_NotAvailable" 30 "MaintResetFailCause_Error" 29 "MaintResetFailCause_Cond_29_Specific19" 28 "MaintResetFailCause_Cond_28_Specific18" 27 "MaintResetFailCause_Cond_27_Specific17" 26 "MaintResetFailCause_Cond_26_Specific16" 25 "MaintResetFailCause_Cond_25_Specific15" 24 "MaintResetFailCause_Cond_24_Specific14" 23 "MaintResetFailCause_Cond_23_Specific13" 22 "MaintResetFailCause_Cond_22_Specific12" 21 "MaintResetFailCause_Cond_21_Specific11" 20 "MaintResetFailCause_Cond_20_Specific10" 19 "MaintResetFailCause_Cond_19_Specific9" 18 "MaintResetFailCause_Cond_18_Specific8" 17 "MaintResetFailCause_Cond_17_Specific7" 16 "MaintResetFailCause_Cond_16_Specific6" 15 "MaintResetFailCause_Cond_15_Specific5" 14 "MaintResetFailCause_Cond_14_Specific4" 13 "MaintResetFailCause_Cond_13_Specific3" 12 "MaintResetFailCause_Cond_12_Specific2" 11 "MaintResetFailCause_Cond_11_Specific1" 10 "MaintResetFailCause_Cond_10_Specific0" 9 "MaintResetFailCause_Cond_09_spare4" 8 "MaintResetFailCause_Cond_08_spare3" 7 "MaintResetFailCause_Cond_07_spare2" 6 "MaintResetFailCause_Cond_06_spare1" 5 "MaintResetFailCause_Cond_05_InvalidSelection" 4 "MaintResetFailCause_Cond_04_ComponentResetTime_Out" 3 "MaintResetFailCause_Cond_03_RejectedByComponent" 2 "MaintResetFailCause_Cond_02_InvalidDate_Time" 1 "MaintResetFailCause_Cond_01_InvalidEngineTime" 0 "MaintResetFailCause_Cond_00_InvalidVehicleDistance" ;
VAL_ 1401 Trailer1TPMThresCfg_AxleNr_ISig_ 7 "TPMAxleNr_NotAvailable" 6 "TPMAxleNr_Error" 5 "TPMAxleNr_Axle5" 4 "TPMAxleNr_Axle4" 3 "TPMAxleNr_Axle3" 2 "TPMAxleNr_Axle2" 1 "TPMAxleNr_Axle1" 0 "TPMAxleNr_NoRequest" ;
VAL_ 1401 Trailer1TPMAxlTireCfg_Axle4_ISig 7 "TPMAxleConfig_NotAvailable" 6 "TPMAxleConfig_Error" 5 "TPMAxleConfig_Spare" 4 "TPMAxleConfig_RearAxleWith4Tires" 3 "TPMAxleConfig_RearAxleWith2Tires" 2 "TPMAxleConfig_FrontAxleWith4Tires" 1 "TPMAxleConfig_FrontAxleWith2Tires" 0 "TPMAxleConfig_NotPresent" ;
VAL_ 1401 Trailer1TPMAxlTireCfg_Axle3_ISig 7 "TPMAxleConfig_NotAvailable" 6 "TPMAxleConfig_Error" 5 "TPMAxleConfig_Spare" 4 "TPMAxleConfig_RearAxleWith4Tires" 3 "TPMAxleConfig_RearAxleWith2Tires" 2 "TPMAxleConfig_FrontAxleWith4Tires" 1 "TPMAxleConfig_FrontAxleWith2Tires" 0 "TPMAxleConfig_NotPresent" ;
VAL_ 1246 FogLight_Front_cmd_ISig_4 3 "InactiveActive_NotAvailable" 2 "InactiveActive_Error" 1 "InactiveActive_Active" 0 "InactiveActive_Inactive" ;
VAL_ 1243 SelfStartAssistSwitch_Input_ISig 3 "Request_NotAvailable" 2 "Request_Error" 1 "Request_RequestActive" 0 "Request_NotRequested" ;
VAL_ 1243 BatterySOCAlertRawData_rqst_ISig 7 "BatterySOCAlert_rqst_NotAvailable" 6 "BatterySOCAlert_rqst_ErrorIndicator" 5 "BatterySOCAlert_rqst_SpareValue_02" 4 "BatterySOCAlert_rqst_SpareValue_01" 3 "BatterySOCAlert_rqst_SpareValue" 2 "BatterySOCAlert_rqst_CriticalAlert" 1 "BatterySOCAlert_rqst_PreAlert" 0 "BatterySOCAlert_rqst_NoAlertRequested" ;
VAL_ 1243 LivBatDisconnectDetectStat_ISig_ 3 "LivBatDisconnectDetectStat_Not_Available" 2 "LivBatDisconnectDetectStat_Error" 1 "LivBatDisconnectDetectStat_Battery_Disconnected" 0 "LivBatDisconnectDetectStat_Battery_NotDisconnected" ;
VAL_ 1243 SelfStartAssist_stat_ISig_4 3 "Request_NotAvailable" 2 "Request_Error" 1 "Request_RequestActive" 0 "Request_NotRequested" ;
VAL_ 1243 JumpChargeAlert_stat_ISig_4 7 "JumpChargeAlert_stat_NotAvailable" 6 "JumpChargeAlert_stat_Error" 5 "JumpChargeAlert_stat_Spare3" 4 "JumpChargeAlert_stat_Spare2" 3 "JumpChargeAlert_stat_Spare1" 2 "JumpChargeAlert_stat_InternalFailure" 1 "JumpChargeAlert_stat_JumpVoltage_tooHigh" 0 "JumpChargeAlert_stat_NoAlert" ;
VAL_ 1243 GChargerStatus_ISig_4 7 "GridCharger_stat_NotAvailable" 6 "GridCharger_stat_Error" 5 "GridCharger_stat_Spare3" 4 "GridCharger_stat_GridChargerFailure" 3 "GridCharger_stat_MaintenanceCharging" 2 "GridCharger_stat_Charging" 1 "GridCharger_stat_Connected" 0 "GridCharger_stat_NotConnected" ;
VAL_ 1243 ShortStopHeater_status_ISig_4 7 "ShortStopHeaterStatus_NotAvailable" 6 "ShortStopHeaterStatus_Error" 5 "ShortStopHeaterStatus_Spare3" 4 "ShortStopHeaterStatus_Spare2" 3 "ShortStopHeaterStatus_Spare1" 2 "ShortStopHeaterStatus_ActivatedAndPumpNotEngaged" 1 "ShortStopHeaterStatus_ActivatedAndPumpEngaged" 0 "ShortStopHeaterStatus_NotActivated" ;
VAL_ 1243 StartBatteryDisplay_stat_ISig_4 7 "StartBatteryDisplay_NotAvailable" 6 "StartBatteryDisplay_Error" 5 "StartBatteryDisplay_StartBattery_ShortCircuit" 4 "StartBatteryDisplay_StartBattery_OverVoltage" 3 "StartBatteryDisplay_StartBattery_OpenCircuit" 2 "StartBatteryDisplay_StartBattery_Issue" 1 "StartBatteryDisplay_StartBattery_Charged" 0 "StartBatteryDisplay_StartBattery_Charging" ;
VAL_ 1059 ReducedLoadMode_stat_ISig_4 3 "ReducedLoadMode_stat_NotAvailable" 2 "ReducedLoadMode_stat_Error" 1 "ReducedLoadMode_stat_ReducedLoadMode" 0 "ReducedLoadMode_stat_NormalMode" ;
VAL_ 1059 BatterySOCAlert_rqst_ISig_4 7 "BatterySOCAlert_rqst_NotAvailable" 6 "BatterySOCAlert_rqst_ErrorIndicator" 5 "BatterySOCAlert_rqst_SpareValue_02" 4 "BatterySOCAlert_rqst_SpareValue_01" 3 "BatterySOCAlert_rqst_SpareValue" 2 "BatterySOCAlert_rqst_CriticalAlert" 1 "BatterySOCAlert_rqst_PreAlert" 0 "BatterySOCAlert_rqst_NoAlertRequested" ;
VAL_ 925 MaintOilQuality 7 "OilQuality_NotAvailable" 6 "OilQuality_Error" 5 "OilQuality_NoSelectionMade" 4 "OilQuality_VDS4" 3 "OilQuality_VDS3" 2 "OilQuality_VDS2" 1 "OilQuality_VDSVDS3WithFixedInterval" 0 "OilQuality_NonVDS_VDS4WithFixedInterval" ;
VAL_ 925 ECSLimpHomeNotification_ISig_4 7 "ECSLimpHomeNotification_NotAvailable" 6 "ECSLimpHomeNotification_Error" 5 "ECSLimpHomeNotification_LimpHomeMode5" 4 "ECSLimpHomeNotification_LimpHomeMode4" 3 "ECSLimpHomeNotification_LimpHomeMode3" 2 "ECSLimpHomeNotification_LimpHomeMode2" 1 "ECSLimpHomeNotification_LimpHomeMode1" 0 "ECSLimpHomeNotification_NoLimpHomeMode" ;
VAL_ 925 MaintenanceResetStatus 7 "MaintenanceResetStatus_NotAvailable" 6 "MaintenanceResetStatus_Error" 5 "MaintenanceResetStatus_ResetFailed" 4 "MaintenanceResetStatus_ResetSuccessful" 3 "MaintenanceResetStatus_ResetOngoing" 2 "MaintenanceResetStatus_Spare_02" 1 "MaintenanceResetStatus_Spare_01" 0 "MaintenanceResetStatus_NoResetRequested" ;
VAL_ 925 FirstAxleLowerPrioSelected_ISig_ 7 "FirstAxleLowerPrio_NotAvailable" 6 "FirstAxleLowerPrio_Error" 5 "FirstAxleLowerPrio_Reserved_03" 4 "FirstAxleLowerPrio_Reserved_02" 3 "FirstAxleLowerPrio_Reserved_01" 2 "FirstAxleLowerPrio_Reserved" 1 "FirstAxleLowerPrio_LowerPusher" 0 "FirstAxleLowerPrio_LowerTag" ;
VAL_ 925 MaintOilReset 3 "Request_NotAvailable" 2 "Request_Error" 1 "Request_RequestActive" 0 "Request_NotRequested" ;
VAL_ 925 RssInhibStartEngine_rqst 3 "OffOn_NotAvailable" 2 "OffOn_Error" 1 "OffOn_On" 0 "OffOn_Off" ;
VAL_ 925 PositionLightRequest_status 3 "OffOn_NotAvailable" 2 "OffOn_Error" 1 "OffOn_On" 0 "OffOn_Off" ;
VAL_ 925 ExtraBBTailLiftStatus_ISig_4 3 "InactiveActive_NotAvailable" 2 "InactiveActive_Error" 1 "InactiveActive_Active" 0 "InactiveActive_Inactive" ;
VAL_ 925 MaintenanceNotification_ISig_4 7 "MaintenanceNotification_NotAvailable" 6 "MaintenanceNotification_Error" 5 "MaintenanceNotification_Spare_02" 4 "MaintenanceNotification_Spare_01" 3 "MaintenanceNotification_Spare" 2 "MaintenanceNotification_WarningNotification" 1 "MaintenanceNotification_PreWarningNotification" 0 "MaintenanceNotification_NoNotification" ;
VAL_ 925 ExtraBBSlidable5thWheelStatus 3 "InactiveActive_NotAvailable" 2 "InactiveActive_Error" 1 "InactiveActive_Active" 0 "InactiveActive_Inactive" ;
VAL_ 925 ParkBrakeReleasePossible_stat 3 "ParkBrakeReleasePossible_stat_NotAvailable" 2 "ParkBrakeReleasePossible_stat_Error" 1 "ParkBrakeReleasePossible_stat_Possible_PressureOK" 0 "ParkBrakeReleasePossible_stat_NotPossible_LowerPressure" ;
VAL_ 925 LoadDistributionALDChangeACK_ISi 7 "LoadDistributionALDChangeACK_NotAvailable" 6 "LoadDistributionALDChangeACK_Error" 5 "LoadDistributionALDChangeACK_SystemDeniedVersatile" 4 "LoadDistributionALDChangeACK_Spare_01" 3 "LoadDistributionALDChangeACK_Spare" 2 "LoadDistributionALDChangeACK_LoadShiftDeniedOverspeed" 1 "LoadDistributionALDChangeACK_ChangeAcknowledged" 0 "LoadDistributionALDChangeACK_NoAction" ;
VAL_ 925 ParkBrakeWorkshopMode_ISig_4 3 "ParkBrakeWorkshopMode_NotAvailable" 2 "ParkBrakeWorkshopMode_Error" 1 "ParkBrakeWorkshopMode_WorkshopMode" 0 "ParkBrakeWorkshopMode_NormalMode" ;
VAL_ 925 ExtraBBContainerUnlockStatus 3 "InactiveActive_NotAvailable" 2 "InactiveActive_Error" 1 "InactiveActive_Active" 0 "InactiveActive_Inactive" ;
VAL_ 925 MainBeamRequest_status_ISig_4 3 "OffOn_NotAvailable" 2 "OffOn_Error" 1 "OffOn_On" 0 "OffOn_Off" ;
VAL_ 925 ExtraBBCraneStatus_ISig_4 7 "ExtraBBCraneStatus_NotAvailable" 6 "ExtraBBCraneStatus_Error" 5 "ExtraBBCraneStatus_Spare_02" 4 "ExtraBBCraneStatus_Spare_01" 3 "ExtraBBCraneStatus_Spare" 2 "ExtraBBCraneStatus_Active" 1 "ExtraBBCraneStatus_Enable" 0 "ExtraBBCraneStatus_Disable" ;
VAL_ 925 AirCompressorStatus 3 "InactiveActive_NotAvailable" 2 "InactiveActive_Error" 1 "InactiveActive_Active" 0 "InactiveActive_Inactive" ;
VAL_ 925 TrailerABSStatus_ISig_4 3 "TrailerABSStatus_NotAvailable" 2 "TrailerABSStatus_ErrorIndicator" 1 "TrailerABSStatus_OK" 0 "TrailerABSStatus_Error" ;
VAL_ 925 RegenInhibitVehicleHeight_ISig_4 3 "ActiveStatus_NotAvailable" 2 "ActiveStatus_Error" 1 "ActiveStatus_Active" 0 "ActiveStatus_NotActive" ;
VAL_ 925 PoorAirPressureInfo 3 "PoorAirPressureInfo_NotAvailable" 2 "PoorAirPressureInfo_Error" 1 "PoorAirPressureInfo_PoorAirPressure" 0 "PoorAirPressureInfo_NormalPressure" ;
VAL_ 925 FogLightRearRequest_stat 3 "InactiveActive_NotAvailable" 2 "InactiveActive_Error" 1 "InactiveActive_Active" 0 "InactiveActive_Inactive" ;
VAL_ 925 MainBeam_cmd_ISig_4 7 "MainBeam_cmd_NotAvailable" 6 "MainBeam_cmd_SpareValue_03" 5 "MainBeam_cmd_SpareValue_02" 4 "MainBeam_cmd_SpareValue_01" 3 "MainBeam_cmd_SpareValue" 2 "MainBeam_cmd_MainBeamFlashOn" 1 "MainBeam_cmd_MainBeamOn" 0 "MainBeam_cmd_MainBeamOff" ;
VAL_ 925 FrontParkBrakeOverrideInd_ISig_4 3 "FrontParkBrakeOverrideInd_NotAvailable" 2 "FrontParkBrakeOverrideInd_Error" 1 "FrontParkBrakeOverrideInd_FailedToOverride" 0 "FrontParkBrakeOverrideInd_OK" ;
VAL_ 849 AuxSwitchBbLoad4_cmd 3 "NotDriven_Driven_NotAvailable" 2 "NotDriven_Driven_Error" 1 "NotDriven_Driven_Driven" 0 "NotDriven_Driven_NotDriven" ;
VAL_ 849 AuxSwitchBbLoad1_Status_ISig_4 3 "InactiveActive_NotAvailable" 2 "InactiveActive_Error" 1 "InactiveActive_Active" 0 "InactiveActive_Inactive" ;
VAL_ 849 AuxSwitchBbLoad3_cmd 3 "NotDriven_Driven_NotAvailable" 2 "NotDriven_Driven_Error" 1 "NotDriven_Driven_Driven" 0 "NotDriven_Driven_NotDriven" ;
VAL_ 849 MainBeam_rqst 7 "MainBeam_rqst_NotAvailable" 6 "MainBeam_rqst_Error" 5 "MainBeam_rqst_SpareValue3" 4 "MainBeam_rqst_SpareValue2" 3 "MainBeam_rqst_SpareValue1" 2 "MainBeam_rqst_FlashToPassRequest" 1 "MainBeam_rqst_MainBeamRequest" 0 "MainBeam_rqst_DippedBeamRequest" ;
VAL_ 849 AuxSwitchBbLoad4_Status_ISig_4 3 "InactiveActive_NotAvailable" 2 "InactiveActive_Error" 1 "InactiveActive_Active" 0 "InactiveActive_Inactive" ;
VAL_ 849 BrakeLightConvoy_rqst_ISig_4 3 "OffOn_NotAvailable" 2 "OffOn_Error" 1 "OffOn_On" 0 "OffOn_Off" ;
VAL_ 849 DoorWarningLight_cmd_ISig_4 3 "OffOn_NotAvailable" 2 "OffOn_Error" 1 "OffOn_On" 0 "OffOn_Off" ;
VAL_ 849 BlackOutandConvoyMode_rqst_ISig_ 7 "BlackOutandConvoyMode_rqst_NotAvailable" 6 "BlackOutandConvoyMode_rqst_Error" 5 "BlackOutandConvoyMode_rqst_SpareValue_02" 4 "BlackOutandConvoyMode_rqst_SpareValue_01" 3 "BlackOutandConvoyMode_rqst_SpareValue" 2 "BlackOutandConvoyMode_rqst_ConvoyMode" 1 "BlackOutandConvoyMode_rqst_BlackOutMode" 0 "BlackOutandConvoyMode_rqst_NormalMode" ;
VAL_ 849 DirIndicatorRqstLights_stat 7 "DirIndicatorRqstLights_stat_NotAvailable" 6 "DirIndicatorRqstLights_stat_Error" 5 "DirIndicatorRqstLights_stat_SpareValue_01" 4 "DirIndicatorRqstLights_stat_SpareValue" 3 "DirIndicatorRqstLights_stat_RightAndLeftON_Hazard" 2 "DirIndicatorRqstLights_stat_RightDirectionIndicatorON" 1 "DirIndicatorRqstLights_stat_LeftDirectionIndicatorON" 0 "DirIndicatorRqstLights_stat_DirectionIndicatorsOFF" ;
VAL_ 849 DippedBeamRequest_status 3 "OffOn_NotAvailable" 2 "OffOn_Error" 1 "OffOn_On" 0 "OffOn_Off" ;
VAL_ 849 AuxSwitchBbLoad3_Status_ISig_4 3 "InactiveActive_NotAvailable" 2 "InactiveActive_Error" 1 "InactiveActive_Active" 0 "InactiveActive_Inactive" ;
VAL_ 849 DoorInstepLight_cmd_ISig_4 3 "OffOn_NotAvailable" 2 "OffOn_Error" 1 "OffOn_On" 0 "OffOn_Off" ;
VAL_ 849 DRLRequest_status 3 "OffOn_NotAvailable" 2 "OffOn_Error" 1 "OffOn_On" 0 "OffOn_Off" ;
VAL_ 849 AuxSwitchBbLoad6_Status_ISig_4 3 "InactiveActive_NotAvailable" 2 "InactiveActive_Error" 1 "InactiveActive_Active" 0 "InactiveActive_Inactive" ;
VAL_ 849 AuxSwitchBbLoad2_Status_ISig_4 3 "InactiveActive_NotAvailable" 2 "InactiveActive_Error" 1 "InactiveActive_Active" 0 "InactiveActive_Inactive" ;
VAL_ 849 AuxSwitchBbLoad5_cmd 3 "NotDriven_Driven_NotAvailable" 2 "NotDriven_Driven_Error" 1 "NotDriven_Driven_Driven" 0 "NotDriven_Driven_NotDriven" ;
VAL_ 849 PBReleaseInhibit_EPBState_ISig_4 7 "PBReleaseInhibit_State_NotAvailable" 6 "PBReleaseInhibit_State_Error" 5 "PBReleaseInhibit_State_AutoReleaseCommandBeingInhibited" 4 "PBReleaseInhibit_State_XPRReleaseCommandBeingInhibited" 3 "PBReleaseInhibit_State_ManualReleaseCommandBeingInhibited" 2 "PBReleaseInhibit_State_Active" 1 "PBReleaseInhibit_State_FullyOperationalNotActive" 0 "PBReleaseInhibit_State_NotOperational" ;
VAL_ 849 ExtStaticTrailerBrake_Stat_ISig_ 3 "InactiveActive_NotAvailable" 2 "InactiveActive_Error" 1 "InactiveActive_Active" 0 "InactiveActive_Inactive" ;
VAL_ 849 AuxSwitchBbLoad5_Status_ISig_4 3 "InactiveActive_NotAvailable" 2 "InactiveActive_Error" 1 "InactiveActive_Active" 0 "InactiveActive_Inactive" ;
VAL_ 849 DoubleFrontAxleSteeringWarning_I 3 "DoubleFrontAxleSteeringWarning_NotAvailiable" 2 "DoubleFrontAxleSteeringWarning_Error" 1 "DoubleFrontAxleSteeringWarning_DoubleFrAxleSteeringBackupMode" 0 "DoubleFrontAxleSteeringWarning_NoRequest" ;
VAL_ 849 AuxSwitchBbLoad6_cmd 3 "NotDriven_Driven_NotAvailable" 2 "NotDriven_Driven_Error" 1 "NotDriven_Driven_Driven" 0 "NotDriven_Driven_NotDriven" ;
VAL_ 849 AcceleratorPedalTestStatus 7 "AcceleratorPedalTestStatus_NotAvailable" 6 "AcceleratorPedalTestStatus_Error" 5 "AcceleratorPedalTestStatus_TestFailed" 4 "AcceleratorPedalTestStatus_TestFinished" 3 "AcceleratorPedalTestStatus_Step3" 2 "AcceleratorPedalTestStatus_Step2" 1 "AcceleratorPedalTestStatus_Step1" 0 "AcceleratorPedalTestStatus_Inactive" ;
VAL_ 735 AcceleratorPedalQuality_ISig_4 3 "PrimaryAcceleratorPedalQuality_NotAvailable" 2 "PrimaryAcceleratorPedalQuality_ErrorMode" 1 "PrimaryAcceleratorPedalQuality_DowngradedMode" 0 "PrimaryAcceleratorPedalQuality_NormalMode" ;
VAL_ 735 CCStates_ISig_4 15 "CCStates_NotAvailable" 14 "CCStates_Error" 13 "CCStates_Spare_7" 12 "CCStates_Spare_6" 11 "CCStates_Spare_5" 10 "CCStates_Spare_4" 9 "CCStates_Spare_3" 8 "CCStates_Spare_2" 7 "CCStates_Spare_1" 6 "CCStates_Driver_Override" 5 "CCStates_Set" 4 "CCStates_Resume" 3 "CCStates_Decelerate" 2 "CCStates_Accelerate" 1 "CCStates_Hold" 0 "CCStates_OffDisabled" ;
VAL_ 735 CCIOM_ParkBrakeAlert_ISig_4 3 "Alert_NotAvailable" 2 "Alert_Error" 1 "Alert_Alert" 0 "Alert_NoAlert" ;
VAL_ 735 CCDeactivationWarning 3 "OffOn_NotAvailable" 2 "OffOn_Error" 1 "OffOn_On" 0 "OffOn_Off" ;
VAL_ 735 CCNotificationReq 15 "CCNotificationReq_NotAvailable" 14 "CCNotificationReq_Error" 13 "CCNotificationReq_Spare_6" 12 "CCNotificationReq_Spare_5" 11 "CCNotificationReq_Spare_4" 10 "CCNotificationReq_Spare_3" 9 "CCNotificationReq_Spare_2" 8 "CCNotificationReq_activation_failed_brake_pedal_check" 7 "CCNotificationReq_Deactivation_warning" 6 "CCNotificationReq_Activation_failed_error" 5 "CCNotificationReq_Activation_stop_braking" 4 "CCNotificationReq_Activation_failed_low_speed" 3 "CCNotificationReq_Overridden_manual_braking" 2 "CCNotificationReq_Overridden_manual_acceleration" 1 "CCNotificationReq_Overspeed_warning" 0 "CCNotificationReq_No_request" ;
VAL_ 735 AcceleratorPedalStatus_ISig_4 7 "AcceleratorPedalStatus_NotAvailable" 6 "AcceleratorPedalStatus_Error" 5 "AcceleratorPedalStatus_Spare3" 4 "AcceleratorPedalStatus_Spare2" 3 "AcceleratorPedalStatus_Spare1" 2 "AcceleratorPedalStatus_PrimAndSecPedalInhibited" 1 "AcceleratorPedalStatus_SecPedActPrimPedNotAct" 0 "AcceleratorPedalStatus_SecPedNotActPrimPedAct" ;
VAL_ 735 LoadDistributionRequestedACK_ISi 7 "LoadDistributionRequestedACK_NotAvailable" 6 "LoadDistributionRequestedACK_Error" 5 "LoadDistributionRequestedACK_SystemDeniedVersatile" 4 "LoadDistributionRequestedACK_Reserved2" 3 "LoadDistributionRequestedACK_Reserved1" 2 "LoadDistributionRequestedACK_LoadShiftDeniedFALIMOverload" 1 "LoadDistributionRequestedACK_ChangeAcknowledged" 0 "LoadDistributionRequestedACK_NoAction" ;
VAL_ 735 ElectricalLoadReduction_rqst_ISi 7 "ElectricalLoadReduction_rqst_NotAvailable" 6 "ElectricalLoadReduction_rqst_Error" 5 "ElectricalLoadReduction_rqst_SpareValue_02" 4 "ElectricalLoadReduction_rqst_SpareValue_01" 3 "ElectricalLoadReduction_rqst_SpareValue" 2 "ElectricalLoadReduction_rqst_Level2Request" 1 "ElectricalLoadReduction_rqst_Level1Request" 0 "ElectricalLoadReduction_rqst_NoRequest" ;
VAL_ 735 FifthWheelLockingInformation_ISi 15 "FifthWheelLockingInformation_NotAvailable" 14 "FifthWheelLockingInformation_Error" 13 "FifthWheelLockingInformation_Spare_07" 12 "FifthWheelLockingInformation_Spare_06" 11 "FifthWheelLockingInformation_Spare_05" 10 "FifthWheelLockingInformation_Spare_04" 9 "FifthWheelLockingInformation_Spare_03" 8 "FifthWheelLockingInformation_Spare_02" 7 "FifthWheelLockingInformation_Spare_01" 6 "FifthWheelLockingInformation_Spare" 5 "FifthWheelLockingInformation_5thWheelSystemError" 4 "FifthWheelLockingInformation_TrailerNotCorrectlyCoupled" 3 "FifthWheelLockingInformation_HandleLockedTrailerRightConnected" 2 "FifthWheelLockingInformation_KingPinEndPosTrailerPlateInContact" 1 "FifthWheelLockingInformation_TrailerPlateInContactW_semitrailer" 0 "FifthWheelLockingInformation_TractorAlone" ;
VAL_ 729 ASLNotificationReq 7 "ASLNotificationReq_NotAvailable" 6 "ASLNotificationReq_Error" 5 "ASLNotificationReq_Spare" 4 "ASLNotificationReq_DeactivationWarning" 3 "ASLNotificationReq_DeactivationFailedError" 2 "ASLNotificationReq_ActivationFailedLowSpeed" 1 "ASLNotificationReq_OverspeedWarning" 0 "ASLNotificationReq_NoRequest" ;
VAL_ 729 GearRangeUnengaged_ISig_4 3 "GearInhibation_NotAvailable" 2 "GearInhibation_Error" 1 "GearInhibation_GearChangeInhibited" 0 "GearInhibation_NoInhibation" ;
VAL_ 729 LaneChangeStatus_ISig_4 15 "LaneChangeStatus_NotAvailable" 14 "LaneChangeStatus_Error" 13 "LaneChangeStatus_Spare11" 12 "LaneChangeStatus_Spare10" 11 "LaneChangeStatus_Spare9" 10 "LaneChangeStatus_Spare8" 9 "LaneChangeStatus_Spare7" 8 "LaneChangeStatus_Spare6" 7 "LaneChangeStatus_Spare5" 6 "LaneChangeStatus_Spare4" 5 "LaneChangeStatus_Spare3" 4 "LaneChangeStatus_Spare2" 3 "LaneChangeStatus_Spare1" 2 "LaneChangeStatus_RightLaneChangeIntention" 1 "LaneChangeStatus_LeftLaneChangeIntention" 0 "LaneChangeStatus_NotActive" ;
VAL_ 729 ASLStates 15 "ASLStates_NotAvailable" 14 "ASLStates_Error" 6 "ASLStates_Driver_override" 5 "ASLStates_Set" 4 "ASLStates_Resume" 3 "ASLStates_Decelerate" 2 "ASLStates_Accelerate" 1 "ASLStates_Hold" 0 "ASLStates_Off_disabled" ;
VAL_ 729 LongMotionDirection_ISig_4 7 "LongMotionDirection_NotAvailable" 6 "LongMotionDirection_Error" 5 "LongMotionDirection_Spare3" 4 "LongMotionDirection_Spare2" 3 "LongMotionDirection_Undetermined" 2 "LongMotionDirection_Backward" 1 "LongMotionDirection_Forward" 0 "LongMotionDirection_Stationary" ;
VAL_ 729 LongMotionDirectionQual_ISig_4 3 "LongMotionDirectionQual_NotAvailable" 2 "LongMotionDirectionQual_OEM_Reserved2" 1 "LongMotionDirectionQual_OEM_Reserved1" 0 "LongMotionDirectionQual_UsingGearbox" ;
SIG_GROUP_ 1234 Trailer2TPMTireInfo_sg_ISig_4 1 : Trailer2TPMTireInfo_LeakageWarn_ Trailer2TPMTireInfo_RefPres_ISig Trailer2TPMTireInfo_PresWarn_ISi Trailer2TPMTireInfo_Pressure_ISi Trailer2TPMTireInfo_Temperature_ Trailer2TPMTireInfo_TireId_ISig_ Trailer2TPMTireInfo_Battery_ISig Trailer2TPMTireInfo_Active_ISig_;
SIG_GROUP_ 1231 TPMPosOfWMResp_sg_ISig_4 1 : TPMPosOfWMResp_VehiclePos_ISig_4 TPMPosOfWMResp_Status_ISig_4 TPMPosOfWMResp_TireId_ISig_4;
SIG_GROUP_ 1231 Trailer1TPMTireInfo_sg_ISig_4 1 : Trailer1TPMTireInfo_Battery_ISig Trailer1TPMTireInfo_Pressure_ISi Trailer1TPMTireInfo_PresWarn_ISi Trailer1TPMTireInfo_LeakageWarn_ Trailer1TPMTireInfo_TireId_ISig_ Trailer1TPMTireInfo_RefPres_ISig Trailer1TPMTireInfo_Temperature_ Trailer1TPMTireInfo_Active_ISig_;
SIG_GROUP_ 1403 TruckTPMAxlTireCfg_sg_ISig_4 1 : TruckTPMAxlTireCfg_Axle2_ISig_4 TruckTPMAxlTireCfg_Axle1_ISig_4 TruckTPMAxlTireCfg_Axle5_ISig_4 TruckTPMAxlTireCfg_Axle4_ISig_4 TruckTPMAxlTireCfg_Axle3_ISig_4;
SIG_GROUP_ 1403 TruckTPMThresCfg_sg_ISig_4 1 : TruckTPMThresCfg_OverPres_ISig_4 TruckTPMThresCfg_ExtUnderPres_IS TruckTPMThresCfg_AxleNr_ISig_4 TruckTPMThresCfg_UnderPres_ISig_ TruckTPMThresCfg_ExtOverPres_ISi;
SIG_GROUP_ 1402 Trailer2TPMAxlTireCfg_sg_ISig_4 1 : Trailer2TPMAxlTireCfg_Axle1_ISig Trailer2TPMAxlTireCfg_Axle3_ISig Trailer2TPMAxlTireCfg_Axle2_ISig Trailer2TPMAxlTireCfg_Axle5_ISig Trailer2TPMAxlTireCfg_Axle4_ISig;
SIG_GROUP_ 1402 Trailer2TPMThresCfg_sg_ISig_4 1 : Trailer2TPMThresCfg_OverPres_ISi Trailer2TPMThresCfg_AxleNr_ISig_ Trailer2TPMThresCfg_ExtOverPres_ Trailer2TPMThresCfg_UnderPres_IS Trailer2TPMThresCfg_ExtUnderPres;
SIG_GROUP_ 1401 Trailer1TPMAxlTireCfg_sg_ISig_4 1 : Trailer1TPMAxlTireCfg_Axle1_ISig Trailer1TPMAxlTireCfg_Axle2_ISig Trailer1TPMAxlTireCfg_Axle5_ISig Trailer1TPMAxlTireCfg_Axle4_ISig Trailer1TPMAxlTireCfg_Axle3_ISig;
SIG_GROUP_ 1401 Trailer1TPMThresCfg_sg_ISig_4 1 : Trailer1TPMThresCfg_ExtOverPres_ Trailer1TPMThresCfg_OverPres_ISi Trailer1TPMThresCfg_UnderPres_IS Trailer1TPMThresCfg_ExtUnderPres Trailer1TPMThresCfg_AxleNr_ISig_;
SIG_GROUP_ 1408 MaintService_sg_ISig_4_580 1 : MaintService_ServiceCalendarTime MaintService_EngTimeID_ISig_4_58 MaintService_DistID_ISig_4_580 MaintService_ServiceDistance_ISi MaintService_ServiceEngineTime_I MaintService_CalDateID_ISig_4_58;
SIG_GROUP_ 1398 MaintService_sg_ISig_4_576 1 : MaintService_ServiceEngineT_0000 MaintService_EngTimeID_ISig_4_57 MaintService_DistID_ISig_4_576 MaintService_ServiceDistanc_0000 MaintService_CalDateID_ISig_4_57 MaintService_ServiceCalenda_0000;
